VERSION ""

NS_ :

BS_:

BU_: PFAF_HS LVMPC_HS DCDC_HS AMP_HS VICM2_HS FICM_HS ARS_HS MCP_B_HS MCP_A_HS ICCM_OBD_HS SAS_HS ACCM_HS VLBS_HS EBCM_OBD_HS EDI_HS HPCC_HS VITM_OBD_HS PTAM_HS OBCM_HS VICM_HS HCP_HS FDCM_HS APPS_HS ICCM_HS EOCM_F_HS GPCM_HS FSCM_ITBC_HS SCM_HS ITBC_HS VCM_HS HMIM_HS FCP_HS VES_HS Dummy_HS MCP_C_HS RWS_HS ONSTAR_HS EPS_HS TestTool_HS MCP_HS BCP_HS ALC_HS AHL_AFL_HS SADS_HS EPB_HS FSCM_HS AFS_HS FCM_HS TCCM_HS RDCM_HS PTO_HS PCM_HS EBCM_HS ACC_HS BCM_HS TCM_HS ECM_HS

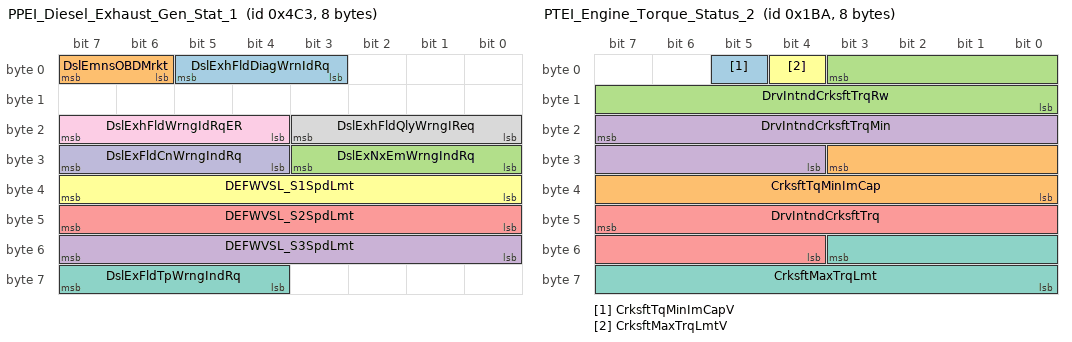
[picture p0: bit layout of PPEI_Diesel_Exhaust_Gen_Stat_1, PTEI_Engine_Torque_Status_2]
BO_ 1219 PPEI_Diesel_Exhaust_Gen_Stat_1: 8 ECM_HS
  SG_ DslExhFldDiagWrnIdRq: 5|3@0+ (1,0) [0|7] "" BCM_HS
  SG_ DslEmnsOBDMrkt: 7|2@0+ (1,0) [0|3] "" BCM_HS
  SG_ DslExNxEmWrngIndRq: 27|4@0+ (1,0) [0|15] "" BCM_HS
  SG_ DEFWVSL_S3SpdLmt: 55|8@0+ (1,0) [0|255] "km / h" BCM_HS
  SG_ DEFWVSL_S2SpdLmt: 47|8@0+ (1,0) [0|255] "km / h" BCM_HS
  SG_ DEFWVSL_S1SpdLmt: 39|8@0+ (1,0) [0|255] "km / h" BCM_HS
  SG_ DslExFldTpWrngIndRq: 63|4@0+ (1,0) [0|15] "" BCM_HS
  SG_ DslExhFldQlyWrngIReq: 19|4@0+ (1,0) [0|15] "" BCM_HS
  SG_ DslExhFldWrngIdRqER: 23|4@0+ (1,0) [0|15] "" BCM_HS FCP_HS ONSTAR_HS
  SG_ DslExFldCnWrngIndRq: 31|4@0+ (1,0) [0|15] "" BCM_HS

BO_ 372 Active_Rear_Steer_Fail_Indctn_HS: 1 ARS_HS
  SG_ ARSFlrIO: 0|1@0+ (1,0) [0|1] "" BCM_HS

BO_ 528 Brake_System_Autonomous_Info_HS: 4 EBCM_HS
  SG_ BrkSysAutBrkReqRC: 2|2@0+ (1,0) [0|3] "" FSCM_ITBC_HS
  SG_ BrkSysAutBrkReqPVal: 16|9@0+ (1,0) [0|511] "" FSCM_ITBC_HS
  SG_ BSABR_TrlBrkRq: 0|8@0+ (0.39215702,0) [0|100.00004] "%" FSCM_ITBC_HS
  SG_ BSABR_TrlBrkCntlIntRq: 8|1@0+ (1,0) [0|1] "" FSCM_ITBC_HS

BO_ 552 Thrml_Ref_Compressor_Status_1_HS: 4 ACCM_HS
  SG_ ThrmlRefCmpIGBTTmpV: 2|1@0+ (1,0) [0|1] "" VICM_HS
  SG_ ThrmlRefCmpIGBTTmp: 31|8@0+ (1,-40) [-40|215] "deg C" VICM_HS
  SG_ ThrmlRefCmpHiVltgInptV: 1|1@0+ (1,0) [0|1] "" VICM_HS
  SG_ ThrmlRefCmpHiVltgInpt: 23|8@0+ (4,0) [0|1020] "V" VICM_HS
  SG_ ThrmlRefCmpCPUHtSkTmpV: 0|1@0+ (1,0) [0|1] "" VICM_HS
  SG_ ThrmlRefCmpCPUHtSkTmp: 15|8@0+ (1,-40) [-40|215] "deg C" VICM_HS

BO_ 442 PTEI_Engine_Torque_Status_2: 8 ECM_HS
  SG_ CrksftTqMinImCapV: 5|1@0+ (1,0) [0|1] "" TCM_HS
  SG_ CrksftTqMinImCap: 27|12@0+ (0.5,-848) [-848|1199.5] "Nm" TCM_HS
  SG_ DrvIntndCrksftTrqRw: 3|12@0+ (0.5,-848) [-848|1199.5] "Nm" TCM_HS
  SG_ DrvIntndCrksftTrqMin: 23|12@0+ (0.5,-848) [-848|1199.5] "Nm" TCM_HS
  SG_ DrvIntndCrksftTrq: 47|12@0+ (0.5,-848) [-848|1199.5] "Nm" TCM_HS
  SG_ CrksftMaxTrqLmtV: 4|1@0+ (1,0) [0|1] "" TCM_HS
  SG_ CrksftMaxTrqLmt: 51|12@0+ (0.5,-848) [-848|1199.5] "Nm" TCM_HS

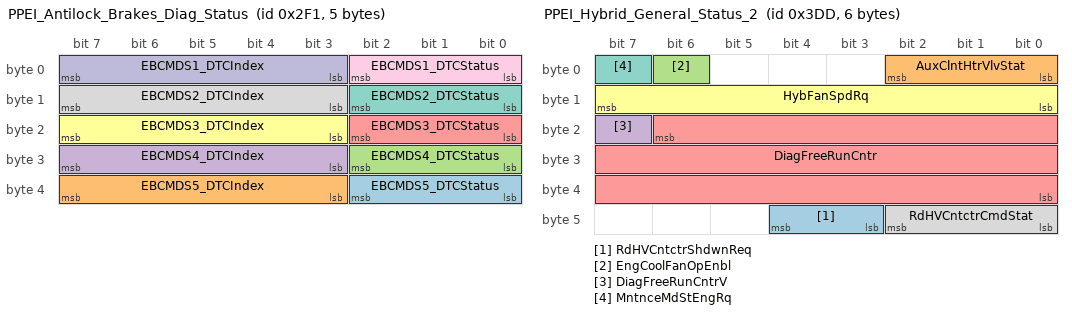
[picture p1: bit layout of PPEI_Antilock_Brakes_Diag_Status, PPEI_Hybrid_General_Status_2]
BO_ 753 PPEI_Antilock_Brakes_Diag_Status: 5 EBCM_HS
  SG_ EBCMDS5_DTCStatus: 34|3@0+ (1,0) [0|7] "" ECM_HS
  SG_ EBCMDS5_DTCIndex: 39|5@0+ (1,0) [0|31] "" ECM_HS
  SG_ EBCMDS4_DTCStatus: 26|3@0+ (1,0) [0|7] "" ECM_HS
  SG_ EBCMDS4_DTCIndex: 31|5@0+ (1,0) [0|31] "" ECM_HS
  SG_ EBCMDS3_DTCStatus: 18|3@0+ (1,0) [0|7] "" ECM_HS
  SG_ EBCMDS3_DTCIndex: 23|5@0+ (1,0) [0|31] "" ECM_HS
  SG_ EBCMDS2_DTCStatus: 10|3@0+ (1,0) [0|7] "" ECM_HS
  SG_ EBCMDS2_DTCIndex: 15|5@0+ (1,0) [0|31] "" ECM_HS
  SG_ EBCMDS1_DTCStatus: 2|3@0+ (1,0) [0|7] "" ECM_HS
  SG_ EBCMDS1_DTCIndex: 7|5@0+ (1,0) [0|31] "" ECM_HS

BO_ 989 PPEI_Hybrid_General_Status_2: 6 VICM_HS
  SG_ RdHVCntctrShdwnReq: 44|2@0+ (1,0) [0|3] "" HCP_HS
  SG_ AuxClntHtrVlvStat: 2|3@0+ (1,0) [0|7] "" PCM_HS ECM_HS
  SG_ EngCoolFanOpEnbl: 6|1@0+ (1,0) [0|1] "" PCM_HS ECM_HS
  SG_ DiagFreeRunCntrV: 23|1@0+ (1,0) [0|1] "" ECM_HS
  SG_ DiagFreeRunCntr: 22|23@0+ (1,0) [0|8388607] "min" ECM_HS
  SG_ HybFanSpdRq: 15|8@0+ (0.39215702,0) [0|100.00004] "%" PCM_HS ECM_HS
  SG_ MntnceMdStEngRq: 7|1@0+ (1,0) [0|1] "" ECM_HS
  SG_ RdHVCntctrCmdStat: 42|3@0+ (1,0) [0|7] "" HCP_HS

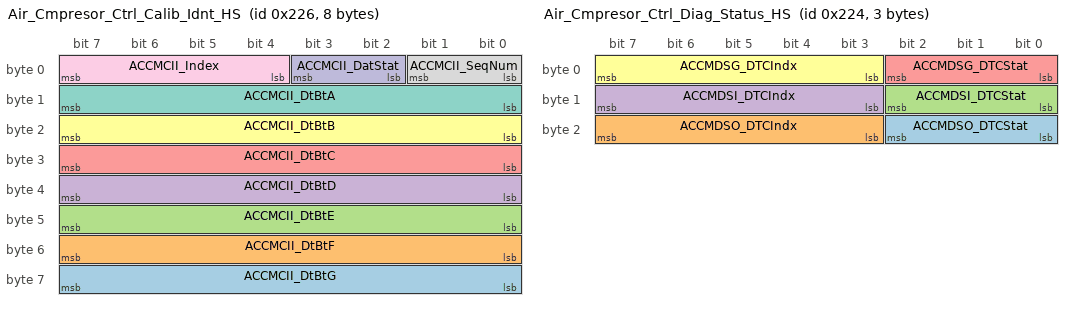
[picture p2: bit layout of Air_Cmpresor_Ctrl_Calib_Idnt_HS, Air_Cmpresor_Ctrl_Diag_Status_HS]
BO_ 550 Air_Cmpresor_Ctrl_Calib_Idnt_HS: 8 ACCM_HS
  SG_ ACCMCII_DtBtG: 63|8@0+ (1,0) [0|0] "" VICM_HS
  SG_ ACCMCII_DtBtF: 55|8@0+ (1,0) [0|0] "" VICM_HS
  SG_ ACCMCII_DtBtE: 47|8@0+ (1,0) [0|0] "" VICM_HS
  SG_ ACCMCII_DtBtD: 39|8@0+ (1,0) [0|0] "" VICM_HS
  SG_ ACCMCII_DtBtC: 31|8@0+ (1,0) [0|0] "" VICM_HS
  SG_ ACCMCII_DtBtB: 23|8@0+ (1,0) [0|0] "" VICM_HS
  SG_ ACCMCII_DtBtA: 15|8@0+ (1,0) [0|0] "" VICM_HS
  SG_ ACCMCII_SeqNum: 1|2@0+ (1,0) [0|3] "" VICM_HS
  SG_ ACCMCII_Index: 7|4@0+ (1,0) [0|15] "" VICM_HS
  SG_ ACCMCII_DatStat: 3|2@0+ (1,0) [0|3] "" VICM_HS

BO_ 548 Air_Cmpresor_Ctrl_Diag_Status_HS: 3 ACCM_HS
  SG_ ACCMDSO_DTCStat: 18|3@0+ (1,0) [0|7] "" VICM_HS
  SG_ ACCMDSO_DTCIndx: 23|5@0+ (1,0) [0|31] "" VICM_HS
  SG_ ACCMDSI_DTCStat: 10|3@0+ (1,0) [0|7] "" VICM_HS
  SG_ ACCMDSI_DTCIndx: 15|5@0+ (1,0) [0|31] "" VICM_HS
  SG_ ACCMDSG_DTCStat: 2|3@0+ (1,0) [0|7] "" VICM_HS
  SG_ ACCMDSG_DTCIndx: 7|5@0+ (1,0) [0|31] "" VICM_HS

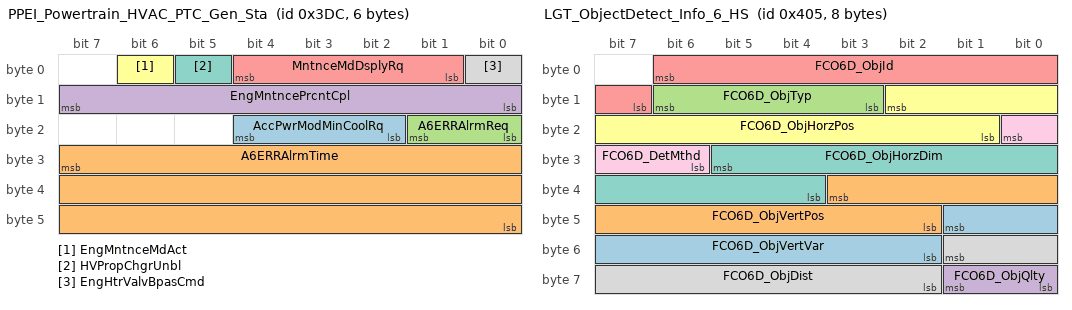
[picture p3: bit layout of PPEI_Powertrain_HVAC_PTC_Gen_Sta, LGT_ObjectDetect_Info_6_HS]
BO_ 988 PPEI_Powertrain_HVAC_PTC_Gen_Sta: 6 ECM_HS
  SG_ AccPwrModMinCoolRq: 20|3@0+ (1,0) [0|7] "" VICM_HS
  SG_ A6ERRAlrmTime: 31|24@0+ (1,0) [0|16777215] "min" VICM_HS
  SG_ A6ERRAlrmReq: 17|2@0+ (1,0) [0|3] "" VICM_HS
  SG_ EngMntncePrcntCpl: 15|8@0+ (0.39215702,0) [0|100.00004] "%" VICM_HS
  SG_ MntnceMdDsplyRq: 4|4@0+ (1,0) [0|15] "" VICM_HS
  SG_ EngMntnceMdAct: 6|1@0+ (1,0) [0|1] "" VICM_HS
  SG_ HVPropChgrUnbl: 5|1@0+ (1,0) [0|1] "" HCP_HS VICM_HS
  SG_ EngHtrValvBpasCmd: 0|1@0+ (1,0) [0|1] "" VICM_HS

BO_ 1029 LGT_ObjectDetect_Info_6_HS: 8 FCM_HS
  SG_ FCO6D_ObjVertVar: 41|8@0- (0.050000004,0) [-6.4000001|6.3500004] "deg" AHL_AFL_HS
  SG_ FCO6D_ObjVertPos: 35|10@0- (0.050000004,0) [-25.6|25.549999] "deg" AHL_AFL_HS
  SG_ FCO6D_ObjTyp: 14|4@0+ (1,0) [0|15] "" AHL_AFL_HS
  SG_ FCO6D_ObjQlty: 57|2@0+ (1,0) [0|3] "" AHL_AFL_HS
  SG_ FCO6D_ObjId: 6|8@0+ (1,0) [0|255] "" AHL_AFL_HS
  SG_ FCO6D_ObjHorzPos: 10|10@0- (0.050000004,0) [-25.6|25.549999] "deg" AHL_AFL_HS
  SG_ FCO6D_ObjHorzDim: 29|10@0+ (0.010000001,0) [0|10.23] "deg" AHL_AFL_HS
  SG_ FCO6D_ObjDist: 49|8@0+ (2,0) [0|510] "m" AHL_AFL_HS
  SG_ FCO6D_DetMthd: 16|3@0+ (1,0) [0|7] "" AHL_AFL_HS

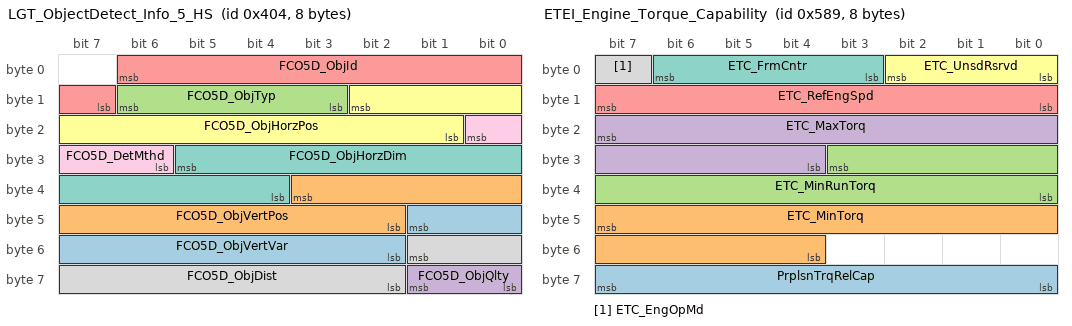
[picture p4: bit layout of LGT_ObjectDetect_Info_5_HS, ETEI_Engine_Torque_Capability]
BO_ 1028 LGT_ObjectDetect_Info_5_HS: 8 FCM_HS
  SG_ FCO5D_ObjVertVar: 41|8@0- (0.050000004,0) [-6.4000001|6.3500004] "deg" AHL_AFL_HS
  SG_ FCO5D_ObjVertPos: 35|10@0- (0.050000004,0) [-25.6|25.549999] "deg" AHL_AFL_HS
  SG_ FCO5D_ObjTyp: 14|4@0+ (1,0) [0|15] "" AHL_AFL_HS
  SG_ FCO5D_ObjQlty: 57|2@0+ (1,0) [0|3] "" AHL_AFL_HS
  SG_ FCO5D_ObjId: 6|8@0+ (1,0) [0|255] "" AHL_AFL_HS
  SG_ FCO5D_ObjHorzPos: 10|10@0- (0.050000004,0) [-25.6|25.549999] "deg" AHL_AFL_HS
  SG_ FCO5D_ObjHorzDim: 29|10@0+ (0.010000001,0) [0|10.23] "" AHL_AFL_HS
  SG_ FCO5D_ObjDist: 49|8@0+ (2,0) [0|510] "m" AHL_AFL_HS
  SG_ FCO5D_DetMthd: 16|3@0+ (1,0) [0|7] "" AHL_AFL_HS

BO_ 500 PPEI_Drv_Pref_Mode_Switch_Status: 6 ECM_HS
  SG_ EnhDrvMdSwChUseAct: 40|1@0+ (1,0) [0|1] "" EBCM_OBD_HS EBCM_HS
  SG_ EnhDrvSelMdSwStat: 42|2@0+ (1,0) [0|3] "" EBCM_OBD_HS EBCM_HS
  SG_ DrvSelMd8Stat: 17|1@0+ (1,0) [0|1] "" EBCM_OBD_HS EBCM_HS BCM_HS
  SG_ DrvSelMd8ReqDnd: 16|1@0+ (1,0) [0|1] "" BCM_HS
  SG_ DrvSelMd7Stat: 19|1@0+ (1,0) [0|1] "" EBCM_OBD_HS EBCM_HS BCM_HS
  SG_ DrvSelMd7ReqDnd: 18|1@0+ (1,0) [0|1] "" BCM_HS
  SG_ DrvSelMd6Stat: 21|1@0+ (1,0) [0|1] "" EBCM_OBD_HS EBCM_HS BCM_HS
  SG_ DrvSelMd6ReqDnd: 20|1@0+ (1,0) [0|1] "" BCM_HS
  SG_ DrvSelMd5Stat: 23|1@0+ (1,0) [0|1] "" EBCM_OBD_HS EBCM_HS BCM_HS
  SG_ DrvSelMd5ReqDnd: 22|1@0+ (1,0) [0|1] "" BCM_HS
  SG_ DrvSelMd4Stat: 9|1@0+ (1,0) [0|1] "" EBCM_OBD_HS EBCM_HS BCM_HS
  SG_ DrvSelMd4ReqDnd: 8|1@0+ (1,0) [0|1] "" BCM_HS
  SG_ DrvSelMd3Stat: 11|1@0+ (1,0) [0|1] "" EBCM_OBD_HS EBCM_HS BCM_HS
  SG_ DrvSelMd3ReqDnd: 10|1@0+ (1,0) [0|1] "" BCM_HS
  SG_ DrvSelMd2Stat: 13|1@0+ (1,0) [0|1] "" EBCM_OBD_HS EBCM_HS BCM_HS
  SG_ DrvSelMd2ReqDnd: 12|1@0+ (1,0) [0|1] "" BCM_HS
  SG_ DSMSS_DrvSelMd0Pn: 47|1@0+ (1,0) [0|1] "" EBCM_OBD_HS EBCM_HS BCM_HS
  SG_ DSMSS_DrvSelMd8Pn: 32|1@0+ (1,0) [0|1] "" EBCM_OBD_HS EBCM_HS BCM_HS
  SG_ DSMSS_DrvSelMd7Pn: 33|1@0+ (1,0) [0|1] "" EBCM_OBD_HS EBCM_HS BCM_HS
  SG_ DSMSS_DrvSelMd6Pn: 34|1@0+ (1,0) [0|1] "" EBCM_OBD_HS EBCM_HS BCM_HS
  SG_ DSMSS_DrvSelMd5Pn: 35|1@0+ (1,0) [0|1] "" EBCM_OBD_HS EBCM_HS BCM_HS
  SG_ DSMSS_DrvSelMd4Pn: 36|1@0+ (1,0) [0|1] "" EBCM_OBD_HS EBCM_HS BCM_HS
  SG_ DSMSS_DrvSelMd3Pn: 37|1@0+ (1,0) [0|1] "" EBCM_OBD_HS EBCM_HS BCM_HS
  SG_ DSMSS_DrvSelMd2Pn: 38|1@0+ (1,0) [0|1] "" EBCM_OBD_HS EBCM_HS BCM_HS
  SG_ DSMSS_DrvSelMd1Pn: 39|1@0+ (1,0) [0|1] "" EBCM_OBD_HS EBCM_HS BCM_HS
  SG_ DSMSS_DrvSelMd8Un: 24|1@0+ (1,0) [0|1] "" EBCM_OBD_HS EBCM_HS BCM_HS
  SG_ DSMSS_DrvSelMd7Un: 25|1@0+ (1,0) [0|1] "" EBCM_OBD_HS EBCM_HS BCM_HS
  SG_ DSMSS_DrvSelMd6Un: 26|1@0+ (1,0) [0|1] "" EBCM_OBD_HS EBCM_HS BCM_HS
  SG_ DSMSS_DrvSelMd5Un: 27|1@0+ (1,0) [0|1] "" EBCM_OBD_HS EBCM_HS BCM_HS
  SG_ DSMSS_DrvSelMd4Un: 28|1@0+ (1,0) [0|1] "" EBCM_OBD_HS EBCM_HS BCM_HS
  SG_ DSMSS_DrvSelMd3Un: 29|1@0+ (1,0) [0|1] "" EBCM_OBD_HS EBCM_HS BCM_HS
  SG_ DSMSS_DrvSelMd2Un: 30|1@0+ (1,0) [0|1] "" EBCM_OBD_HS EBCM_HS BCM_HS
  SG_ DSMSS_DrvSelMd1Un: 31|1@0+ (1,0) [0|1] "" EBCM_OBD_HS EBCM_HS BCM_HS
  SG_ DrvSelMd1ReqDnd: 14|1@0+ (1,0) [0|1] "" VICM_HS BCM_HS
  SG_ DrvSelMd1Stat: 15|1@0+ (1,0) [0|1] "" EBCM_OBD_HS EBCM_HS BCM_HS

BO_ 1417 ETEI_Engine_Torque_Capability: 8 ECM_HS
  SG_ PrplsnTrqRelCap: 63|8@0+ (0.5,0) [0|127.5] "%" TCM_HS
  SG_ ETC_MinTorq: 47|12@0+ (0.5,-848) [-848|1199.5] "Nm" TCM_HS HCP_HS BCP_HS
  SG_ ETC_MinRunTorq: 27|12@0+ (0.5,-848) [-848|1199.5] "Nm" TCM_HS HCP_HS BCP_HS
  SG_ ETC_MaxTorq: 23|12@0+ (0.5,-848) [-848|1199.5] "Nm" TCM_HS HCP_HS BCP_HS
  SG_ ETC_RefEngSpd: 15|8@0+ (32,0) [0|8160] "rpm" TCM_HS HCP_HS BCP_HS
  SG_ ETC_UnsdRsrvd: 2|3@0+ (1,0) [0|7] "" TCM_HS HCP_HS BCP_HS
  SG_ ETC_FrmCntr: 6|4@0+ (1,0) [0|15] "" TCM_HS HCP_HS BCP_HS
  SG_ ETC_EngOpMd: 7|1@0+ (1,0) [0|1] "" TCM_HS HCP_HS BCP_HS

BO_ 407 PTEI_Trans_Ratio_Status: 2 TCM_HS
  SG_ TrnsOvrallActTorqRatioV: 7|1@0+ (1,0) [0|1] "" PCM_HS ECM_HS
  SG_ TrnsOvrallActTorqRatio: 6|15@0- (0.00390625,0) [-64|63.996098] "" PCM_HS ECM_HS

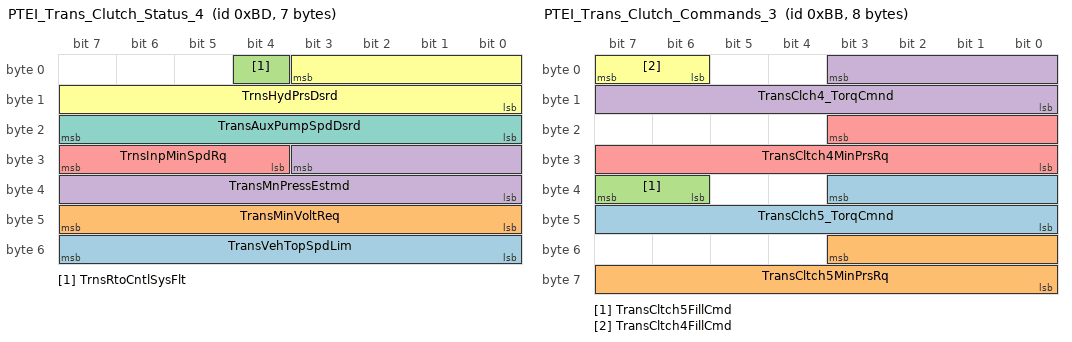
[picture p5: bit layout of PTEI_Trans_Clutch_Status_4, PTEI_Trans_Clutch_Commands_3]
BO_ 189 PTEI_Trans_Clutch_Status_4: 7 TCM_HS
  SG_ TransVehTopSpdLim: 55|8@0+ (2,0) [0|510] "km / h" PCM_HS ECM_HS
  SG_ TransMinVoltReq: 47|8@0+ (0.078430012,0) [0|19.999651] "volts" PCM_HS ECM_HS
  SG_ TrnsRtoCntlSysFlt: 4|1@0+ (1,0) [0|1] "" Vector__XXX
  SG_ TransMnPressEstmd: 27|12@0+ (0.5,0) [0|2047.5] "kPa" HCP_HS
  SG_ TrnsInpMinSpdRq: 31|4@0+ (1,0) [0|15] "" HCP_HS
  SG_ TrnsHydPrsDsrd: 3|12@0+ (0.5,0) [0|2047.5] "kPa" HCP_HS
  SG_ TransAuxPumpSpdDsrd: 23|8@0+ (0.39215702,0) [0|100.00004] "%" HCP_HS

BO_ 187 PTEI_Trans_Clutch_Commands_3: 8 HCP_HS
  SG_ TransClch5_TorqCmnd: 35|12@0+ (0.5,-5) [-5|2042.5] "Nm" TCM_HS
  SG_ TransCltch5MinPrsRq: 51|12@0+ (0.5,0) [0|2047.5] "kPa" TCM_HS
  SG_ TransCltch5FillCmd: 39|2@0+ (1,0) [0|3] "" TCM_HS
  SG_ TransClch4_TorqCmnd: 3|12@0+ (0.5,-5) [-5|2042.5] "Nm" TCM_HS
  SG_ TransCltch4MinPrsRq: 19|12@0+ (0.5,0) [0|2047.5] "kPa" TCM_HS
  SG_ TransCltch4FillCmd: 7|2@0+ (1,0) [0|3] "" TCM_HS

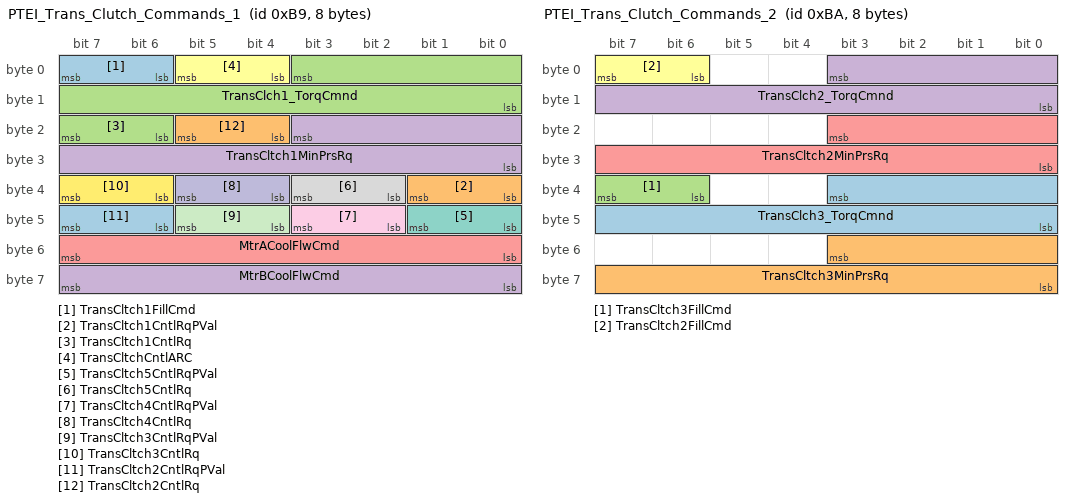
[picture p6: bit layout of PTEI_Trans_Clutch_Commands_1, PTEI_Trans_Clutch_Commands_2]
BO_ 185 PTEI_Trans_Clutch_Commands_1: 8 HCP_HS
  SG_ TransCltch1FillCmd: 7|2@0+ (1,0) [0|3] "" TCM_HS
  SG_ TransCltch1CntlRqPVal: 33|2@0+ (1,0) [0|3] "" TCM_HS
  SG_ TransCltch1CntlRq: 23|2@0+ (1,0) [0|3] "" TCM_HS
  SG_ MtrBCoolFlwCmd: 63|8@0+ (0.050000004,0) [0|12.75] "l/min" TCM_HS
  SG_ MtrACoolFlwCmd: 55|8@0+ (0.050000004,0) [0|12.75] "l/min" TCM_HS
  SG_ TransCltchCntlARC: 5|2@0+ (1,0) [0|3] "" TCM_HS
  SG_ TransCltch5CntlRqPVal: 41|2@0+ (1,0) [0|3] "" TCM_HS
  SG_ TransCltch5CntlRq: 35|2@0+ (1,0) [0|3] "" TCM_HS
  SG_ TransCltch4CntlRqPVal: 43|2@0+ (1,0) [0|3] "" TCM_HS
  SG_ TransCltch4CntlRq: 37|2@0+ (1,0) [0|3] "" TCM_HS
  SG_ TransCltch3CntlRqPVal: 45|2@0+ (1,0) [0|3] "" TCM_HS
  SG_ TransCltch3CntlRq: 39|2@0+ (1,0) [0|3] "" TCM_HS
  SG_ TransCltch2CntlRqPVal: 47|2@0+ (1,0) [0|3] "" TCM_HS
  SG_ TransCltch2CntlRq: 21|2@0+ (1,0) [0|3] "" TCM_HS
  SG_ TransClch1_TorqCmnd: 3|12@0+ (0.5,-5) [-5|2042.5] "Nm" TCM_HS
  SG_ TransCltch1MinPrsRq: 19|12@0+ (0.5,0) [0|2047.5] "kPa" TCM_HS

BO_ 186 PTEI_Trans_Clutch_Commands_2: 8 HCP_HS
  SG_ TransClch3_TorqCmnd: 35|12@0+ (0.5,-5) [-5|2042.5] "Nm" TCM_HS
  SG_ TransCltch3MinPrsRq: 51|12@0+ (0.5,0) [0|2047.5] "kPa" TCM_HS
  SG_ TransCltch3FillCmd: 39|2@0+ (1,0) [0|3] "" TCM_HS
  SG_ TransClch2_TorqCmnd: 3|12@0+ (0.5,-5) [-5|2042.5] "Nm" TCM_HS
  SG_ TransCltch2MinPrsRq: 19|12@0+ (0.5,0) [0|2047.5] "kPa" TCM_HS
  SG_ TransCltch2FillCmd: 7|2@0+ (1,0) [0|3] "" TCM_HS

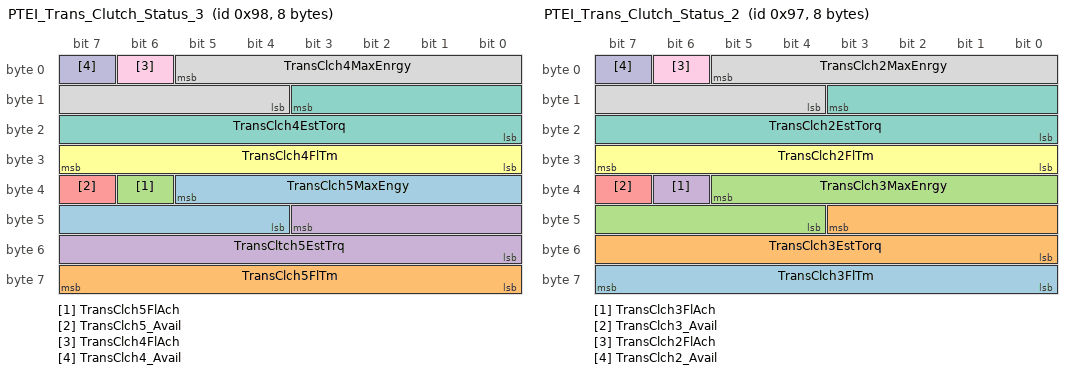
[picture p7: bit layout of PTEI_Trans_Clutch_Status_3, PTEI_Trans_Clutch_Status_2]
BO_ 152 PTEI_Trans_Clutch_Status_3: 8 TCM_HS
  SG_ TransClch5MaxEngy: 37|10@0+ (50,0) [0|51150] "J" HCP_HS
  SG_ TransClch5FlTm: 63|8@0+ (0.012500001,0) [0|3.1874998] "s" HCP_HS
  SG_ TransClch5FlAch: 38|1@0+ (1,0) [0|1] "" HCP_HS
  SG_ TransCltch5EstTrq: 43|12@0+ (0.5,-5) [-5|2042.5] "Nm" HCP_HS
  SG_ TransClch5_Avail: 39|1@0+ (1,0) [0|1] "" HCP_HS
  SG_ TransClch4FlTm: 31|8@0+ (0.012500001,0) [0|3.1874998] "s" HCP_HS
  SG_ TransClch4EstTorq: 11|12@0+ (0.5,-5) [-5|2042.5] "Nm" HCP_HS
  SG_ TransClch4MaxEnrgy: 5|10@0+ (50,0) [0|51150] "J" HCP_HS
  SG_ TransClch4FlAch: 6|1@0+ (1,0) [0|1] "" HCP_HS
  SG_ TransClch4_Avail: 7|1@0+ (1,0) [0|1] "" HCP_HS

BO_ 151 PTEI_Trans_Clutch_Status_2: 8 TCM_HS
  SG_ TransClch3FlTm: 63|8@0+ (0.012500001,0) [0|3.1874998] "s" HCP_HS
  SG_ TransClch3EstTorq: 43|12@0+ (0.5,-5) [-5|2042.5] "Nm" HCP_HS
  SG_ TransClch3MaxEnrgy: 37|10@0+ (50,0) [0|51150] "J" HCP_HS
  SG_ TransClch3FlAch: 38|1@0+ (1,0) [0|1] "" HCP_HS
  SG_ TransClch3_Avail: 39|1@0+ (1,0) [0|1] "" HCP_HS
  SG_ TransClch2FlTm: 31|8@0+ (0.012500001,0) [0|3.1874998] "s" HCP_HS
  SG_ TransClch2EstTorq: 11|12@0+ (0.5,-5) [-5|2042.5] "Nm" HCP_HS
  SG_ TransClch2MaxEnrgy: 5|10@0+ (50,0) [0|51150] "J" HCP_HS
  SG_ TransClch2FlAch: 6|1@0+ (1,0) [0|1] "" HCP_HS
  SG_ TransClch2_Avail: 7|1@0+ (1,0) [0|1] "" HCP_HS

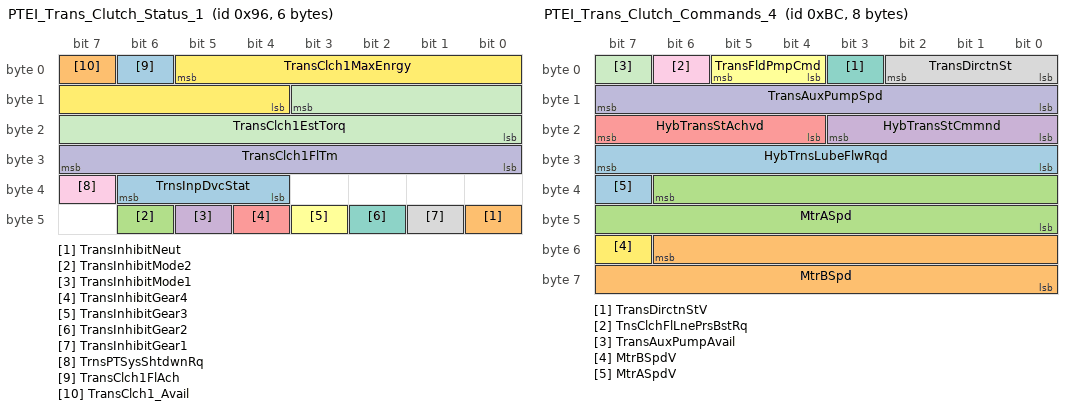
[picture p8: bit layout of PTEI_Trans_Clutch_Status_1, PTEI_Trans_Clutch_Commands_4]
BO_ 150 PTEI_Trans_Clutch_Status_1: 6 TCM_HS
  SG_ TrnsInpDvcStat: 38|3@0+ (1,0) [0|7] "" HCP_HS
  SG_ TransInhibitNeut: 40|1@0+ (1,0) [0|1] "" HCP_HS
  SG_ TransInhibitMode2: 46|1@0+ (1,0) [0|1] "" HCP_HS
  SG_ TransInhibitMode1: 45|1@0+ (1,0) [0|1] "" HCP_HS
  SG_ TransInhibitGear4: 44|1@0+ (1,0) [0|1] "" HCP_HS
  SG_ TransInhibitGear3: 43|1@0+ (1,0) [0|1] "" HCP_HS
  SG_ TransInhibitGear2: 42|1@0+ (1,0) [0|1] "" HCP_HS
  SG_ TransInhibitGear1: 41|1@0+ (1,0) [0|1] "" HCP_HS
  SG_ TrnsPTSysShtdwnRq: 39|1@0+ (1,0) [0|1] "" HCP_HS
  SG_ TransClch1FlTm: 31|8@0+ (0.012500001,0) [0|3.1874998] "s" HCP_HS
  SG_ TransClch1EstTorq: 11|12@0+ (0.5,-5) [-5|2042.5] "Nm" HCP_HS
  SG_ TransClch1MaxEnrgy: 5|10@0+ (50,0) [0|51150] "J" HCP_HS
  SG_ TransClch1FlAch: 6|1@0+ (1,0) [0|1] "" HCP_HS
  SG_ TransClch1_Avail: 7|1@0+ (1,0) [0|1] "" HCP_HS

BO_ 188 PTEI_Trans_Clutch_Commands_4: 8 HCP_HS
  SG_ HybTrnsLubeFlwRqd: 31|8@0+ (0.0625,0) [0|15.937499] "l/min" TCM_HS
  SG_ MtrBSpd: 54|15@0- (1,0) [-16384|16383] "rpm" PFAF_HS TCM_HS
  SG_ MtrASpd: 38|15@0- (1,0) [-16384|16383] "rpm" TCM_HS
  SG_ HybTransStCmmnd: 19|4@0+ (1,0) [0|15] "" TCM_HS
  SG_ HybTransStAchvd: 23|4@0+ (1,0) [0|15] "" TCM_HS
  SG_ TransFldPmpCmd: 5|2@0+ (1,0) [0|3] "" TCM_HS
  SG_ TransDirctnStV: 3|1@0+ (1,0) [0|1] "" TCM_HS
  SG_ TransDirctnSt: 2|3@0+ (1,0) [0|7] "" TCM_HS
  SG_ TnsClchFlLnePrsBstRq: 6|1@0+ (1,0) [0|1] "" TCM_HS
  SG_ TransAuxPumpSpd: 15|8@0+ (0.39215702,0) [0|100.00004] "%" TCM_HS
  SG_ TransAuxPumpAvail: 7|1@0+ (1,0) [0|1] "" TCM_HS
  SG_ MtrBSpdV: 55|1@0+ (1,0) [0|1] "" PFAF_HS TCM_HS
  SG_ MtrASpdV: 39|1@0+ (1,0) [0|1] "" TCM_HS

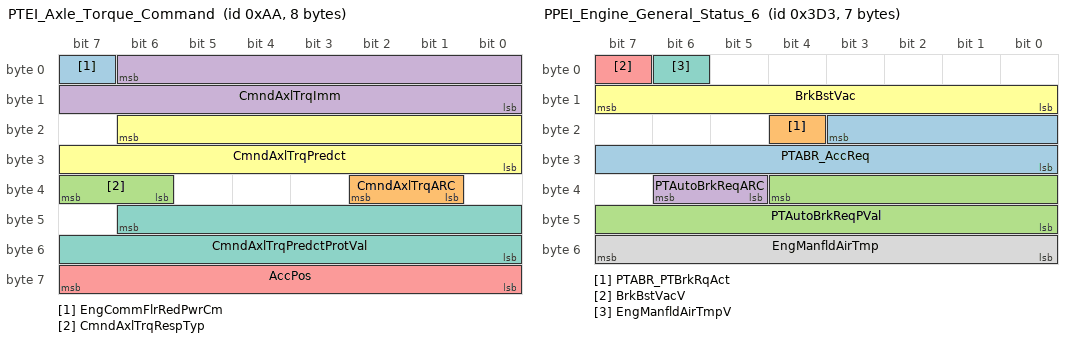
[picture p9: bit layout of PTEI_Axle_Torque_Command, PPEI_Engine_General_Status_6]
BO_ 170 PTEI_Axle_Torque_Command: 8 ECM_HS
  SG_ EngCommFlrRedPwrCm: 7|1@0+ (1,0) [0|1] "" HCP_HS
  SG_ CmndAxlTrqARC: 34|2@0+ (1,0) [0|3] "" HCP_HS EBCM_OBD_HS EBCM_HS
  SG_ CmndAxlTrqRespTyp: 39|2@0+ (1,0) [0|3] "" HCP_HS
  SG_ CmndAxlTrqImm: 6|15@0+ (2,-22534) [-22534|43000] "Nm" HCP_HS
  SG_ AccPos: 63|8@0+ (0.39215702,0) [0|100.00004] "%" HCP_HS TCM_HS
  SG_ CmndAxlTrqPredct: 22|15@0+ (2,-22534) [-22534|43000] "Nm" EBCM_OBD_HS EBCM_HS HCP_HS
  SG_ CmndAxlTrqPredctProtVal: 46|15@0+ (1,0) [0|32767] "" EBCM_OBD_HS EBCM_HS HCP_HS

BO_ 1221 PPEI_Platform_Eng_Cntrl_Req_2: 5 BCM_HS
  SG_ SpdLmtVsnFsdSpdUnt: 39|1@0+ (1,0) [0|1] "" ECM_HS
  SG_ SpdLmtVnFsSpdNwDet: 37|1@0+ (1,0) [0|1] "" ECM_HS
  SG_ SpdLmtVsnFsdSpdM: 38|1@0+ (1,0) [0|1] "" ECM_HS
  SG_ SpdLmtVsnFsdSpd: 31|8@0+ (1,0) [0|255] "" ECM_HS
  SG_ CCClntCrcFlwRtReq: 23|8@0+ (0.39215702,0) [0|100.00004] "%" VICM2_HS PCM_HS ECM_HS
  SG_ PFFanSpdPrcntRq: 15|8@0+ (0.39215702,0) [0|100.00004] "%" PCM_HS ECM_HS

BO_ 1243 PPEI_Chassis_Sys_General_Status: 3 FSCM_HS
  SG_ CSERDTC_CdNum: 11|12@0+ (1,0) [0|4095] "" ECM_HS
  SG_ CSERDTC_SysDes: 15|4@0+ (1,0) [0|15] "" ECM_HS
  SG_ ChsSysEmmRelMalfAct: 7|1@0+ (1,0) [0|1] "" ECM_HS

BO_ 979 PPEI_Engine_General_Status_6: 7 ECM_HS
  SG_ PTABR_AccReq: 19|12@0- (0.010000001,0) [-20.48|20.469999] "m/s^2" TCM_HS EBCM_OBD_HS EBCM_HS
  SG_ PTABR_PTBrkRqAct: 20|1@0+ (1,0) [0|1] "" TCM_HS EBCM_OBD_HS EBCM_HS
  SG_ PTAutoBrkReqPVal: 36|13@0+ (1,0) [0|8191] "" EBCM_OBD_HS EBCM_HS
  SG_ PTAutoBrkReqARC: 38|2@0+ (1,0) [0|3] "" EBCM_OBD_HS EBCM_HS
  SG_ BrkBstVacV: 7|1@0+ (1,0) [0|1] "" EBCM_OBD_HS EBCM_HS
  SG_ BrkBstVac: 15|8@0+ (0.5,0) [0|127.5] "kPa" EBCM_OBD_HS EBCM_HS
  SG_ EngManfldAirTmpV: 6|1@0+ (1,0) [0|1] "" BCM_HS
  SG_ EngManfldAirTmp: 55|8@0+ (1,-40) [-40|215] "deg C" BCM_HS

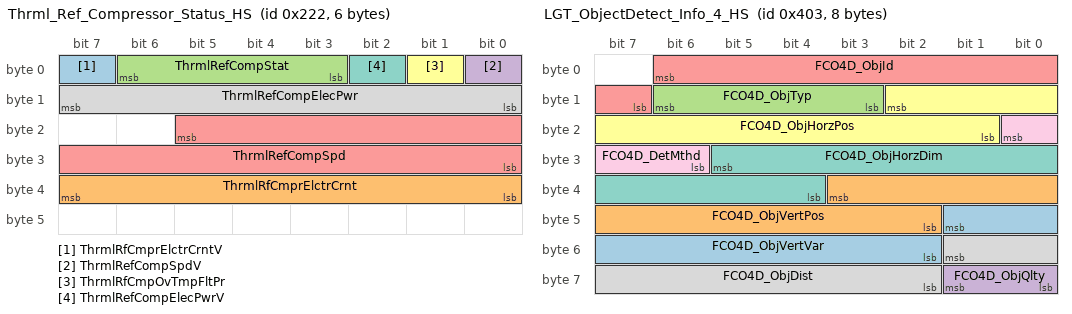
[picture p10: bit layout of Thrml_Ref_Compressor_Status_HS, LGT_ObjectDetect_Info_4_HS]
BO_ 546 Thrml_Ref_Compressor_Status_HS: 6 ACCM_HS
  SG_ ThrmlRfCmprElctrCrntV: 7|1@0+ (1,0) [0|1] "" VICM_HS
  SG_ ThrmlRfCmprElctrCrnt: 39|8@0+ (0.2,0) [0|51] "A" VICM_HS
  SG_ ThrmlRefCompStat: 6|4@0+ (1,0) [0|15] "" VICM_HS
  SG_ ThrmlRefCompSpdV: 0|1@0+ (1,0) [0|1] "" ECM_HS VICM_HS
  SG_ ThrmlRefCompSpd: 21|14@0+ (1,0) [0|16383] "rpm" ECM_HS VICM_HS
  SG_ ThrmlRfCmpOvTmpFltPr: 1|1@0+ (1,0) [0|1] "" VICM_HS
  SG_ ThrmlRefCompElecPwrV: 2|1@0+ (1,0) [0|1] "" VICM_HS
  SG_ ThrmlRefCompElecPwr: 15|8@0+ (0.040000003,0) [0|10.2] "kW" VICM_HS

BO_ 530 Veh_Theft_Notify_Reset_Req_HS: 1 VLBS_HS
  SG_ RstVTDTmprDtctd: 0|1@0+ (1,0) [0|1] "" BCM_HS
  SG_ RstIllDrIdDevDtctd: 1|1@0+ (1,0) [0|1] "" BCM_HS
  SG_ RstDrIdDevLrnd: 2|1@0+ (1,0) [0|1] "" BCM_HS

BO_ 1239 PPEI_IBS_Battery_Status_2: 5 BCM_HS
  SG_ IntlgntBattSnsBattSOC: 39|8@0+ (0.39215702,0) [0|100.00004] "%" ECM_HS
  SG_ BattTemp: 15|8@0+ (1,-40) [-40|215] "deg C" ECM_HS
  SG_ BatSOH: 31|8@0+ (0.39215702,0) [0|100.00004] "%" ECM_HS
  SG_ BatSOFVolt: 23|8@0+ (0.050000004,0) [0|12.75] "volts" ECM_HS
  SG_ BattSOXStat: 0|1@0+ (1,0) [0|1] "" ECM_HS
  SG_ BattTempV: 1|1@0+ (1,0) [0|1] "" ECM_HS

BO_ 1610 USDT_Resp_From_SAS_HS: 8 SAS_HS
  SG_ DgnInf: 7|64@0+ (1,0) [0|1.8446742e+19] "" FCP_HS ONSTAR_HS TestTool_HS

BO_ 1027 LGT_ObjectDetect_Info_4_HS: 8 FCM_HS
  SG_ FCO4D_ObjVertVar: 41|8@0- (0.050000004,0) [-6.4000001|6.3500004] "deg" AHL_AFL_HS
  SG_ FCO4D_ObjVertPos: 35|10@0- (0.050000004,0) [-25.6|25.549999] "" AHL_AFL_HS
  SG_ FCO4D_ObjTyp: 14|4@0+ (1,0) [0|15] "" AHL_AFL_HS
  SG_ FCO4D_ObjQlty: 57|2@0+ (1,0) [0|3] "" AHL_AFL_HS
  SG_ FCO4D_ObjId: 6|8@0+ (1,0) [0|255] "" AHL_AFL_HS
  SG_ FCO4D_ObjHorzPos: 10|10@0- (0.050000004,0) [-25.6|25.549999] "" AHL_AFL_HS
  SG_ FCO4D_ObjHorzDim: 29|10@0+ (0.010000001,0) [0|10.23] "deg" AHL_AFL_HS
  SG_ FCO4D_ObjDist: 49|8@0+ (2,0) [0|510] "m" AHL_AFL_HS
  SG_ FCO4D_DetMthd: 16|3@0+ (1,0) [0|7] "" AHL_AFL_HS

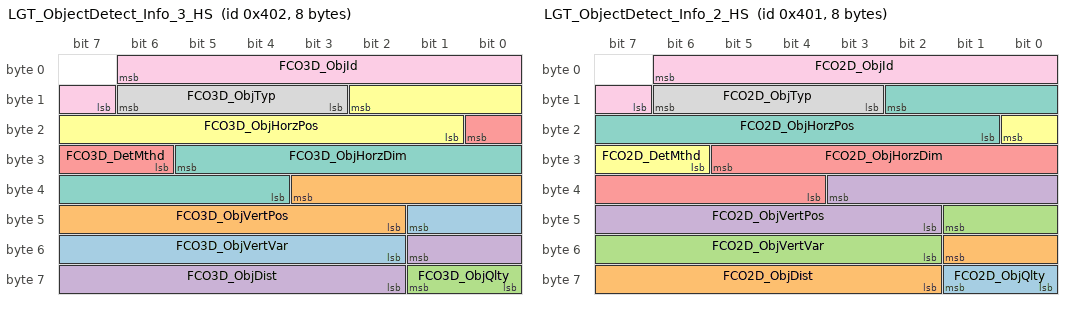
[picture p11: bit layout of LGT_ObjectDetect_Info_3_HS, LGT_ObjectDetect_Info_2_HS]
BO_ 1026 LGT_ObjectDetect_Info_3_HS: 8 FCM_HS
  SG_ FCO3D_ObjVertVar: 41|8@0- (0.050000004,0) [-6.4000001|6.3500004] "deg" AHL_AFL_HS
  SG_ FCO3D_ObjVertPos: 35|10@0- (0.050000004,0) [-25.6|25.549999] "deg" AHL_AFL_HS
  SG_ FCO3D_ObjQlty: 57|2@0+ (1,0) [0|3] "" AHL_AFL_HS
  SG_ FCO3D_ObjDist: 49|8@0+ (2,0) [0|510] "m" AHL_AFL_HS
  SG_ FCO3D_DetMthd: 16|3@0+ (1,0) [0|7] "" AHL_AFL_HS
  SG_ FCO3D_ObjHorzPos: 10|10@0- (0.050000004,0) [-25.6|25.549999] "deg" AHL_AFL_HS
  SG_ FCO3D_ObjHorzDim: 29|10@0+ (0.010000001,0) [0|10.23] "deg" AHL_AFL_HS
  SG_ FCO3D_ObjTyp: 14|4@0+ (1,0) [0|15] "" AHL_AFL_HS
  SG_ FCO3D_ObjId: 6|8@0+ (1,0) [0|255] "" AHL_AFL_HS

BO_ 1025 LGT_ObjectDetect_Info_2_HS: 8 FCM_HS
  SG_ FCO2D_ObjQlty: 57|2@0+ (1,0) [0|3] "" AHL_AFL_HS
  SG_ FCO2D_ObjDist: 49|8@0+ (2,0) [0|510] "m" AHL_AFL_HS
  SG_ FCO2D_ObjVertVar: 41|8@0- (0.050000004,0) [-6.4000001|6.3500004] "deg" AHL_AFL_HS
  SG_ FCO2D_ObjVertPos: 35|10@0- (0.050000004,0) [-25.6|25.549999] "deg" AHL_AFL_HS
  SG_ FCO2D_ObjHorzDim: 29|10@0+ (0.010000001,0) [0|10.23] "deg" AHL_AFL_HS
  SG_ FCO2D_DetMthd: 16|3@0+ (1,0) [0|7] "" AHL_AFL_HS
  SG_ FCO2D_ObjHorzPos: 10|10@0- (0.050000004,0) [-25.6|25.549999] "deg" AHL_AFL_HS
  SG_ FCO2D_ObjTyp: 14|4@0+ (1,0) [0|15] "" AHL_AFL_HS
  SG_ FCO2D_ObjId: 6|8@0+ (1,0) [0|255] "" AHL_AFL_HS

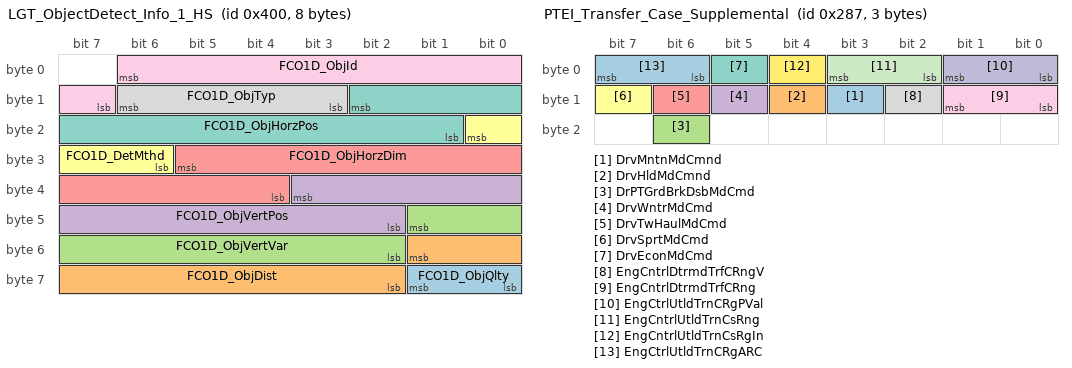
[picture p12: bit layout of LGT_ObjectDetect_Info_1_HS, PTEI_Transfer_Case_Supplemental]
BO_ 1024 LGT_ObjectDetect_Info_1_HS: 8 FCM_HS
  SG_ FCO1D_ObjQlty: 57|2@0+ (1,0) [0|3] "" AHL_AFL_HS
  SG_ FCO1D_ObjDist: 49|8@0+ (2,0) [0|510] "m" AHL_AFL_HS
  SG_ FCO1D_ObjVertVar: 41|8@0- (0.050000004,0) [-6.4000001|6.3500004] "deg" AHL_AFL_HS
  SG_ FCO1D_ObjVertPos: 35|10@0- (0.050000004,0) [-25.6|25.549999] "deg" AHL_AFL_HS
  SG_ FCO1D_ObjHorzDim: 29|10@0+ (0.010000001,0) [0|10.23] "deg" AHL_AFL_HS
  SG_ FCO1D_DetMthd: 16|3@0+ (1,0) [0|7] "" AHL_AFL_HS
  SG_ FCO1D_ObjHorzPos: 10|10@0- (0.050000004,0) [-25.6|25.549999] "deg" AHL_AFL_HS
  SG_ FCO1D_ObjTyp: 14|4@0+ (1,0) [0|15] "" AHL_AFL_HS
  SG_ FCO1D_ObjId: 6|8@0+ (1,0) [0|255] "" AHL_AFL_HS

BO_ 508 PPEI_Long_Lat_Sensor_Data_HS: 8 EBCM_HS
  SG_ LonLatAccSnsChk: 50|11@0+ (1,0) [0|2047] "" ICCM_OBD_HS ICCM_HS TCM_HS
  SG_ LonLatAccSnsValARC: 55|2@0+ (1,0) [0|3] "" ICCM_OBD_HS ICCM_HS TCM_HS
  SG_ LatAccSnsVal: 23|16@0- (0.00012207001,0) [-3.99999|3.9998677] "g's" ICCM_OBD_HS ICCM_HS TCM_HS
  SG_ LonAccSnsVal: 7|16@0- (0.00012207001,0) [-3.99999|3.9998677] "g's" ICCM_OBD_HS ICCM_HS TCM_HS
  SG_ CSTBATS_TrqVl: 37|14@0+ (2,0) [0|32766] "Nm" ICCM_OBD_HS ICCM_HS TCM_HS
  SG_ CSTBATS_TrqVlV: 38|1@0+ (1,0) [0|1] "" ICCM_OBD_HS ICCM_HS TCM_HS

BO_ 422 PTEI_Hybrid_Trans_Status_2: 1 TCM_HS
  SG_ TrStPTGrdBrkDsMdOvr: 5|2@0+ (1,0) [0|3] "" PCM_HS ECM_HS
  SG_ TrnsHybEngSrtStpOvrd: 7|2@0+ (1,0) [0|3] "" BCP_HS

BO_ 647 PTEI_Transfer_Case_Supplemental: 3 ECM_HS
  SG_ DrvMntnMdCmnd: 11|1@0+ (1,0) [0|1] "" HCP_HS
  SG_ DrvHldMdCmnd: 12|1@0+ (1,0) [0|1] "" HCP_HS
  SG_ DrPTGrdBrkDsbMdCmd: 22|1@0+ (1,0) [0|1] "" TCM_HS
  SG_ DrvWntrMdCmd: 13|1@0+ (1,0) [0|1] "" TCM_HS
  SG_ DrvTwHaulMdCmd: 14|1@0+ (1,0) [0|1] "" TCM_HS
  SG_ DrvSprtMdCmd: 15|1@0+ (1,0) [0|1] "" TCM_HS HCP_HS
  SG_ DrvEconMdCmd: 5|1@0+ (1,0) [0|1] "" TCM_HS
  SG_ EngCntrlDtrmdTrfCRngV: 10|1@0+ (1,0) [0|1] "" ICCM_OBD_HS ICCM_HS TCM_HS
  SG_ EngCntrlDtrmdTrfCRng: 9|2@0+ (1,0) [0|3] "" ICCM_OBD_HS ICCM_HS TCM_HS
  SG_ EngCtrlUtldTrnCRgPVal: 1|2@0+ (1,0) [0|3] "" EBCM_OBD_HS EBCM_HS HCP_HS
  SG_ EngCntrlUtldTrnCsRng: 3|2@0+ (1,0) [0|3] "" EBCM_OBD_HS EBCM_HS BCP_HS HCP_HS
  SG_ EngCntrlUtldTrnCsRgIn: 4|1@0+ (1,0) [0|1] "" EBCM_OBD_HS EBCM_HS HCP_HS
  SG_ EngCtrlUtldTrnCRgARC: 7|2@0+ (1,0) [0|3] "" EBCM_OBD_HS EBCM_HS HCP_HS

BO_ 368 Environment_Id_Resp_5_HS: 3 ONSTAR_HS
  SG_ EnvIdRspSt5: 17|2@0+ (1,0) [0|3] "" BCM_HS
  SG_ EnvIdRsp5: 7|16@0+ (1,0) [0|65535] "" BCM_HS

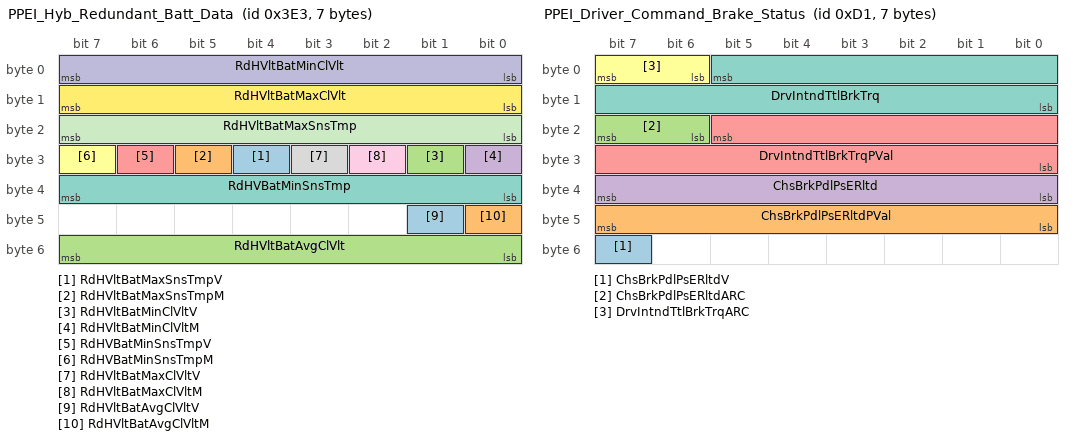
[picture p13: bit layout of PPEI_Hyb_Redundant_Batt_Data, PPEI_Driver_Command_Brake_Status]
BO_ 995 PPEI_Hyb_Redundant_Batt_Data: 7 VITM_OBD_HS
  SG_ RdHVltBatMaxSnsTmpV: 28|1@0+ (1,0) [0|1] "" VICM_HS
  SG_ RdHVltBatMaxSnsTmpM: 29|1@0+ (1,0) [0|1] "" VICM_HS
  SG_ RdHVltBatMinClVltV: 25|1@0+ (1,0) [0|1] "" VICM_HS
  SG_ RdHVltBatMinClVltM: 24|1@0+ (1,0) [0|1] "" VICM_HS
  SG_ RdHVBatMinSnsTmpV: 30|1@0+ (1,0) [0|1] "" VICM_HS
  SG_ RdHVBatMinSnsTmpM: 31|1@0+ (1,0) [0|1] "" VICM_HS
  SG_ RdHVBatMinSnsTmp: 39|8@0+ (0.5,-40) [-40|87.5] "deg C" VICM_HS
  SG_ RdHVltBatMaxClVltV: 27|1@0+ (1,0) [0|1] "" VICM_HS
  SG_ RdHVltBatMaxClVltM: 26|1@0+ (1,0) [0|1] "" VICM_HS
  SG_ RdHVltBatMinClVlt: 7|8@0+ (0.020000001,0) [0|5.0999999] "V" VICM_HS
  SG_ RdHVltBatMaxSnsTmp: 23|8@0+ (0.5,-40) [-40|87.5] "deg C" VICM_HS
  SG_ RdHVltBatMaxClVlt: 15|8@0+ (0.020000001,0) [0|5.0999999] "V" VICM_HS
  SG_ RdHVltBatAvgClVltV: 41|1@0+ (1,0) [0|1] "" VICM_HS
  SG_ RdHVltBatAvgClVltM: 40|1@0+ (1,0) [0|1] "" VICM_HS
  SG_ RdHVltBatAvgClVlt: 55|8@0+ (0.020000001,0) [0|5.0999999] "volts" VICM_HS

BO_ 971 PPEI_IBS_Battery_Status_1: 6 BCM_HS
  SG_ BatVltHiResV: 7|1@0+ (1,0) [0|1] "" ECM_HS
  SG_ BatVltHiRes: 6|15@0+ (0.001,0) [0|32.767002] "volts" ECM_HS
  SG_ BCHR_BattCrntRwVal: 37|14@0+ (0.001,-8.1920004) [-8.1920004|8.1910009] "" ECM_HS
  SG_ BCHR_BattCrntRwVlMu: 39|2@0+ (1,0) [0|3] "" ECM_HS
  SG_ BCHR_BattCrntRwValV: 24|1@0+ (1,0) [0|1] "" ECM_HS

BO_ 209 PPEI_Driver_Command_Brake_Status: 7 EBCM_HS
  SG_ ChsBrkPdlPsERltdV: 55|1@0+ (1,0) [0|1] "" ECM_HS
  SG_ ChsBrkPdlPsERltdPVal: 47|8@0+ (1,0) [0|255] "" ECM_HS
  SG_ ChsBrkPdlPsERltdARC: 23|2@0+ (1,0) [0|3] "" ECM_HS
  SG_ ChsBrkPdlPsERltd: 39|8@0+ (0.39215702,0) [0|100.00004] "%" ECM_HS
  SG_ DrvIntndTtlBrkTrqPVal: 21|14@0+ (1,0) [0|16383] "" ECM_HS
  SG_ DrvIntndTtlBrkTrqARC: 7|2@0+ (1,0) [0|3] "" ECM_HS
  SG_ DrvIntndTtlBrkTrq: 5|14@0+ (2,0) [0|32766] "Nm" ECM_HS HCP_HS VICM_HS

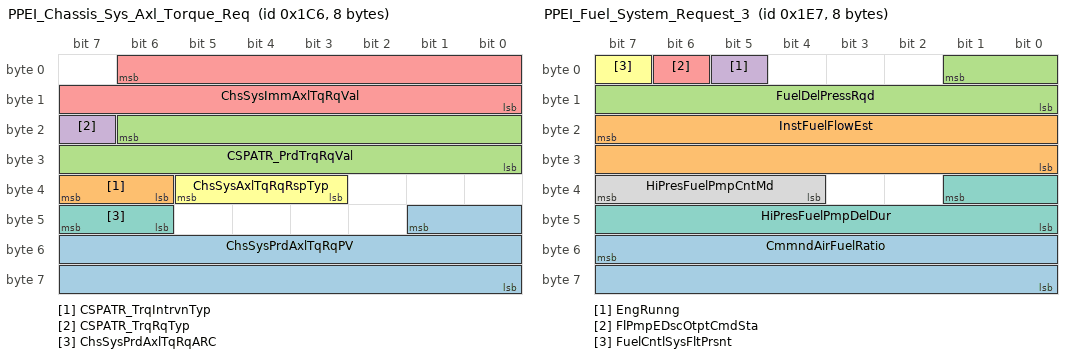
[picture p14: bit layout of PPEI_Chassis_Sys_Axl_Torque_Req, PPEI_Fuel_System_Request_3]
BO_ 454 PPEI_Chassis_Sys_Axl_Torque_Req: 8 EBCM_HS
  SG_ ChsSysPrdAxlTqRqPV: 41|18@0+ (1,0) [0|262143] "" ECM_HS
  SG_ CSPATR_TrqIntrvnTyp: 39|2@0+ (1,0) [0|3] "" ECM_HS
  SG_ CSPATR_PrdTrqRqVal: 22|15@0+ (2,-22534) [-22534|43000] "Nm" ECM_HS
  SG_ CSPATR_TrqRqTyp: 23|1@0+ (1,0) [0|1] "" ECM_HS
  SG_ ChsSysImmAxlTqRqVal: 6|15@0+ (2,-22534) [-22534|43000] "Nm" ECM_HS
  SG_ ChsSysAxlTqRqRspTyp: 37|3@0+ (1,0) [0|7] "" ECM_HS
  SG_ ChsSysPrdAxlTqRqARC: 47|2@0+ (1,0) [0|3] "" ECM_HS

BO_ 554 Electric_Park_Brake_Status_HS: 2 EPB_HS
  SG_ ElecPrkBrkApplStatPV: 13|2@0+ (1,0) [0|3] "" VICM_HS EBCM_OBD_HS EBCM_HS
  SG_ ElecPrkBrkAvailStatPV: 2|3@0+ (1,0) [0|7] "" VICM_HS EBCM_OBD_HS EBCM_HS
  SG_ ElecPrkBrkAvailStat: 5|3@0+ (1,0) [0|7] "" VICM_HS EBCM_OBD_HS EBCM_HS
  SG_ ElecPrkBrkStatRC: 7|2@0+ (1,0) [0|3] "" VICM_HS EBCM_OBD_HS EBCM_HS
  SG_ ElecPrkBrkApplStat: 15|2@0+ (1,0) [0|3] "" VICM_HS EBCM_OBD_HS EBCM_HS

BO_ 487 PPEI_Fuel_System_Request_3: 8 ECM_HS
  SG_ CmmndAirFuelRatio: 55|16@0+ (0.00048828102,0) [0|31.999496] "" ICCM_OBD_HS ICCM_HS FSCM_ITBC_HS FSCM_HS
  SG_ InstFuelFlowEst: 23|16@0+ (0.00097656203,0) [0|63.998993] "grams/s" ICCM_OBD_HS ICCM_HS FSCM_ITBC_HS FSCM_HS
  SG_ FuelDelPressRqd: 1|10@0+ (1,0) [0|1023] "kPa" ICCM_OBD_HS ICCM_HS FSCM_ITBC_HS FSCM_HS
  SG_ EngRunng: 5|1@0+ (1,0) [0|1] "" ICCM_OBD_HS ICCM_HS FSCM_ITBC_HS FSCM_HS
  SG_ FlPmpEDscOtptCmdSta: 6|1@0+ (1,0) [0|1] "" ICCM_OBD_HS ICCM_HS FSCM_ITBC_HS FSCM_HS
  SG_ FuelCntlSysFltPrsnt: 7|1@0+ (1,0) [0|1] "" ICCM_OBD_HS ICCM_HS FSCM_ITBC_HS FSCM_HS
  SG_ HiPresFuelPmpDelDur: 33|10@0+ (1,0) [0|1023] "deg" ICCM_OBD_HS ICCM_HS FSCM_ITBC_HS FSCM_HS
  SG_ HiPresFuelPmpCntMd: 39|4@0+ (1,0) [0|15] "" ICCM_OBD_HS ICCM_HS FSCM_ITBC_HS FSCM_HS

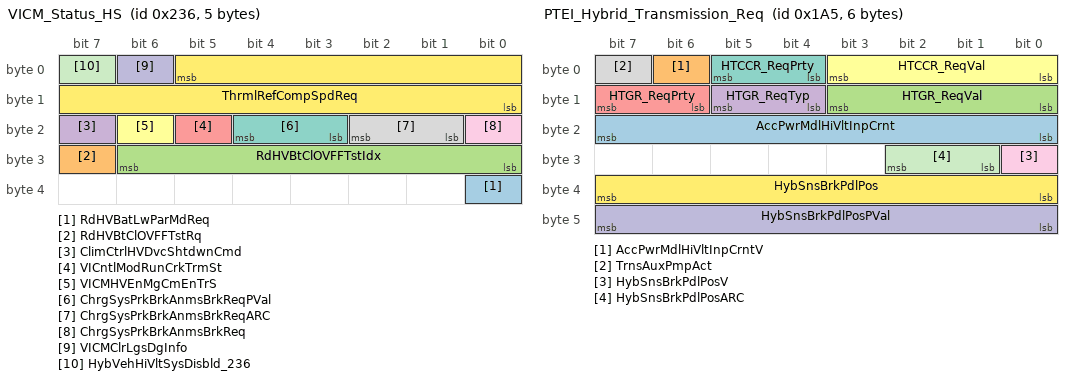
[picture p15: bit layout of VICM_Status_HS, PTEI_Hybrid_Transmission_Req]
BO_ 566 VICM_Status_HS: 5 VICM_HS
  SG_ RdHVBatLwParMdReq: 32|1@0+ (1,0) [0|1] "" VITM_OBD_HS
  SG_ RdHVBtClOVFFTstRq: 31|1@0+ (1,0) [0|1] "" VITM_OBD_HS
  SG_ RdHVBtClOVFFTstIdx: 30|7@0+ (1,0) [0|127] "" VITM_OBD_HS
  SG_ ClimCtrlHVDvcShtdwnCmd: 23|1@0+ (1,0) [0|1] "" ACCM_HS
  SG_ VICntlModRunCrkTrmSt: 21|1@0+ (1,0) [0|1] "" ACCM_HS
  SG_ VICMHVEnMgCmEnTrS: 22|1@0+ (1,0) [0|1] "" VICM2_HS VITM_OBD_HS OBCM_HS
  SG_ ChrgSysPrkBrkAnmsBrkReqPVal: 20|2@0+ (1,0) [0|3] "" EPB_HS
  SG_ ChrgSysPrkBrkAnmsBrkReqARC: 18|2@0+ (1,0) [0|3] "" EPB_HS
  SG_ ChrgSysPrkBrkAnmsBrkReq: 16|1@0+ (1,0) [0|1] "" EPB_HS
  SG_ VICMClrLgsDgInfo: 6|1@0+ (1,0) [0|1] "" ACCM_HS
  SG_ HybVehHiVltSysDisbld_236: 7|1@0+ (1,0) [0|1] "" FCP_HS ONSTAR_HS
  SG_ ThrmlRefCompSpdReq: 5|14@0+ (1,0) [0|16383] "rpm" ACCM_HS

BO_ 421 PTEI_Hybrid_Transmission_Req: 6 BCP_HS
  SG_ AccPwrMdlHiVltInpCrnt: 23|8@0+ (0.125,-5) [-5|26.874998] "A" MCP_HS
  SG_ AccPwrMdlHiVltInpCrntV: 6|1@0+ (1,0) [0|1] "" MCP_HS
  SG_ HTGR_ReqVal: 11|4@0+ (1,0) [0|15] "" TCM_HS
  SG_ HTGR_ReqTyp: 13|2@0+ (1,0) [0|3] "" TCM_HS
  SG_ HTGR_ReqPrty: 15|2@0+ (1,0) [0|3] "" TCM_HS
  SG_ HTCCR_ReqVal: 3|4@0+ (1,0) [0|15] "" TCM_HS
  SG_ HTCCR_ReqPrty: 5|2@0+ (1,0) [0|3] "" TCM_HS
  SG_ TrnsAuxPmpAct: 7|1@0+ (1,0) [0|1] "" TCM_HS
  SG_ HybSnsBrkPdlPosV: 24|1@0+ (1,0) [0|1] "" TCM_HS PCM_HS ECM_HS
  SG_ HybSnsBrkPdlPosPVal: 47|8@0+ (1,0) [0|255] "" TCM_HS PCM_HS ECM_HS
  SG_ HybSnsBrkPdlPosARC: 26|2@0+ (1,0) [0|3] "" TCM_HS PCM_HS ECM_HS
  SG_ HybSnsBrkPdlPos: 39|8@0+ (0.39215702,0) [0|100.00004] "%" TCM_HS PCM_HS ECM_HS

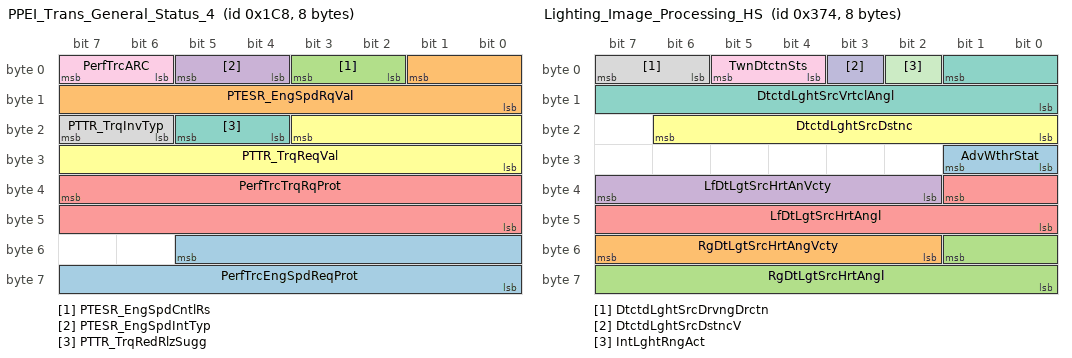
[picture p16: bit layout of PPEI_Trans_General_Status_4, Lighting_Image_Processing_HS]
BO_ 456 PPEI_Trans_General_Status_4: 8 PTAM_HS
  SG_ PerfTrcEngSpdReqProt: 53|14@0+ (1,0) [0|16383] "" PCM_HS ECM_HS
  SG_ PTESR_EngSpdRqVal: 1|10@0+ (8,0) [0|8184] "rpm" LVMPC_HS PCM_HS ECM_HS
  SG_ PTESR_EngSpdCntlRs: 3|2@0+ (1,0) [0|3] "" LVMPC_HS PCM_HS ECM_HS
  SG_ PTESR_EngSpdIntTyp: 5|2@0+ (1,0) [0|3] "" LVMPC_HS PCM_HS ECM_HS
  SG_ PerfTrcTrqRqProt: 39|16@0+ (1,0) [0|65535] "" PCM_HS ECM_HS
  SG_ PTTR_TrqReqVal: 19|12@0+ (0.5,-848) [-848|1199.5] "Nm" ICCM_OBD_HS ICCM_HS PCM_HS ECM_HS
  SG_ PTTR_TrqRedRlzSugg: 21|2@0+ (1,0) [0|3] "" ICCM_OBD_HS ICCM_HS PCM_HS ECM_HS
  SG_ PTTR_TrqInvTyp: 23|2@0+ (1,0) [0|3] "" ICCM_OBD_HS ICCM_HS PCM_HS ECM_HS
  SG_ PerfTrcARC: 7|2@0+ (1,0) [0|3] "" PCM_HS ECM_HS

BO_ 884 Lighting_Image_Processing_HS: 8 FCM_HS
  SG_ AdvWthrStat: 25|2@0+ (1,0) [0|3] "" EDI_HS AHL_AFL_HS
  SG_ RgDtLgtSrcHrtAngVcty: 55|6@0- (1,0) [-32|31] "deg/sec" AHL_AFL_HS
  SG_ RgDtLgtSrcHrtAngl: 49|10@0- (0.040000003,0) [-20.48|20.440001] "deg" AHL_AFL_HS
  SG_ LfDtLgtSrcHrtAnVcty: 39|6@0- (1,0) [-32|31] "deg/sec" AHL_AFL_HS
  SG_ LfDtLgtSrcHrtAngl: 33|10@0- (0.040000003,0) [-20.48|20.440001] "deg" AHL_AFL_HS
  SG_ DtctdLghtSrcDstnc: 22|7@0+ (10,0) [0|1270] "m" AHL_AFL_HS
  SG_ DtctdLghtSrcVrtclAngl: 1|10@0- (0.040000003,0) [-20.48|20.440001] "deg" AHL_AFL_HS
  SG_ DtctdLghtSrcDrvngDrctn: 7|2@0+ (1,0) [0|3] "" AHL_AFL_HS
  SG_ TwnDtctnSts: 5|2@0+ (1,0) [0|3] "" AHL_AFL_HS
  SG_ DtctdLghtSrcDstncV: 3|1@0+ (1,0) [0|1] "" AHL_AFL_HS
  SG_ IntLghtRngAct: 2|1@0+ (1,0) [0|1] "" AHL_AFL_HS

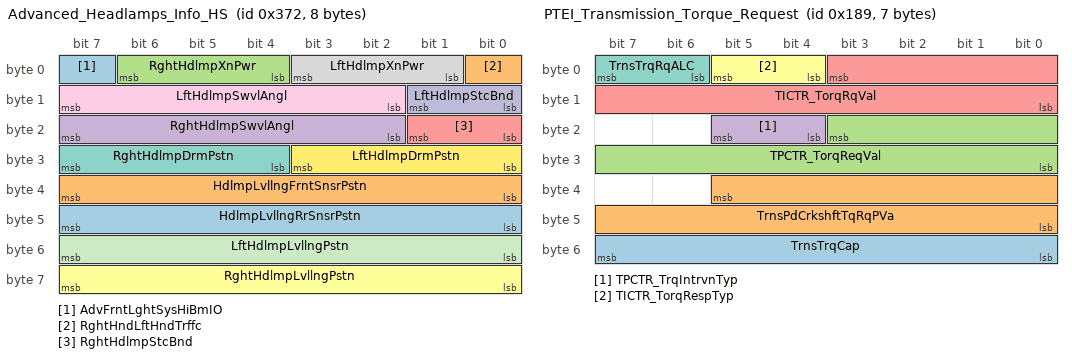
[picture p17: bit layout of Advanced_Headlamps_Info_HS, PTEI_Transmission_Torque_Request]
BO_ 882 Advanced_Headlamps_Info_HS: 8 AHL_AFL_HS
  SG_ AdvFrntLghtSysHiBmIO: 7|1@0+ (1,0) [0|1] "" BCM_HS FCM_HS
  SG_ RghtHndLftHndTrffc: 0|1@0+ (1,0) [0|1] "" FCM_HS
  SG_ RghtHdlmpXnPwr: 6|3@0+ (1,32) [32|39] "Watt" FCM_HS
  SG_ RghtHdlmpSwvlAngl: 23|6@0- (0.5,0) [-16|15.5] "deg" FCM_HS
  SG_ RghtHdlmpStcBnd: 17|2@0+ (25,25) [25|100] "%" FCM_HS
  SG_ RghtHdlmpLvllngPstn: 63|8@0- (0.050000004,0) [-6.4000001|6.3500004] "%" FCM_HS
  SG_ RghtHdlmpDrmPstn: 31|4@0+ (1,1) [1|16] "" FCM_HS
  SG_ LftHdlmpXnPwr: 3|3@0+ (1,32) [32|39] "Watt" FCM_HS
  SG_ LftHdlmpSwvlAngl: 15|6@0- (0.5,0) [-16|15.5] "deg" FCM_HS
  SG_ LftHdlmpStcBnd: 9|2@0+ (25,25) [25|100] "%" FCM_HS
  SG_ LftHdlmpLvllngPstn: 55|8@0- (0.050000004,0) [-6.4000001|6.3500004] "%" FCM_HS
  SG_ LftHdlmpDrmPstn: 27|4@0+ (1,1) [1|16] "" FCM_HS
  SG_ HdlmpLvllngRrSnsrPstn: 47|8@0- (1,0) [-128|127] "mm" FCM_HS
  SG_ HdlmpLvllngFrntSnsrPstn: 39|8@0- (1,0) [-128|127] "mm" FCM_HS

BO_ 393 PTEI_Transmission_Torque_Request: 7 ECM_HS
  SG_ TrnsTrqCap: 55|8@0+ (4,0) [0|1020] "Nm" PCM_HS ECM_HS
  SG_ TrnsPdCrkshftTqRqPVa: 37|14@0+ (1,0) [0|16383] "" PCM_HS ECM_HS
  SG_ TPCTR_TorqReqVal: 19|12@0+ (0.5,-848) [-848|1199.5] "Nm" PCM_HS ECM_HS
  SG_ TPCTR_TrqIntrvnTyp: 21|2@0+ (1,0) [0|3] "" PCM_HS ECM_HS
  SG_ TICTR_TorqRqVal: 3|12@0+ (0.5,-848) [-848|1199.5] "Nm" PCM_HS ECM_HS
  SG_ TICTR_TorqRespTyp: 5|2@0+ (1,0) [0|3] "" PCM_HS ECM_HS
  SG_ TrnsTrqRqALC: 7|2@0+ (1,0) [0|3] "" PCM_HS ECM_HS

BO_ 199 PPEI_Transmission_Otpt_Rot_Stat: 4 TCM_HS
  SG_ TORSTimestamp: 23|16@0+ (1,0) [0|65535] "counts" ICCM_OBD_HS ICCM_HS TCCM_HS BCP_HS
  SG_ TORSPulsCntr: 1|10@0+ (1,0) [0|1023] "counts" ICCM_OBD_HS ICCM_HS TCCM_HS BCP_HS
  SG_ TORSValidity: 2|1@0+ (1,0) [0|1] "" ICCM_OBD_HS ICCM_HS TCCM_HS BCP_HS
  SG_ TORSRstOcrd: 3|1@0+ (1,0) [0|1] "" ICCM_OBD_HS ICCM_HS TCCM_HS BCP_HS
  SG_ TORSLstTransType: 5|2@0+ (1,0) [0|3] "" ICCM_OBD_HS ICCM_HS TCCM_HS BCP_HS
  SG_ TORSRotDir: 7|2@0+ (1,0) [0|3] "" ICCM_OBD_HS ICCM_HS TCCM_HS BCP_HS

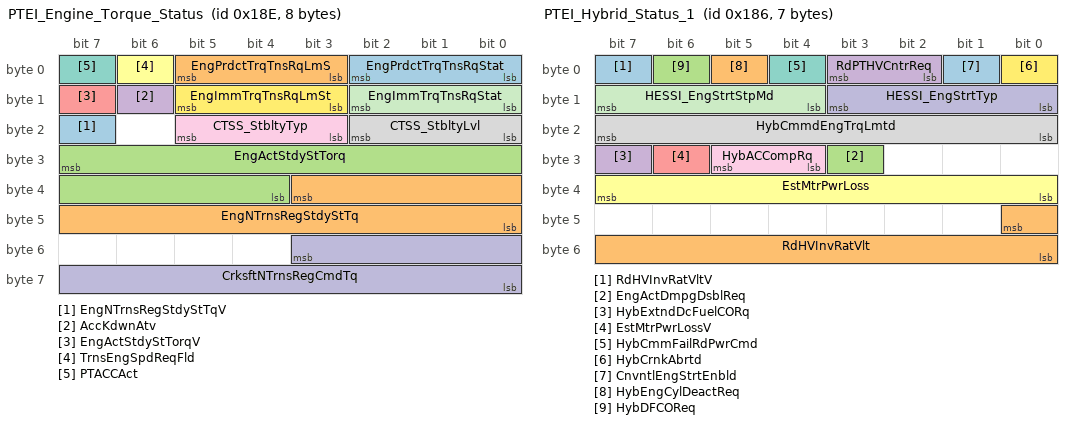
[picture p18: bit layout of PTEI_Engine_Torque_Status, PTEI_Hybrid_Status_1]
BO_ 398 PTEI_Engine_Torque_Status: 8 ECM_HS
  SG_ EngNTrnsRegStdyStTqV: 23|1@0+ (1,0) [0|1] "" TCM_HS
  SG_ EngNTrnsRegStdyStTq: 35|12@0+ (0.5,-848) [-848|1199.5] "Nm" TCM_HS
  SG_ EngActStdyStTorq: 31|12@0+ (0.5,-848) [-848|1199.5] "Nm" TCCM_HS TCM_HS
  SG_ AccKdwnAtv: 14|1@0+ (1,0) [0|1] "" TCM_HS TCCM_HS
  SG_ EngActStdyStTorqV: 15|1@0+ (1,0) [0|1] "" TCM_HS TCCM_HS
  SG_ TrnsEngSpdReqFld: 6|1@0+ (1,0) [0|1] "" TCM_HS TCCM_HS
  SG_ PTACCAct: 7|1@0+ (1,0) [0|1] "" TCM_HS
  SG_ CTSS_StbltyLvl: 18|3@0+ (1,0) [0|7] "" TCM_HS
  SG_ CTSS_StbltyTyp: 21|3@0+ (1,0) [0|7] "" TCM_HS
  SG_ CrksftNTrnsRegCmdTq: 51|12@0+ (0.5,-848) [-848|1199.5] "Nm" TCM_HS
  SG_ EngImmTrqTnsRqStat: 10|3@0+ (1,0) [0|7] "" TCM_HS
  SG_ EngImmTrqTnsRqLmSt: 13|3@0+ (1,0) [0|7] "" TCM_HS
  SG_ EngPrdctTrqTnsRqStat: 2|3@0+ (1,0) [0|7] "" TCM_HS
  SG_ EngPrdctTrqTnsRqLmS: 5|3@0+ (1,0) [0|7] "" TCM_HS

BO_ 464 PPEI_Front_Axle_Status: 4 TCCM_HS
  SG_ FrtAxlOpeMod: 31|3@0+ (1,0) [0|7] "" EBCM_OBD_HS EBCM_HS

BO_ 390 PTEI_Hybrid_Status_1: 7 HCP_HS
  SG_ RdHVInvRatVltV: 7|1@0+ (1,0) [0|1] "" VICM_HS
  SG_ RdHVInvRatVlt: 40|9@0+ (1,0) [0|511] "volts" VICM_HS
  SG_ EngActDmpgDsblReq: 27|1@0+ (1,0) [0|1] "" PCM_HS ECM_HS
  SG_ HybExtndDcFuelCORq: 31|1@0+ (1,0) [0|1] "" PCM_HS ECM_HS
  SG_ EstMtrPwrLossV: 30|1@0+ (1,0) [0|1] "" TCM_HS
  SG_ EstMtrPwrLoss: 39|8@0+ (0.25,0) [0|63.75] "kW" TCM_HS
  SG_ HybCmmFailRdPwrCmd: 4|1@0+ (1,0) [0|1] "" PCM_HS ECM_HS
  SG_ HybCmmdEngTrqLmtd: 23|8@0+ (0.75,-90) [-90|101.25] "Nm" PCM_HS ECM_HS
  SG_ HybACCompRq: 29|2@0+ (1,0) [0|3] "" PCM_HS ECM_HS
  SG_ HESSI_EngStrtTyp: 11|4@0+ (1,0) [0|15] "" VICM2_HS VICM_HS PCM_HS ECM_HS
  SG_ HESSI_EngStrtStpMd: 15|4@0+ (1,0) [0|15] "" VICM2_HS VICM_HS PCM_HS ECM_HS
  SG_ HybCrnkAbrtd: 0|1@0+ (1,0) [0|1] "" PCM_HS ECM_HS
  SG_ CnvntlEngStrtEnbld: 1|1@0+ (1,0) [0|1] "" PCM_HS ECM_HS
  SG_ HybEngCylDeactReq: 5|1@0+ (1,0) [0|1] "" PCM_HS ECM_HS
  SG_ HybDFCOReq: 6|1@0+ (1,0) [0|1] "" PCM_HS ECM_HS
  SG_ RdPTHVCntrReq: 3|2@0+ (1,0) [0|3] "" VICM_HS

BO_ 817 Rear_Axle_General_Information_HS: 2 RDCM_HS
  SG_ RrDrvlnSysVehTpSpdLmVal: 15|8@0+ (2,0) [0|510] "km/h" BCM_HS
  SG_ RrAxlTmpInhIO: 1|1@0+ (1,0) [0|1] "" BCM_HS
  SG_ RrAxlMalfIO: 0|1@0+ (1,0) [0|1] "" BCM_HS EBCM_OBD_HS EBCM_HS

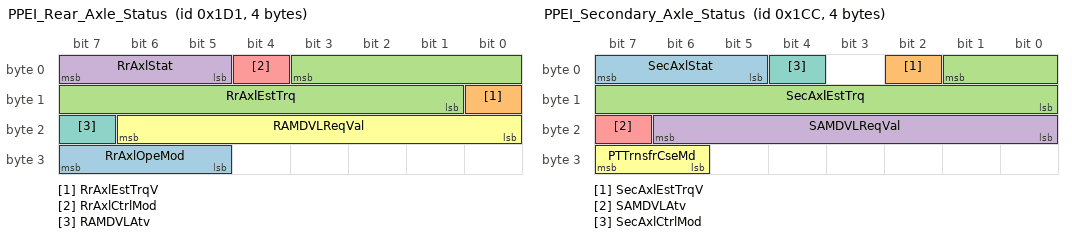
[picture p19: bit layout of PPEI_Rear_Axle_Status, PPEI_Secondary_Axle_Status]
BO_ 465 PPEI_Rear_Axle_Status: 4 TCCM_HS
  SG_ RrAxlOpeMod: 31|3@0+ (1,0) [0|3] "" EBCM_OBD_HS EBCM_HS
  SG_ RrAxlEstTrqV: 8|1@0+ (1,0) [0|1] "" EBCM_OBD_HS EBCM_HS
  SG_ RrAxlEstTrq: 3|11@0- (5,0) [-5120|5115] "Nm" EBCM_OBD_HS EBCM_HS
  SG_ RrAxlStat: 7|3@0+ (1,0) [0|3] "" EBCM_OBD_HS EBCM_HS
  SG_ RrAxlCtrlMod: 4|1@0+ (1,0) [0|1] "" EBCM_OBD_HS EBCM_HS
  SG_ RAMDVLReqVal: 22|7@0+ (2,0) [0|254] "rpm" EBCM_OBD_HS EBCM_HS
  SG_ RAMDVLAtv: 23|1@0+ (1,0) [0|1] "" EBCM_OBD_HS EBCM_HS

BO_ 460 PPEI_Secondary_Axle_Status: 4 TCCM_HS
  SG_ SecAxlStat: 7|3@0+ (1,0) [0|3] "" EOCM_F_HS ACC_HS EBCM_OBD_HS EBCM_HS
  SG_ SecAxlEstTrqV: 2|1@0+ (1,0) [0|1] "" EBCM_OBD_HS EBCM_HS
  SG_ SecAxlEstTrq: 1|10@0+ (10,0) [0|10230] "Nm" EBCM_OBD_HS EBCM_HS
  SG_ SAMDVLReqVal: 22|7@0+ (2,0) [0|254] "" EBCM_OBD_HS EBCM_HS
  SG_ SAMDVLAtv: 23|1@0+ (1,0) [0|1] "" EBCM_OBD_HS EBCM_HS
  SG_ PTTrnsfrCseMd: 31|2@0+ (1,0) [0|3] "" PCM_HS TCM_HS ECM_HS
  SG_ SecAxlCtrlMod: 4|1@0+ (1,0) [0|1] "" EBCM_OBD_HS EBCM_HS

BO_ 462 PPEI_Secondary_Axle_Control: 4 EBCM_HS
  SG_ SecAxlTrqReqProtVal: 18|11@0+ (1,0) [0|2047] "Counts" TCCM_HS
  SG_ SecAxlTrqReqARollCnt: 4|2@0+ (1,0) [0|3] "Counts" TCCM_HS
  SG_ SATRCplReqVal: 1|10@0+ (10,0) [0|10230] "Nm" TCCM_HS
  SG_ SATRCplReqAtv: 2|1@0+ (1,0) [0|1] "" TCCM_HS

BO_ 463 PPEI_Secondary_Axle_General_Info: 3 ECM_HS
  SG_ FourWhlDrvIndReq: 15|3@0+ (1,0) [0|8] "" BCM_HS
  SG_ TrnsfrCsRngShfSpdLmt: 23|8@0+ (1,0) [0|255] "km / h" BCM_HS
  SG_ SecAxlNonEmMalfIO: 7|1@0+ (1,0) [0|1] "" BCM_HS
  SG_ SecAxlOperMod: 3|4@0+ (1,0) [0|3] "" VICM_HS BCM_HS FCP_HS ONSTAR_HS TCM_HS PCM_HS ECM_HS ACC_HS EOCM_F_HS EBCM_OBD_HS EBCM_HS
  SG_ SecAxlTmpInhIO: 6|1@0+ (1,0) [0|1] "" BCM_HS FCP_HS ONSTAR_HS

BO_ 719 PPEI_Rear_Virtual_Bmp_Req_Status: 5 EOCM_F_HS
  SG_ RrVrtlBmpAxlTrqCmdRC: 7|2@0+ (1,0) [0|3] "" PCM_HS ECM_HS
  SG_ RrVrtlBmpAxlTrqCmdProtVal: 31|16@0+ (1,0) [0|65535] "" PCM_HS ECM_HS
  SG_ RVBATC_AxlTrqRqstAct: 15|1@0+ (1,0) [0|1] "" PCM_HS ECM_HS
  SG_ RVBATC_AxlTrqRqst: 14|15@0+ (2,-22534) [-22534|43000] "NM" PCM_HS ECM_HS

BO_TX_BU_ 528:EBCM_OBD_HS,EBCM_HS;
BO_TX_BU_ 442:PCM_HS,ECM_HS;
BO_TX_BU_ 753:EBCM_OBD_HS,EBCM_HS;
BO_TX_BU_ 988:PCM_HS,ECM_HS;
BO_TX_BU_ 500:PCM_HS,ECM_HS;
BO_TX_BU_ 1417:PCM_HS,ECM_HS;
BO_TX_BU_ 170:PCM_HS,ECM_HS;
BO_TX_BU_ 1243:ICCM_OBD_HS,ICCM_HS,FSCM_ITBC_HS,FSCM_HS;
BO_TX_BU_ 508:EBCM_OBD_HS,EBCM_HS;
BO_TX_BU_ 647:PCM_HS,ECM_HS;
BO_TX_BU_ 368:VLBS_HS,ONSTAR_HS;
BO_TX_BU_ 209:EBCM_OBD_HS,EBCM_HS;
BO_TX_BU_ 454:EBCM_OBD_HS,EBCM_HS;
BO_TX_BU_ 456:EBCM_OBD_HS,EBCM_HS,PTAM_HS;
BO_TX_BU_ 393:PCM_HS,TCM_HS,ECM_HS;
BO_TX_BU_ 398:PCM_HS,ECM_HS;
BO_TX_BU_ 390:BCP_HS,HCP_HS;
BO_TX_BU_ 817:ICCM_OBD_HS,ICCM_HS,RDCM_HS;
BO_TX_BU_ 462:EBCM_OBD_HS,EBCM_HS;
BO_TX_BU_ 463:RDCM_HS,TCCM_HS,PCM_HS,ECM_HS;
VAL_ 1219 DslExhFldDiagWrnIdRq 0 "No Indication" 1 "Warning Level 1" 2 "Warning Level 2" 3 "Warning Level 3" 4 "Warning Level 4" 5 "Warning Level 5" 6 "Warning Level 6" 7 "Warning Level 7";
VAL_ 1219 DslEmnsOBDMrkt 0 "USEPA TIER 2 / CALIFORNIA LEV II" 1 "EURO5/6";
VAL_ 1219 DslExNxEmWrngIndRq 0 "No Indication" 1 "Warning Level 1" 2 "Warning Level 2" 3 "Warning Level 3" 4 "Warning Level 4" 5 "Warning Level 5" 6 "Warning Level 6" 7 "Warning Level 7" 8 "Warning Level 8" 9 "Warning Level 9" 10 "Warning Level 10" 11 "Warning Level 11" 12 "Warning Level 12" 13 "Warning Level 13" 14 "Warning Level 14" 15 "Warning Level 15";
VAL_ 1219 DslExFldTpWrngIndRq 0 "No Indication" 1 "Warning Level 1" 2 "Warning Level 2" 3 "Warning Level 3" 4 "Warning Level 4" 5 "Warning Level 5" 6 "Warning Level 6" 7 "Warning Level 7" 8 "Warning Level 8" 9 "Warning Level 9" 10 "Warning Level 10" 11 "Warning Level 11" 12 "Warning Level 12" 13 "Warning Level 13" 14 "Warning Level 14" 15 "Warning Level 15";
VAL_ 1219 DslExhFldQlyWrngIReq 0 "No Indication" 1 "Warning Level 1" 2 "Warning Level 2" 3 "Warning Level 3" 4 "Warning Level 4" 5 "Warning Level 5" 6 "Warning Level 6" 7 "Warning Level 7" 8 "Warning Level 8" 9 "Warning Level 9" 10 "Warning Level 10" 11 "Warning Level 11" 12 "Warning Level 12" 13 "Warning Level 13" 14 "Warning Level 14" 15 "Warning Level 15";
VAL_ 1219 DslExhFldWrngIdRqER 0 "No Indication" 1 "Warning Level 1" 2 "Warning Level 2" 3 "Warning Level 3" 4 "Warning Level 4" 5 "Warning Level 5" 6 "Warning Level 6" 7 "Warning Level 7" 8 "Warning Level 8" 9 "Warning Level 9" 10 "Warning Level 10" 11 "Warning Level 11" 12 "Warning Level 12" 13 "Warning Level 13" 14 "Warning Level 14" 15 "Warning Level 15";
VAL_ 1219 DslExFldCnWrngIndRq 0 "No Indication" 1 "Warning Level 1" 2 "Warning Level 2" 3 "Warning Level 3" 4 "Warning Level 4" 5 "Warning Level 5" 6 "Warning Level 6" 7 "Warning Level 7" 8 "Warning Level 8" 9 "Warning Level 9" 10 "Warning Level 10" 11 "Warning Level 11" 12 "Warning Level 12" 13 "Warning Level 13" 14 "Warning Level 14" 15 "Warning Level 15";
VAL_ 372 ARSFlrIO 0 "false" 1 "true";
VAL_ 528 BSABR_TrlBrkCntlIntRq 0 "false" 1 "true";
VAL_ 552 ThrmlRefCmpIGBTTmpV 0 "Valid" 1 "Invalid";
VAL_ 552 ThrmlRefCmpHiVltgInptV 0 "Valid" 1 "Invalid";
VAL_ 552 ThrmlRefCmpCPUHtSkTmpV 0 "Valid" 1 "Invalid";
VAL_ 442 CrksftTqMinImCapV 0 "Valid" 1 "Invalid";
VAL_ 442 CrksftMaxTrqLmtV 0 "Valid" 1 "Invalid";
VAL_ 753 EBCMDS5_DTCStatus 0 "Not Supported" 1 "Critically Disabled" 2 "No Status to Report" 3 "Diagnostic Passed" 4 "Diagnostic Failed";
VAL_ 753 EBCMDS4_DTCStatus 0 "Not Supported" 1 "Critically Disabled" 2 "No Status to Report" 3 "Diagnostic Passed" 4 "Diagnostic Failed";
VAL_ 753 EBCMDS3_DTCStatus 0 "Not Supported" 1 "Critically Disabled" 2 "No Status to Report" 3 "Diagnostic Passed" 4 "Diagnostic Failed";
VAL_ 753 EBCMDS2_DTCStatus 0 "Not Supported" 1 "Critically Disabled" 2 "No Status to Report" 3 "Diagnostic Passed" 4 "Diagnostic Failed";
VAL_ 753 EBCMDS1_DTCStatus 0 "Not Supported" 1 "Critically Disabled" 2 "No Status to Report" 3 "Diagnostic Passed" 4 "Diagnostic Failed";
VAL_ 989 RdHVCntctrShdwnReq 0 "None" 1 "Emergency Shutdown" 2 "Controlled Shutdown" 3 "Emergency Crash Shutdown";
VAL_ 989 AuxClntHtrVlvStat 0 "Engine Bypass" 1 "Transition" 2 "Engine Link" 3 "Fault Active" 4 "Re-Calibration" 5 "Diagnostic Override" 6 "De-Aeration Routine Active" 7 "Unused and Reserved 2";
VAL_ 989 EngCoolFanOpEnbl 0 "false" 1 "true";
VAL_ 989 DiagFreeRunCntrV 0 "Valid" 1 "Invalid";
VAL_ 989 MntnceMdStEngRq 0 "false" 1 "true";
VAL_ 989 RdHVCntctrCmdStat 0 "Open" 1 "Precharge" 2 "Close";
VAL_ 550 ACCMCII_DatStat 0 "Cal ID Index Not Used" 1 "Cal Verification Number Uncalculated" 2 "Cal Verification Number Calculated";
VAL_ 548 ACCMDSO_DTCStat 0 "Not Supported" 1 "Critically Disabled" 2 "No Status to Report" 3 "Diagnostic Passed" 4 "Diagnostic Failed";
VAL_ 548 ACCMDSI_DTCStat 0 "Not Supported" 1 "Critically Disabled" 2 "No Status to Report" 3 "Diagnostic Passed" 4 "Diagnostic Failed";
VAL_ 548 ACCMDSG_DTCStat 0 "Not Supported" 1 "Critically Disabled" 2 "No Status to Report" 3 "Diagnostic Passed" 4 "Diagnostic Failed";
VAL_ 988 AccPwrModMinCoolRq 0 "None" 1 "Minimum" 2 "Low" 3 "Medium" 4 "High";
VAL_ 988 A6ERRAlrmReq 0 "No Action" 1 "Set Alarm" 2 "Cancel Alarm";
VAL_ 988 MntnceMdDsplyRq 0 "No Request" 1 "EM 5 Day Warning" 2 "EM 4 Day Warning" 3 "EM 3 Day Warning" 4 "EM 2 Day Warning" 5 "EM 1 Day Warning" 6 "Force EM" 7 "Continue EM" 8 "FM 5 Day Warning" 9 "FM 4 Day Warning" 10 "FM 3 Day Warning" 11 "FM 2 Day Warning" 12 "FM 1 Day Warning" 13 "Force FM" 14 "Continue FM" 15 "Unused and Reserved";
VAL_ 988 EngMntnceMdAct 0 "false" 1 "true";
VAL_ 988 HVPropChgrUnbl 0 "false" 1 "true";
VAL_ 988 EngHtrValvBpasCmd 0 "Bypass Commanded" 1 "Normal Operation Allowed";
VAL_ 1029 FCO6D_ObjTyp 0 "No Object" 1 "Headlamp" 2 "Rearlamp" 3 "Pair Headlamps" 4 "Pair Rearlamps";
VAL_ 1029 FCO6D_ObjQlty 0 "Less than 70%" 1 "70-85%" 2 "85-95%" 3 "95-100%";
VAL_ 1029 FCO6D_DetMthd 0 "Measured Object" 1 "Tracked Object" 2 "Initializing" 3 "Unavailable";
VAL_ 1028 FCO5D_ObjTyp 0 "No Object" 1 "Headlamp" 2 "Rearlamp" 3 "Pair Headlamps" 4 "Pair Rearlamps";
VAL_ 1028 FCO5D_ObjQlty 0 "Less than 70%" 1 "70-85%" 2 "85-95%" 3 "95-100%";
VAL_ 1028 FCO5D_DetMthd 0 "Measured Object" 1 "Tracked Object" 2 "Initializing" 3 "Unavailable";
VAL_ 500 EnhDrvMdSwChUseAct 0 "false" 1 "true";
VAL_ 500 EnhDrvSelMdSwStat 0 "No Activation" 1 "Increment" 2 "Decrement" 3 "Faulted";
VAL_ 500 DrvSelMd8Stat 0 "Inactive" 1 "Active";
VAL_ 500 DrvSelMd8ReqDnd 0 "false" 1 "true";
VAL_ 500 DrvSelMd7Stat 0 "Inactive" 1 "Active";
VAL_ 500 DrvSelMd7ReqDnd 0 "false" 1 "true";
VAL_ 500 DrvSelMd6Stat 0 "Inactive" 1 "Active";
VAL_ 500 DrvSelMd6ReqDnd 0 "false" 1 "true";
VAL_ 500 DrvSelMd5Stat 0 "Inactive" 1 "Active";
VAL_ 500 DrvSelMd5ReqDnd 0 "false" 1 "true";
VAL_ 500 DrvSelMd4Stat 0 "Inactive" 1 "Active";
VAL_ 500 DrvSelMd4ReqDnd 0 "false" 1 "true";
VAL_ 500 DrvSelMd3Stat 0 "Inactive" 1 "Active";
VAL_ 500 DrvSelMd3ReqDnd 0 "false" 1 "true";
VAL_ 500 DrvSelMd2Stat 0 "Inactive" 1 "Active";
VAL_ 500 DrvSelMd2ReqDnd 0 "false" 1 "true";
VAL_ 500 DSMSS_DrvSelMd0Pn 0 "false" 1 "true";
VAL_ 500 DSMSS_DrvSelMd8Pn 0 "false" 1 "true";
VAL_ 500 DSMSS_DrvSelMd7Pn 0 "false" 1 "true";
VAL_ 500 DSMSS_DrvSelMd6Pn 0 "false" 1 "true";
VAL_ 500 DSMSS_DrvSelMd5Pn 0 "false" 1 "true";
VAL_ 500 DSMSS_DrvSelMd4Pn 0 "false" 1 "true";
VAL_ 500 DSMSS_DrvSelMd3Pn 0 "false" 1 "true";
VAL_ 500 DSMSS_DrvSelMd2Pn 0 "false" 1 "true";
VAL_ 500 DSMSS_DrvSelMd1Pn 0 "false" 1 "true";
VAL_ 500 DSMSS_DrvSelMd8Un 0 "false" 1 "true";
VAL_ 500 DSMSS_DrvSelMd7Un 0 "false" 1 "true";
VAL_ 500 DSMSS_DrvSelMd6Un 0 "false" 1 "true";
VAL_ 500 DSMSS_DrvSelMd5Un 0 "false" 1 "true";
VAL_ 500 DSMSS_DrvSelMd4Un 0 "false" 1 "true";
VAL_ 500 DSMSS_DrvSelMd3Un 0 "false" 1 "true";
VAL_ 500 DSMSS_DrvSelMd2Un 0 "false" 1 "true";
VAL_ 500 DSMSS_DrvSelMd1Un 0 "false" 1 "true";
VAL_ 500 DrvSelMd1ReqDnd 0 "false" 1 "true";
VAL_ 500 DrvSelMd1Stat 0 "Inactive" 1 "Active";
VAL_ 1417 ETC_EngOpMd 0 "All cylinders" 1 "Half Cylinders";
VAL_ 407 TrnsOvrallActTorqRatioV 0 "Valid" 1 "Invalid";
VAL_ 189 TrnsRtoCntlSysFlt 0 "false" 1 "true";
VAL_ 189 TrnsInpMinSpdRq 0 "Unused and Reserved" 1 "Speed Point 1" 2 "Speed Point 2" 3 "Speed Point 3" 4 "Speed Point 4" 5 "Speed Point 5" 6 "Speed Point 6" 7 "Speed Point 7" 8 "Speed Point 8" 9 "Speed Point 9" 10 "Speed Point 10" 11 "Speed Point 11" 12 "Speed Point 12" 13 "Speed Point 13" 14 "Speed Point 14" 15 "Speed Point 15";
VAL_ 187 TransCltch5FillCmd 0 "Exhaust Clutch" 1 "Fill Clutch" 2 "Lock Clutch" 3 "Prefill Clutch";
VAL_ 187 TransCltch4FillCmd 0 "Exhaust Clutch" 1 "Fill Clutch" 2 "Lock Clutch" 3 "Prefill Clutch";
VAL_ 185 TransCltch1FillCmd 0 "Exhaust Clutch" 1 "Fill Clutch" 2 "Lock Clutch" 3 "Prefill Clutch";
VAL_ 185 TransCltch1CntlRq 0 "No Control" 1 "Active Control" 2 "Passive Control" 3 "Unused and Reserved";
VAL_ 185 TransCltch5CntlRq 0 "No Control" 1 "Active Control" 2 "Passive Control" 3 "Unused and Reserved";
VAL_ 185 TransCltch4CntlRq 0 "No Control" 1 "Active Control" 2 "Passive Control" 3 "Unused and Reserved";
VAL_ 185 TransCltch3CntlRq 0 "No Control" 1 "Active Control" 2 "Passive Control" 3 "Unused and Reserved";
VAL_ 185 TransCltch2CntlRq 0 "No Control" 1 "Active Control" 2 "Passive Control" 3 "Unused and Reserved";
VAL_ 186 TransCltch3FillCmd 0 "Exhaust Clutch" 1 "Fill Clutch" 2 "Lock Clutch" 3 "Prefill Clutch";
VAL_ 186 TransCltch2FillCmd 0 "Exhaust Clutch" 1 "Fill Clutch" 2 "Lock Clutch" 3 "Prefill Clutch";
VAL_ 152 TransClch5FlAch 0 "false" 1 "true";
VAL_ 152 TransClch5_Avail 0 "false" 1 "true";
VAL_ 152 TransClch4FlAch 0 "false" 1 "true";
VAL_ 152 TransClch4_Avail 0 "false" 1 "true";
VAL_ 151 TransClch3FlAch 0 "false" 1 "true";
VAL_ 151 TransClch3_Avail 0 "false" 1 "true";
VAL_ 151 TransClch2FlAch 0 "false" 1 "true";
VAL_ 151 TransClch2_Avail 0 "false" 1 "true";
VAL_ 150 TrnsInpDvcStat 0 "Normal Control" 1 "Temporary Isolation" 2 "Permanent Isolation" 3 "Unused and Reserved 1" 4 "Unused and Reserved 2" 5 "Unused and Reserved 3" 6 "Unused and Reserved 4" 7 "Unused and Reserved 5";
VAL_ 150 TransInhibitNeut 0 "false" 1 "true";
VAL_ 150 TransInhibitMode2 0 "false" 1 "true";
VAL_ 150 TransInhibitMode1 0 "false" 1 "true";
VAL_ 150 TransInhibitGear4 0 "false" 1 "true";
VAL_ 150 TransInhibitGear3 0 "false" 1 "true";
VAL_ 150 TransInhibitGear2 0 "false" 1 "true";
VAL_ 150 TransInhibitGear1 0 "false" 1 "true";
VAL_ 150 TrnsPTSysShtdwnRq 0 "false" 1 "true";
VAL_ 150 TransClch1FlAch 0 "false" 1 "true";
VAL_ 150 TransClch1_Avail 0 "false" 1 "true";
VAL_ 188 HybTransStCmmnd 0 "Neutral" 1 "Mode 1" 2 "Mode 2" 3 "Mode 3" 4 "Mode 4" 5 "Gear 1" 6 "Gear 2" 7 "Gear 3" 8 "Gear 4" 9 "Unused and Reserved 1" 10 "Unused and Reserved 2" 11 "Unused and Reserved 3" 12 "Unused and Reserved 4" 13 "Unused and Reserved 5" 14 "Unused and Reserved 6" 15 "Unused and Reserved 7";
VAL_ 188 HybTransStAchvd 0 "Neutral Stable State" 1 "EVT Mode 1 Stable State" 2 "EVT Mode 2 Stable State" 3 "EVT Mode 3 Stable State" 4 "EVT Mode 4 Stable State" 5 "Gear 1 Stable State" 6 "Gear 2 Stable State" 7 "Gear 3 Stable State" 8 "Gear 4 Stable State" 9 "Unused and Reserved 1" 10 "Unused and Reserved 2" 11 "Unused and Reserved 3" 12 "Unused and Reserved 4" 13 "Unused and Reserved 5" 14 "Unused and Reserved 6" 15 "Unused and Reserved 7";
VAL_ 188 TransFldPmpCmd 0 "Normal" 1 "Prime On" 2 "Off" 3 "On";
VAL_ 188 TransDirctnStV 0 "Valid" 1 "Invalid";
VAL_ 188 TransDirctnSt 0 "Between Positions" 1 "Park" 2 "Reverse" 3 "Neutral" 4 "Drive" 5 "Unknown";
VAL_ 188 TnsClchFlLnePrsBstRq 0 "false" 1 "true";
VAL_ 188 TransAuxPumpAvail 0 "false" 1 "true";
VAL_ 188 MtrBSpdV 0 "Valid" 1 "Invalid";
VAL_ 188 MtrASpdV 0 "Valid" 1 "Invalid";
VAL_ 170 EngCommFlrRedPwrCm 0 "false" 1 "true";
VAL_ 170 CmndAxlTrqRespTyp 0 "Inactive" 1 "Pleasability Limit" 2 "Maximum Range" 3 "Automatic Actuator Selection";
VAL_ 1221 SpdLmtVsnFsdSpdUnt 0 "km/h" 1 "mph";
VAL_ 1221 SpdLmtVnFsSpdNwDet 0 "false" 1 "true";
VAL_ 1221 SpdLmtVsnFsdSpdM 0 "Don't Use Data" 1 "Use Data";
VAL_ 1243 CSERDTC_SysDes 0 "P0-Powertrain Codes SAE Controlled" 1 "P1-Powertrain Codes MFG Controlled" 2 "P2-Powertrain Codes Reserved" 3 "P3-Powertrain Codes Reserved" 4 "C0-Chassis Codes SAE Controlled" 5 "C1-Chassis Codes MFG Controlled" 6 "C2-Chassis Codes Reserved" 7 "C3-Chassis Codes Reserved" 8 "B0-Body Codes SAE Controlled" 9 "B1-Body Codes MFG Controlled" 10 "B2-Body Codes Reserved" 11 "B3-Body Codes Reserved" 12 "U0-Network Codes SAE Controlled" 13 "U1-Network Codes MFG Controlled" 14 "U2- Network Codes Reserved" 15 "U3-Network Codes Reserved";
VAL_ 1243 ChsSysEmmRelMalfAct 0 "false" 1 "true";
VAL_ 979 PTABR_PTBrkRqAct 0 "false" 1 "true";
VAL_ 979 BrkBstVacV 0 "Valid" 1 "Invalid";
VAL_ 979 EngManfldAirTmpV 0 "Valid" 1 "Invalid";
VAL_ 546 ThrmlRfCmprElctrCrntV 0 "Valid" 1 "Invalid";
VAL_ 546 ThrmlRefCompStat 0 "Normal Operation" 1 "Degraded Operation" 2 "Inoperative" 3 "Invalid";
VAL_ 546 ThrmlRefCompSpdV 0 "Valid" 1 "Invalid";
VAL_ 546 ThrmlRfCmpOvTmpFltPr 0 "false" 1 "true";
VAL_ 546 ThrmlRefCompElecPwrV 0 "Valid" 1 "Invalid";
VAL_ 530 RstVTDTmprDtctd 0 "No Action" 1 "Reset";
VAL_ 530 RstIllDrIdDevDtctd 0 "No Action" 1 "Reset";
VAL_ 530 RstDrIdDevLrnd 0 "No Action" 1 "Reset";
VAL_ 1239 BattSOXStat 0 "Don't Use SOC,SOH, & SOF" 1 "Use SOC,SOH, & SOF";
VAL_ 1239 BattTempV 0 "Valid" 1 "Invalid";
VAL_ 1027 FCO4D_ObjTyp 0 "No Object" 1 "Headlamp" 2 "Rearlamp" 3 "Pair Headlamps" 4 "Pair Rearlamps";
VAL_ 1027 FCO4D_ObjQlty 0 "Less than 70%" 1 "70-85%" 2 "85-95%" 3 "95-100%";
VAL_ 1027 FCO4D_DetMthd 0 "Measured Object" 1 "Tracked Object" 2 "Initializing" 3 "Unavailable";
VAL_ 1026 FCO3D_ObjQlty 0 "Less than 70%" 1 "70-85%" 2 "85-95%" 3 "95-100%";
VAL_ 1026 FCO3D_DetMthd 0 "Measured Object" 1 "Tracked Object" 2 "Initializing" 3 "Unavailable";
VAL_ 1026 FCO3D_ObjTyp 0 "No Object" 1 "Headlamp" 2 "Rearlamp" 3 "Pair Headlamps" 4 "Pair Rearlamps";
VAL_ 1025 FCO2D_ObjQlty 0 "Less than 70%" 1 "70-85%" 2 "85-95%" 3 "95-100%";
VAL_ 1025 FCO2D_DetMthd 0 "Measured Object" 1 "Tracked Object" 2 "Initializing" 3 "Unavailable";
VAL_ 1025 FCO2D_ObjTyp 0 "No Object" 1 "Headlamp" 2 "Rearlamp" 3 "Pair Headlamps" 4 "Pair Rearlamps";
VAL_ 1024 FCO1D_ObjQlty 0 "Less than 70%" 1 "70-85%" 2 "85-95%" 3 "95-100%";
VAL_ 1024 FCO1D_DetMthd 0 "Measured Object" 1 "Tracked Object" 2 "Initializing" 3 "Unavailable";
VAL_ 1024 FCO1D_ObjTyp 0 "No Object" 1 "Headlamp" 2 "Rearlamp" 3 "Pair Headlamps" 4 "Pair Rearlamps";
VAL_ 508 CSTBATS_TrqVlV 0 "Valid" 1 "Invalid";
VAL_ 422 TrStPTGrdBrkDsMdOvr 0 "No Override" 1 "To Not Grade Braking Disable" 2 "To Grade Braking Disable" 3 "Unused and Reserved";
VAL_ 422 TrnsHybEngSrtStpOvrd 0 "No Override" 1 "Engine On" 2 "Engine Off";
VAL_ 647 DrvMntnMdCmnd 0 "false" 1 "true";
VAL_ 647 DrvHldMdCmnd 0 "false" 1 "true";
VAL_ 647 DrPTGrdBrkDsbMdCmd 0 "false" 1 "true";
VAL_ 647 DrvWntrMdCmd 0 "false" 1 "true";
VAL_ 647 DrvTwHaulMdCmd 0 "false" 1 "true";
VAL_ 647 DrvSprtMdCmd 0 "false" 1 "true";
VAL_ 647 DrvEconMdCmd 0 "false" 1 "true";
VAL_ 647 EngCntrlDtrmdTrfCRngV 0 "Valid" 1 "Invalid";
VAL_ 647 EngCntrlDtrmdTrfCRng 0 "High" 1 "Low" 2 "Unused and Reserved" 3 "Neutral";
VAL_ 647 EngCntrlUtldTrnCsRng 0 "High" 1 "Low" 2 "Unused and Reserved" 3 "Neutral";
VAL_ 647 EngCntrlUtldTrnCsRgIn 0 "false" 1 "true";
VAL_ 368 EnvIdRspSt5 0 "No info" 1 "Info valid" 2 "Incorrect immo id" 3 "Environment id request";
VAL_ 995 RdHVltBatMaxSnsTmpV 0 "Valid" 1 "Invalid";
VAL_ 995 RdHVltBatMaxSnsTmpM 0 "Don't Use Data" 1 "Use Data";
VAL_ 995 RdHVltBatMinClVltV 0 "Valid" 1 "Invalid";
VAL_ 995 RdHVltBatMinClVltM 0 "Don't Use Data" 1 "Use Data";
VAL_ 995 RdHVBatMinSnsTmpV 0 "Valid" 1 "Invalid";
VAL_ 995 RdHVBatMinSnsTmpM 0 "Don't Use Data" 1 "Use Data";
VAL_ 995 RdHVltBatMaxClVltV 0 "Valid" 1 "Invalid";
VAL_ 995 RdHVltBatMaxClVltM 0 "Don't Use Data" 1 "Use Data";
VAL_ 995 RdHVltBatAvgClVltV 0 "Valid" 1 "Invalid";
VAL_ 995 RdHVltBatAvgClVltM 0 "Don't Use Data" 1 "Use Data";
VAL_ 971 BatVltHiResV 0 "Valid" 1 "Invalid";
VAL_ 971 BCHR_BattCrntRwVlMu 0 "Multiplier Factor 1" 1 "Multiplier Factor 8" 2 "Multiplier Factor 64" 3 "Multiplier Factor 256";
VAL_ 971 BCHR_BattCrntRwValV 0 "Valid" 1 "Invalid";
VAL_ 209 ChsBrkPdlPsERltdV 0 "Valid" 1 "Invalid";
VAL_ 454 CSPATR_TrqIntrvnTyp 0 "No Intervention" 1 "Maximum Limit" 2 "Minimum Limit" 3 "Minimum and Maximum Limit";
VAL_ 454 CSPATR_TrqRqTyp 0 "Absolute Torque Request";
VAL_ 454 ChsSysAxlTqRqRspTyp 0 "Inactive" 1 "Pleasability Limited Request" 2 "Maximum Range Request" 3 "Automatic Actuator Selection" 4 "Braking Torque Request";
VAL_ 554 ElecPrkBrkAvailStat 0 "Unavailable, Not Failed" 1 "Available, Not Failed" 2 "Unavailable, Failed Applied" 3 "Unavailable, Failed Released" 4 "Unavailable, Failed other" 5 "Unused and Reserved 1" 6 "Unused and Reserved 2" 7 "Unused and Reserved 3";
VAL_ 554 ElecPrkBrkApplStat 0 "Unknown" 1 "Park Brake Applied" 2 "Park brake Released" 3 "Park Brake Application in Progress";
VAL_ 487 EngRunng 0 "false" 1 "true";
VAL_ 487 FlPmpEDscOtptCmdSta 0 "Fuel Pump Disabled" 1 "Fuel Pump Enabled";
VAL_ 487 FuelCntlSysFltPrsnt 0 "false" 1 "true";
VAL_ 487 HiPresFuelPmpCntMd 0 "Disable Mode" 1 "DFCO Mode" 2 "Normal Mode" 3 "Start Mode" 4 "Noise Control Disable Mode" 5 "Noise Control Max Mode" 6 "Zero Flow Mode";
VAL_ 566 RdHVBatLwParMdReq 0 "false" 1 "true";
VAL_ 566 RdHVBtClOVFFTstRq 0 "false" 1 "true";
VAL_ 566 ClimCtrlHVDvcShtdwnCmd 0 "false" 1 "true";
VAL_ 566 VICntlModRunCrkTrmSt 0 "Inactive" 1 "Active";
VAL_ 566 VICMHVEnMgCmEnTrS 0 "Inactive" 1 "Active";
VAL_ 566 ChrgSysPrkBrkAnmsBrkReq 0 "false" 1 "true";
VAL_ 566 VICMClrLgsDgInfo 0 "false" 1 "true";
VAL_ 566 HybVehHiVltSysDisbld_236 0 "false" 1 "true";
VAL_ 421 AccPwrMdlHiVltInpCrntV 0 "Valid" 1 "Invalid";
VAL_ 421 HTGR_ReqVal 0 "No Action" 1 "First Gear" 2 "Second Gear" 3 "Third Gear" 4 "Fourth Gear" 5 "Fifth Gear" 6 "Sixth Gear" 7 "Seventh Gear" 8 "Eighth Gear";
VAL_ 421 HTGR_ReqTyp 0 "No Request" 1 "Max Gear Request" 2 "Min Gear Request" 3 "Hold Gear";
VAL_ 421 HTGR_ReqPrty 0 "Desired" 1 "Recommended" 2 "Strongly Recommended" 3 "Mandatory";
VAL_ 421 HTCCR_ReqVal 0 "No Request" 1 "Immediate Off" 2 "Ramp Off A" 3 "Ramp Off B" 4 "Apply";
VAL_ 421 HTCCR_ReqPrty 0 "Desired" 1 "Recommended" 2 "Strongly Recommended" 3 "Mandatory";
VAL_ 421 TrnsAuxPmpAct 0 "false" 1 "true";
VAL_ 421 HybSnsBrkPdlPosV 0 "Valid" 1 "Invalid";
VAL_ 456 PTESR_EngSpdCntlRs 0 "No Suggestion" 1 "Transient Optimized" 2 "Stability Optimized Cond 1" 3 "Stability Optimized Cond 2";
VAL_ 456 PTESR_EngSpdIntTyp 0 "No Intervention" 1 "Engine Speed Max Limit";
VAL_ 456 PTTR_TrqRedRlzSugg 0 "No Suggestion" 1 "Transient Optimized";
VAL_ 456 PTTR_TrqInvTyp 0 "No Intervention" 1 "Maximum Limit";
VAL_ 884 AdvWthrStat 0 "Clear weather" 1 "Fog" 2 "Snow" 3 "Rain";
VAL_ 884 DtctdLghtSrcDrvngDrctn 0 "Unknown" 1 "Incoming Traffic" 2 "Ahead Traffic";
VAL_ 884 TwnDtctnSts 0 "Not Active" 1 "Town Not Detected" 2 "Town Detected" 3 "Undefined";
VAL_ 884 DtctdLghtSrcDstncV 0 "Valid" 1 "Invalid";
VAL_ 884 IntLghtRngAct 0 "false" 1 "true";
VAL_ 882 AdvFrntLghtSysHiBmIO 0 "false" 1 "true";
VAL_ 882 RghtHndLftHndTrffc 0 "Left Hand Traffic" 1 "Right Hand Traffic";
VAL_ 393 TPCTR_TrqIntrvnTyp 0 "No Request" 1 "Maximum Limit" 2 "Minimum Limit" 3 "Unused and Reserved";
VAL_ 393 TICTR_TorqRespTyp 0 "Inactive" 1 "Pleasability Limited" 2 "Maximum Range" 3 "Automatic Actuator Selection";
VAL_ 199 TORSValidity 0 "Valid" 1 "Invalid";
VAL_ 199 TORSRstOcrd 0 "false" 1 "true";
VAL_ 199 TORSLstTransType 0 "Single Edge Sensor" 1 "Rising Transition" 2 "Falling Transition" 3 "Undefined";
VAL_ 199 TORSRotDir 0 "Unknown" 1 "Forward" 2 "Reverse" 3 "Undefined";
VAL_ 398 EngNTrnsRegStdyStTqV 0 "Valid" 1 "Invalid";
VAL_ 398 AccKdwnAtv 0 "false" 1 "true";
VAL_ 398 EngActStdyStTorqV 0 "Valid" 1 "Invalid";
VAL_ 398 TrnsEngSpdReqFld 0 "false" 1 "true";
VAL_ 398 PTACCAct 0 "false" 1 "true";
VAL_ 398 CTSS_StbltyLvl 0 "Level 0" 1 "Level 1" 2 "Level 2" 3 "Level 3" 4 "Level 4" 5 "Level 5" 6 "Level 6" 7 "Level 7";
VAL_ 398 CTSS_StbltyTyp 0 "Normal Stability" 1 "Torque High Pulsation" 2 "Torque Decrease Pending" 3 "Torque Increase Pending" 4 "Unused and Reserved 1" 5 "Unused and Reserved 2" 6 "Unused and Reserved 3" 7 "Unused and Reserved 4";
VAL_ 398 EngImmTrqTnsRqStat 0 "No Request" 1 "Request Honored" 2 "Lost Arbitration" 3 "Serial Data Failure Temporary" 4 "Serial Data Failure Permanent" 5 "Control System Failure Temporary" 6 "Control System Failure Permanent" 7 "Unused and Reserved";
VAL_ 398 EngImmTrqTnsRqLmSt 0 "Not Limited" 1 "Rate Limited" 2 "Value Limited Low" 3 "Value Limited High" 4 "Unused and Reserved 1" 5 "Unused and Reserved 2" 6 "Unused and Reserved 3" 7 "Unused and Reserved 4";
VAL_ 398 EngPrdctTrqTnsRqStat 0 "No Request" 1 "Request Honored" 2 "Lost Arbitration" 3 "Serial Data Failure Temporary" 4 "Serial Data Failure Permanent" 5 "Control System Failure Temporary" 6 "Control System Failure Permanent" 7 "Unused and Reserved";
VAL_ 398 EngPrdctTrqTnsRqLmS 0 "Not Limited" 1 "Rate Limited" 2 "Value Limited Low" 3 "Value Limited High" 4 "Unused and Reserved 1" 5 "Unused and Reserved 2" 6 "Unused and Reserved 3" 7 "Unused and Reserved 4";
VAL_ 464 FrtAxlOpeMod 0 "Open" 1 "Active" 2 "Locked" 3 "Unknown";
VAL_ 390 RdHVInvRatVltV 0 "Valid" 1 "Invalid";
VAL_ 390 EngActDmpgDsblReq 0 "false" 1 "true";
VAL_ 390 HybExtndDcFuelCORq 0 "false" 1 "true";
VAL_ 390 EstMtrPwrLossV 0 "Valid" 1 "Invalid";
VAL_ 390 HybCmmFailRdPwrCmd 0 "false" 1 "true";
VAL_ 390 HybACCompRq 0 "No Action" 1 "Engage" 2 "Disengage" 3 "Reserved";
VAL_ 390 HESSI_EngStrtTyp 0 "No Start" 1 "Key Start Normal" 2 "Key Start Low Power" 3 "Key Start Low Power B" 4 "Key Start Generic" 5 "Auto Start Smooth" 6 "Auto Start Normal" 7 "Auto Start Aggressive" 8 "Auto Start Generic" 9 "Compression Test";
VAL_ 390 HESSI_EngStrtStpMd 0 "Stop" 1 "Immediate Stop" 2 "Start Pending" 3 "Enable Fuel" 4 "Producing Torque" 5 "Disable Fuel" 6 "Stop Pending" 7 "Start Failed";
VAL_ 390 HybCrnkAbrtd 0 "false" 1 "true";
VAL_ 390 CnvntlEngStrtEnbld 0 "false" 1 "true";
VAL_ 390 HybEngCylDeactReq 0 "false" 1 "true";
VAL_ 390 HybDFCOReq 0 "DFCO Not Requested" 1 "DFCO Requested";
VAL_ 390 RdPTHVCntrReq 0 "Undetermined" 1 "Close Allowed" 2 "Request Open";
VAL_ 817 RrAxlTmpInhIO 0 "false" 1 "true";
VAL_ 817 RrAxlMalfIO 0 "false" 1 "true";
VAL_ 465 RrAxlOpeMod 0 "Open" 1 "Active" 2 "Locked" 3 "Unknown";
VAL_ 465 RrAxlEstTrqV 0 "Valid" 1 "Invalid";
VAL_ 465 RrAxlStat 0 "Normal" 1 "Temporary Inhibit" 2 "Temporary Limited" 3 "Permanently Failed";
VAL_ 465 RrAxlCtrlMod 0 "Internal" 1 "External";
VAL_ 465 RAMDVLAtv 0 "false" 1 "true";
VAL_ 460 SecAxlStat 0 "Normal" 1 "Temporary Inhibit" 2 "Temporary Limited" 3 "Permanently Failed";
VAL_ 460 SecAxlEstTrqV 0 "Valid" 1 "Invalid";
VAL_ 460 SAMDVLAtv 0 "false" 1 "true";
VAL_ 460 PTTrnsfrCseMd 0 "2 Wheel Drive High" 1 "4 Wheel Drive High" 2 "4 Wheel Drive Low" 3 "Neutral";
VAL_ 460 SecAxlCtrlMod 0 "Internal" 1 "External";
VAL_ 462 SATRCplReqAtv 0 "false" 1 "true";
VAL_ 463 FourWhlDrvIndReq 0 "No Indication" 1 "Indication 1" 2 "Indication 2" 3 "Indication 3" 4 "Indication 4" 5 "Indication 5" 6 "Indication 6" 7 "Unused and Reserved";
VAL_ 463 SecAxlNonEmMalfIO 0 "false" 1 "true";
VAL_ 463 SecAxlOperMod 0 "2 Wheel Drive High" 1 "4 Wheel Drive High Locked" 2 "4 Wheel Drive Low Locked" 3 "Active All Wheel Drive (High)" 4 "4 Wheel Drive High Open" 5 "4 Wheel Drive Low Open" 6 "Active All Wheel Drive (Low)" 7 "2 Wheel Drive Low" 14 "Unknown" 15 "Neutral";
VAL_ 463 SecAxlTmpInhIO 0 "false" 1 "true";
VAL_ 719 RVBATC_AxlTrqRqstAct 0 "false" 1 "true";
CM_ SG_ 979 BrkBstVac "0 kPA represents the sensor reading atmospheric pressure";
CM_ SG_ 1239 BatSOH "State of Health = the aging state of the Battery";
CM_ SG_ 398 EngNTrnsRegStdyStTqV "ETEI 3.1";
CM_ SG_ 398 EngNTrnsRegStdyStTq "ETEI 3.1";
CM_ SG_ 398 EngActStdyStTorq "ETEI 3.1";
CM_ SG_ 398 EngActStdyStTorqV "ETEI 3.1";
CM_ SG_ 390 HybDFCOReq "DFCO = Deceleration Fuel Cut Off";
CM_ BO_ 719 "Application Is Tx ing this frame at the rate of 40 ms";
BA_DEF_ SG_ "VNSigSLHS_VNReq" ENUM "No","Yes";
BA_DEF_ SG_ "VNSigSLHSSharedDiagnostic" ENUM "No","Yes";
BA_DEF_ SG_ "SignalType" STRING;
BA_DEF_ SG_ "PacketOrder" INT 0 65535;
BA_DEF_ SG_ "SignalLongName" STRING;
BA_DEF_ SG_ "GenSigStartValue" INT 0 65535;
BA_DEF_ SG_ "VNSigAllNodes" ENUM "No","Yes";
BA_DEF_ SG_ "GenSigDeltaValue" INT 0 0;
BA_DEF_ SG_ "GenSigSendType" ENUM "not used","not used","not used","not used","not used","not used","not used","NoSigSendType","not used","not used","OnAnyChange","OnChangeIfActive","OnDelta";
BA_DEF_ SG_ "GenSigSendOnInit" ENUM "Not Initialized","Application","Handler";
BA_DEF_ BO_ "AppGenMsgCycleTime" INT 0 0;
BA_DEF_ BO_ "GenMsgILSupport" ENUM "No","Yes";
BA_DEF_ BO_ "TpApplType" STRING;
BA_DEF_ BO_ "Prio" INT 0 7;
BA_DEF_ BO_ "MessageSubnet" ENUM "LS","MS","HS","CE","PE","HV","FO";
BA_DEF_ BO_ "DiagState" ENUM "No","Yes";
BA_DEF_ BO_ "GenMsgDelayTime" INT 0 100000;
BA_DEF_ BO_ "GenMsgCycleTime" INT 0 100000;
BA_DEF_ BO_ "GenMsgSendType" ENUM "cyclicX","spontanX","cyclicIfActiveX","spontanWithDelay","cyclicAndSpontanX","cyclicAndSpontanWithDelay","spontanWithRepitition","cyclicIfActiveAndSpontanWD";
BA_DEF_ BO_ "DiagResponse" ENUM "No","Yes";
BA_DEF_ BO_ "DiagRequest" ENUM "No","Yes";
BA_DEF_ BO_ "NmMessage" ENUM "No","Yes";
BA_DEF_DEF_ "VNSigSLHS_VNReq" "No";
BA_DEF_DEF_ "VNSigSLHSSharedDiagnostic" "No";
BA_DEF_DEF_ "SignalType" "";
BA_DEF_DEF_ "PacketOrder" 0;
BA_DEF_DEF_ "SignalLongName" "";
BA_DEF_DEF_ "GenSigStartValue" 0;
BA_DEF_DEF_ "VNSigAllNodes" "No";
BA_DEF_DEF_ "GenSigDeltaValue" 0;
BA_DEF_DEF_ "GenSigSendType" "NoSigSendType";
BA_DEF_DEF_ "GenSigSendOnInit" "Not Initialized";
BA_DEF_DEF_ "AppGenMsgCycleTime" 0;
BA_DEF_DEF_ "GenMsgILSupport" "Yes";
BA_DEF_DEF_ "TpApplType" "";
BA_DEF_DEF_ "Prio" 4;
BA_DEF_DEF_ "MessageSubnet" "FO";
BA_DEF_DEF_ "DiagState" "No";
BA_DEF_DEF_ "GenMsgDelayTime" 0;
BA_DEF_DEF_ "GenMsgCycleTime" 0;
BA_DEF_DEF_ "GenMsgSendType" "spontanX";
BA_DEF_DEF_ "DiagResponse" "No";
BA_DEF_DEF_ "DiagRequest" "No";
BA_DEF_DEF_ "NmMessage" "No";
BA_ "Prio" BO_ 1219 0;
BA_ "GenMsgSendType" BO_ 1219 0;
BA_ "GenMsgCycleTime" BO_ 1219 1000;
BA_ "MessageSubnet" BO_ 1219 2;
BA_ "VNSigAllNodes" SG_ 1219 DslExhFldDiagWrnIdRq 1;
BA_ "SignalLongName" SG_ 1219 DslExhFldDiagWrnIdRq "Diesel Exhaust Fluid System Diagnostic Warning Indication Request";
BA_ "SignalType" SG_ 1219 DslExhFldDiagWrnIdRq "ENM";
BA_ "VNSigAllNodes" SG_ 1219 DslEmnsOBDMrkt 1;
BA_ "SignalLongName" SG_ 1219 DslEmnsOBDMrkt "Diesel Emissions OBD Market";
BA_ "SignalType" SG_ 1219 DslEmnsOBDMrkt "ENM";
BA_ "VNSigAllNodes" SG_ 1219 DslExNxEmWrngIndRq 1;
BA_ "SignalLongName" SG_ 1219 DslExNxEmWrngIndRq "Diesel Exhaust NOx Emissions Too High Warning Indication Request";
BA_ "SignalType" SG_ 1219 DslExNxEmWrngIndRq "ENM";
BA_ "VNSigAllNodes" SG_ 1219 DEFWVSL_S3SpdLmt 1;
BA_ "PacketOrder" SG_ 1219 DEFWVSL_S3SpdLmt 3;
BA_ "SignalLongName" SG_ 1219 DEFWVSL_S3SpdLmt "Diesel Exhaust Fluid Warning Vehicle Speed Limit : Stage 3 Vehicle Speed Limit";
BA_ "SignalType" SG_ 1219 DEFWVSL_S3SpdLmt "UNM";
BA_ "VNSigAllNodes" SG_ 1219 DEFWVSL_S2SpdLmt 1;
BA_ "PacketOrder" SG_ 1219 DEFWVSL_S2SpdLmt 2;
BA_ "SignalLongName" SG_ 1219 DEFWVSL_S2SpdLmt "Diesel Exhaust Fluid Warning Vehicle Speed Limit : Stage 2 Vehicle Speed Limit";
BA_ "SignalType" SG_ 1219 DEFWVSL_S2SpdLmt "UNM";
BA_ "VNSigAllNodes" SG_ 1219 DEFWVSL_S1SpdLmt 1;
BA_ "PacketOrder" SG_ 1219 DEFWVSL_S1SpdLmt 1;
BA_ "SignalLongName" SG_ 1219 DEFWVSL_S1SpdLmt "Diesel Exhaust Fluid Warning Vehicle Speed Limit : Stage 1 Vehicle Speed Limit";
BA_ "SignalType" SG_ 1219 DEFWVSL_S1SpdLmt "UNM";
BA_ "VNSigAllNodes" SG_ 1219 DslExFldTpWrngIndRq 1;
BA_ "SignalLongName" SG_ 1219 DslExFldTpWrngIndRq "Diesel Exhaust Fluid Tampering Warning Indication Request";
BA_ "SignalType" SG_ 1219 DslExFldTpWrngIndRq "ENM";
BA_ "VNSigAllNodes" SG_ 1219 DslExhFldQlyWrngIReq 1;
BA_ "SignalLongName" SG_ 1219 DslExhFldQlyWrngIReq "Diesel Exhaust Fluid Quality Warning Indication Request";
BA_ "SignalType" SG_ 1219 DslExhFldQlyWrngIReq "ENM";
BA_ "VNSigAllNodes" SG_ 1219 DslExhFldWrngIdRqER 1;
BA_ "SignalLongName" SG_ 1219 DslExhFldWrngIdRqER "Diesel Exhaust Fluid Level Warning Indication Request Extended Range";
BA_ "SignalType" SG_ 1219 DslExhFldWrngIdRqER "ENM";
BA_ "VNSigAllNodes" SG_ 1219 DslExFldCnWrngIndRq 1;
BA_ "SignalLongName" SG_ 1219 DslExFldCnWrngIndRq "Diesel Exhaust Fluid Consumption Monitoring Warning Indication Request";
BA_ "SignalType" SG_ 1219 DslExFldCnWrngIndRq "ENM";
BA_ "Prio" BO_ 372 0;
BA_ "GenMsgSendType" BO_ 372 0;
BA_ "GenMsgCycleTime" BO_ 372 100;
BA_ "MessageSubnet" BO_ 372 2;
BA_ "VNSigAllNodes" SG_ 372 ARSFlrIO 1;
BA_ "SignalLongName" SG_ 372 ARSFlrIO "Active Rear Steer Failure Indication On";
BA_ "SignalType" SG_ 372 ARSFlrIO "BLN";
BA_ "Prio" BO_ 528 0;
BA_ "GenMsgSendType" BO_ 528 0;
BA_ "GenMsgCycleTime" BO_ 528 50;
BA_ "MessageSubnet" BO_ 528 2;
BA_ "VNSigAllNodes" SG_ 528 BrkSysAutBrkReqRC 1;
BA_ "SignalLongName" SG_ 528 BrkSysAutBrkReqRC "Brake System Autonomous Braking Request Rolling Count";
BA_ "SignalType" SG_ 528 BrkSysAutBrkReqRC "UNM";
BA_ "VNSigAllNodes" SG_ 528 BrkSysAutBrkReqPVal 1;
BA_ "SignalLongName" SG_ 528 BrkSysAutBrkReqPVal "Brake System Autonomous Braking Request Protection Value";
BA_ "SignalType" SG_ 528 BrkSysAutBrkReqPVal "UNM";
BA_ "VNSigAllNodes" SG_ 528 BSABR_TrlBrkRq 1;
BA_ "PacketOrder" SG_ 528 BSABR_TrlBrkRq 2;
BA_ "SignalLongName" SG_ 528 BSABR_TrlBrkRq "Brake System Autonomous Braking Request : Trailer Brake Request";
BA_ "SignalType" SG_ 528 BSABR_TrlBrkRq "UNM";
BA_ "VNSigAllNodes" SG_ 528 BSABR_TrlBrkCntlIntRq 1;
BA_ "SignalLongName" SG_ 528 BSABR_TrlBrkCntlIntRq "Brake System Autonomous Braking Request : Trailer Brake Control Interactive Request";
BA_ "SignalType" SG_ 528 BSABR_TrlBrkCntlIntRq "BLN";
BA_ "Prio" BO_ 552 0;
BA_ "GenMsgSendType" BO_ 552 0;
BA_ "GenMsgCycleTime" BO_ 552 100;
BA_ "MessageSubnet" BO_ 552 2;
BA_ "VNSigAllNodes" SG_ 552 ThrmlRefCmpIGBTTmpV 1;
BA_ "SignalLongName" SG_ 552 ThrmlRefCmpIGBTTmpV "Thermal Refrigerant Compressor Insulated Gate Bipolar Transistor Temperature Validity";
BA_ "SignalType" SG_ 552 ThrmlRefCmpIGBTTmpV "ENM";
BA_ "VNSigAllNodes" SG_ 552 ThrmlRefCmpIGBTTmp 1;
BA_ "SignalLongName" SG_ 552 ThrmlRefCmpIGBTTmp "Thermal Refrigerant Compressor Insulated Gate Bipolar Transistor Temperature";
BA_ "SignalType" SG_ 552 ThrmlRefCmpIGBTTmp "UNM";
BA_ "VNSigAllNodes" SG_ 552 ThrmlRefCmpHiVltgInptV 1;
BA_ "SignalLongName" SG_ 552 ThrmlRefCmpHiVltgInptV "Thermal Refrigerant Compressor High Voltage Input Validity";
BA_ "SignalType" SG_ 552 ThrmlRefCmpHiVltgInptV "ENM";
BA_ "VNSigAllNodes" SG_ 552 ThrmlRefCmpHiVltgInpt 1;
BA_ "SignalLongName" SG_ 552 ThrmlRefCmpHiVltgInpt "Thermal Refrigerant Compressor High Voltage Input";
BA_ "SignalType" SG_ 552 ThrmlRefCmpHiVltgInpt "UNM";
BA_ "VNSigAllNodes" SG_ 552 ThrmlRefCmpCPUHtSkTmpV 1;
BA_ "SignalLongName" SG_ 552 ThrmlRefCmpCPUHtSkTmpV "Thermal Refrigerant Compressor Central Processing Unit Heat Sink Temperature Validity";
BA_ "SignalType" SG_ 552 ThrmlRefCmpCPUHtSkTmpV "ENM";
BA_ "VNSigAllNodes" SG_ 552 ThrmlRefCmpCPUHtSkTmp 1;
BA_ "SignalLongName" SG_ 552 ThrmlRefCmpCPUHtSkTmp "Thermal Refrigerant Compressor Central Processing Unit Heat Sink Temperature";
BA_ "SignalType" SG_ 552 ThrmlRefCmpCPUHtSkTmp "UNM";
BA_ "Prio" BO_ 442 0;
BA_ "GenMsgSendType" BO_ 442 0;
BA_ "GenMsgCycleTime" BO_ 442 25;
BA_ "MessageSubnet" BO_ 442 2;
BA_ "VNSigAllNodes" SG_ 442 CrksftTqMinImCapV 1;
BA_ "SignalLongName" SG_ 442 CrksftTqMinImCapV "Crankshaft Torque Minimum Immediate Capacity Validity";
BA_ "SignalType" SG_ 442 CrksftTqMinImCapV "ENM";
BA_ "VNSigAllNodes" SG_ 442 CrksftTqMinImCap 1;
BA_ "SignalLongName" SG_ 442 CrksftTqMinImCap "Crankshaft Torque Minimum Immediate Capacity";
BA_ "SignalType" SG_ 442 CrksftTqMinImCap "UNM";
BA_ "VNSigAllNodes" SG_ 442 DrvIntndCrksftTrqRw 1;
BA_ "SignalLongName" SG_ 442 DrvIntndCrksftTrqRw "Driver Intended Crankshaft Torque Raw";
BA_ "SignalType" SG_ 442 DrvIntndCrksftTrqRw "UNM";
BA_ "VNSigAllNodes" SG_ 442 DrvIntndCrksftTrqMin 1;
BA_ "SignalLongName" SG_ 442 DrvIntndCrksftTrqMin "Driver Intended Crankshaft Torque Minimum";
BA_ "SignalType" SG_ 442 DrvIntndCrksftTrqMin "UNM";
BA_ "VNSigAllNodes" SG_ 442 DrvIntndCrksftTrq 1;
BA_ "SignalLongName" SG_ 442 DrvIntndCrksftTrq "Driver Intended Crankshaft Torque";
BA_ "SignalType" SG_ 442 DrvIntndCrksftTrq "UNM";
BA_ "VNSigAllNodes" SG_ 442 CrksftMaxTrqLmtV 1;
BA_ "SignalLongName" SG_ 442 CrksftMaxTrqLmtV "Crankshaft Maximum Torque Limit Validity";
BA_ "SignalType" SG_ 442 CrksftMaxTrqLmtV "ENM";
BA_ "VNSigAllNodes" SG_ 442 CrksftMaxTrqLmt 1;
BA_ "SignalLongName" SG_ 442 CrksftMaxTrqLmt "Crankshaft Maximum Torque Limit";
BA_ "SignalType" SG_ 442 CrksftMaxTrqLmt "UNM";
BA_ "Prio" BO_ 753 0;
BA_ "GenMsgSendType" BO_ 753 0;
BA_ "GenMsgCycleTime" BO_ 753 100;
BA_ "MessageSubnet" BO_ 753 2;
BA_ "VNSigAllNodes" SG_ 753 EBCMDS5_DTCStatus 1;
BA_ "SignalLongName" SG_ 753 EBCMDS5_DTCStatus "Electronic Brake Control Module Diagnostic Status 5 : Diagnostic Trouble Code Status";
BA_ "SignalType" SG_ 753 EBCMDS5_DTCStatus "ENM";
BA_ "VNSigAllNodes" SG_ 753 EBCMDS5_DTCIndex 1;
BA_ "PacketOrder" SG_ 753 EBCMDS5_DTCIndex 2;
BA_ "SignalLongName" SG_ 753 EBCMDS5_DTCIndex "Electronic Brake Control Module Diagnostic Status 5 : Diagnostic Trouble Code Index";
BA_ "SignalType" SG_ 753 EBCMDS5_DTCIndex "UNM";
BA_ "VNSigAllNodes" SG_ 753 EBCMDS4_DTCStatus 1;
BA_ "PacketOrder" SG_ 753 EBCMDS4_DTCStatus 1;
BA_ "SignalLongName" SG_ 753 EBCMDS4_DTCStatus "Electronic Brake Control Module Diagnostic Status 4 : Diagnostic Trouble Code Status";
BA_ "SignalType" SG_ 753 EBCMDS4_DTCStatus "ENM";
BA_ "VNSigAllNodes" SG_ 753 EBCMDS4_DTCIndex 1;
BA_ "PacketOrder" SG_ 753 EBCMDS4_DTCIndex 2;
BA_ "SignalLongName" SG_ 753 EBCMDS4_DTCIndex "Electronic Brake Control Module Diagnostic Status 4 : Diagnostic Trouble Code Index";
BA_ "SignalType" SG_ 753 EBCMDS4_DTCIndex "UNM";
BA_ "VNSigAllNodes" SG_ 753 EBCMDS3_DTCStatus 1;
BA_ "PacketOrder" SG_ 753 EBCMDS3_DTCStatus 1;
BA_ "SignalLongName" SG_ 753 EBCMDS3_DTCStatus "Electronic Brake Control Module Diagnostic Status 3 : Diagnostic Trouble Code Status";
BA_ "SignalType" SG_ 753 EBCMDS3_DTCStatus "ENM";
BA_ "VNSigAllNodes" SG_ 753 EBCMDS3_DTCIndex 1;
BA_ "PacketOrder" SG_ 753 EBCMDS3_DTCIndex 2;
BA_ "SignalLongName" SG_ 753 EBCMDS3_DTCIndex "Electronic Brake Control Module Diagnostic Status 3 : Diagnostic Trouble Code Index";
BA_ "SignalType" SG_ 753 EBCMDS3_DTCIndex "UNM";
BA_ "VNSigAllNodes" SG_ 753 EBCMDS2_DTCStatus 1;
BA_ "PacketOrder" SG_ 753 EBCMDS2_DTCStatus 1;
BA_ "SignalLongName" SG_ 753 EBCMDS2_DTCStatus "Electronic Brake Control Module Diagnostic Status 2 : Diagnostic Trouble Code Status";
BA_ "SignalType" SG_ 753 EBCMDS2_DTCStatus "ENM";
BA_ "VNSigAllNodes" SG_ 753 EBCMDS2_DTCIndex 1;
BA_ "PacketOrder" SG_ 753 EBCMDS2_DTCIndex 2;
BA_ "SignalLongName" SG_ 753 EBCMDS2_DTCIndex "Electronic Brake Control Module Diagnostic Status 2 : Diagnostic Trouble Code Index";
BA_ "SignalType" SG_ 753 EBCMDS2_DTCIndex "UNM";
BA_ "VNSigAllNodes" SG_ 753 EBCMDS1_DTCStatus 1;
BA_ "PacketOrder" SG_ 753 EBCMDS1_DTCStatus 1;
BA_ "SignalLongName" SG_ 753 EBCMDS1_DTCStatus "Electronic Brake Control Module Diagnostic Status 1 : Diagnostic Trouble Code Status";
BA_ "SignalType" SG_ 753 EBCMDS1_DTCStatus "ENM";
BA_ "VNSigAllNodes" SG_ 753 EBCMDS1_DTCIndex 1;
BA_ "PacketOrder" SG_ 753 EBCMDS1_DTCIndex 2;
BA_ "SignalLongName" SG_ 753 EBCMDS1_DTCIndex "Electronic Brake Control Module Diagnostic Status 1 : Diagnostic Trouble Code Index";
BA_ "SignalType" SG_ 753 EBCMDS1_DTCIndex "UNM";
BA_ "Prio" BO_ 989 0;
BA_ "GenMsgSendType" BO_ 989 0;
BA_ "GenMsgCycleTime" BO_ 989 100;
BA_ "MessageSubnet" BO_ 989 2;
BA_ "VNSigAllNodes" SG_ 989 RdHVCntctrShdwnReq 1;
BA_ "SignalLongName" SG_ 989 RdHVCntctrShdwnReq "Redundant High Voltage Contactor Shutdown Request";
BA_ "SignalType" SG_ 989 RdHVCntctrShdwnReq "ENM";
BA_ "VNSigAllNodes" SG_ 989 AuxClntHtrVlvStat 1;
BA_ "SignalLongName" SG_ 989 AuxClntHtrVlvStat "Auxiliary Coolant Heater Valve Status";
BA_ "SignalType" SG_ 989 AuxClntHtrVlvStat "ENM";
BA_ "VNSigAllNodes" SG_ 989 EngCoolFanOpEnbl 1;
BA_ "SignalLongName" SG_ 989 EngCoolFanOpEnbl "Engine Cooling Fan Operation Enable";
BA_ "SignalType" SG_ 989 EngCoolFanOpEnbl "BLN";
BA_ "VNSigAllNodes" SG_ 989 DiagFreeRunCntrV 1;
BA_ "SignalLongName" SG_ 989 DiagFreeRunCntrV "Diagnostic Free Running Counter Validity";
BA_ "SignalType" SG_ 989 DiagFreeRunCntrV "ENM";
BA_ "VNSigAllNodes" SG_ 989 DiagFreeRunCntr 1;
BA_ "SignalLongName" SG_ 989 DiagFreeRunCntr "Diagnostic Free Running Counter";
BA_ "SignalType" SG_ 989 DiagFreeRunCntr "UNM";
BA_ "VNSigAllNodes" SG_ 989 HybFanSpdRq 1;
BA_ "SignalLongName" SG_ 989 HybFanSpdRq "Hybrid Fan Speed Percent Request";
BA_ "SignalType" SG_ 989 HybFanSpdRq "UNM";
BA_ "VNSigAllNodes" SG_ 989 MntnceMdStEngRq 1;
BA_ "SignalLongName" SG_ 989 MntnceMdStEngRq "Maintenance Mode Start Engine Request";
BA_ "SignalType" SG_ 989 MntnceMdStEngRq "BLN";
BA_ "VNSigAllNodes" SG_ 989 RdHVCntctrCmdStat 1;
BA_ "SignalLongName" SG_ 989 RdHVCntctrCmdStat "Redundant High Voltage Contactor Command Status";
BA_ "SignalType" SG_ 989 RdHVCntctrCmdStat "ENM";
BA_ "Prio" BO_ 550 0;
BA_ "GenMsgSendType" BO_ 550 0;
BA_ "GenMsgCycleTime" BO_ 550 500;
BA_ "MessageSubnet" BO_ 550 2;
BA_ "VNSigAllNodes" SG_ 550 ACCMCII_DtBtG 1;
BA_ "PacketOrder" SG_ 550 ACCMCII_DtBtG 10;
BA_ "SignalLongName" SG_ 550 ACCMCII_DtBtG "Air Compressor Control Module Calibration Identification : Data Byte G";
BA_ "SignalType" SG_ 550 ACCMCII_DtBtG "ASC";
BA_ "VNSigAllNodes" SG_ 550 ACCMCII_DtBtF 1;
BA_ "PacketOrder" SG_ 550 ACCMCII_DtBtF 9;
BA_ "SignalLongName" SG_ 550 ACCMCII_DtBtF "Air Compressor Control Module Calibration Identification : Data Byte F";
BA_ "SignalType" SG_ 550 ACCMCII_DtBtF "ASC";
BA_ "VNSigAllNodes" SG_ 550 ACCMCII_DtBtE 1;
BA_ "PacketOrder" SG_ 550 ACCMCII_DtBtE 8;
BA_ "SignalLongName" SG_ 550 ACCMCII_DtBtE "Air Compressor Control Module Calibration Identification : Data Byte E";
BA_ "SignalType" SG_ 550 ACCMCII_DtBtE "ASC";
BA_ "VNSigAllNodes" SG_ 550 ACCMCII_DtBtD 1;
BA_ "PacketOrder" SG_ 550 ACCMCII_DtBtD 7;
BA_ "SignalLongName" SG_ 550 ACCMCII_DtBtD "Air Compressor Control Module Calibration Identification : Data Byte D";
BA_ "SignalType" SG_ 550 ACCMCII_DtBtD "ASC";
BA_ "VNSigAllNodes" SG_ 550 ACCMCII_DtBtC 1;
BA_ "SignalLongName" SG_ 550 ACCMCII_DtBtC "Air Compressor Control Module Calibration Identification : Data Byte C";
BA_ "SignalType" SG_ 550 ACCMCII_DtBtC "ASC";
BA_ "VNSigAllNodes" SG_ 550 ACCMCII_DtBtB 1;
BA_ "PacketOrder" SG_ 550 ACCMCII_DtBtB 5;
BA_ "SignalLongName" SG_ 550 ACCMCII_DtBtB "Air Compressor Control Module Calibration Identification : Data Byte B";
BA_ "SignalType" SG_ 550 ACCMCII_DtBtB "ASC";
BA_ "VNSigAllNodes" SG_ 550 ACCMCII_DtBtA 1;
BA_ "PacketOrder" SG_ 550 ACCMCII_DtBtA 4;
BA_ "SignalLongName" SG_ 550 ACCMCII_DtBtA "Air Compressor Control Module Calibration Identification : Data Byte A";
BA_ "SignalType" SG_ 550 ACCMCII_DtBtA "ASC";
BA_ "VNSigAllNodes" SG_ 550 ACCMCII_SeqNum 1;
BA_ "PacketOrder" SG_ 550 ACCMCII_SeqNum 3;
BA_ "SignalLongName" SG_ 550 ACCMCII_SeqNum "Air Compressor Control Module Calibration Identification : Sequence Number";
BA_ "SignalType" SG_ 550 ACCMCII_SeqNum "UNM";
BA_ "VNSigAllNodes" SG_ 550 ACCMCII_Index 1;
BA_ "PacketOrder" SG_ 550 ACCMCII_Index 1;
BA_ "SignalLongName" SG_ 550 ACCMCII_Index "Air Compressor Control Module Calibration Identification : Index";
BA_ "SignalType" SG_ 550 ACCMCII_Index "UNM";
BA_ "VNSigAllNodes" SG_ 550 ACCMCII_DatStat 1;
BA_ "PacketOrder" SG_ 550 ACCMCII_DatStat 2;
BA_ "SignalLongName" SG_ 550 ACCMCII_DatStat "Air Compressor Control Module Calibration Identification : Data Status";
BA_ "SignalType" SG_ 550 ACCMCII_DatStat "ENM";
BA_ "Prio" BO_ 548 0;
BA_ "GenMsgSendType" BO_ 548 0;
BA_ "GenMsgCycleTime" BO_ 548 100;
BA_ "MessageSubnet" BO_ 548 2;
BA_ "VNSigAllNodes" SG_ 548 ACCMDSO_DTCStat 1;
BA_ "PacketOrder" SG_ 548 ACCMDSO_DTCStat 1;
BA_ "SignalLongName" SG_ 548 ACCMDSO_DTCStat "Air Compressor Control Module Diagnostic Status Outputs : Diagnostic Trouble Code Status";
BA_ "SignalType" SG_ 548 ACCMDSO_DTCStat "ENM";
BA_ "VNSigAllNodes" SG_ 548 ACCMDSO_DTCIndx 1;
BA_ "PacketOrder" SG_ 548 ACCMDSO_DTCIndx 2;
BA_ "SignalLongName" SG_ 548 ACCMDSO_DTCIndx "Air Compressor Control Module Diagnostic Status Outputs : Diagnostic Trouble Code Index";
BA_ "SignalType" SG_ 548 ACCMDSO_DTCIndx "UNM";
BA_ "VNSigAllNodes" SG_ 548 ACCMDSI_DTCStat 1;
BA_ "PacketOrder" SG_ 548 ACCMDSI_DTCStat 1;
BA_ "SignalLongName" SG_ 548 ACCMDSI_DTCStat "Air Compressor Control Module Diagnostic Status Inputs : Diagnostic Trouble Code Status";
BA_ "SignalType" SG_ 548 ACCMDSI_DTCStat "ENM";
BA_ "VNSigAllNodes" SG_ 548 ACCMDSI_DTCIndx 1;
BA_ "PacketOrder" SG_ 548 ACCMDSI_DTCIndx 2;
BA_ "SignalLongName" SG_ 548 ACCMDSI_DTCIndx "Air Compressor Control Module Diagnostic Status Inputs : Diagnostic Trouble Code Index";
BA_ "SignalType" SG_ 548 ACCMDSI_DTCIndx "UNM";
BA_ "VNSigAllNodes" SG_ 548 ACCMDSG_DTCStat 1;
BA_ "PacketOrder" SG_ 548 ACCMDSG_DTCStat 1;
BA_ "SignalLongName" SG_ 548 ACCMDSG_DTCStat "Air Compressor Control Module Diagnostic Status General : Diagnostic Trouble Code Status";
BA_ "SignalType" SG_ 548 ACCMDSG_DTCStat "ENM";
BA_ "VNSigAllNodes" SG_ 548 ACCMDSG_DTCIndx 1;
BA_ "PacketOrder" SG_ 548 ACCMDSG_DTCIndx 2;
BA_ "SignalLongName" SG_ 548 ACCMDSG_DTCIndx "Air Compressor Control Module Diagnostic Status General : Diagnostic Trouble Code Index";
BA_ "SignalType" SG_ 548 ACCMDSG_DTCIndx "UNM";
BA_ "Prio" BO_ 988 0;
BA_ "GenMsgSendType" BO_ 988 0;
BA_ "GenMsgCycleTime" BO_ 988 100;
BA_ "MessageSubnet" BO_ 988 2;
BA_ "VNSigAllNodes" SG_ 988 AccPwrModMinCoolRq 1;
BA_ "SignalLongName" SG_ 988 AccPwrModMinCoolRq "Accessory Power Module Minimum Cooling Request";
BA_ "SignalType" SG_ 988 AccPwrModMinCoolRq "ENM";
BA_ "VNSigAllNodes" SG_ 988 A6ERRAlrmTime 1;
BA_ "PacketOrder" SG_ 988 A6ERRAlrmTime 2;
BA_ "SignalLongName" SG_ 988 A6ERRAlrmTime "Alarm 6 Extended Range Request : Alarm Time";
BA_ "SignalType" SG_ 988 A6ERRAlrmTime "UNM";
BA_ "VNSigAllNodes" SG_ 988 A6ERRAlrmReq 1;
BA_ "PacketOrder" SG_ 988 A6ERRAlrmReq 1;
BA_ "SignalLongName" SG_ 988 A6ERRAlrmReq "Alarm 6 Extended Range Request : Alarm Request";
BA_ "SignalType" SG_ 988 A6ERRAlrmReq "ENM";
BA_ "VNSigAllNodes" SG_ 988 EngMntncePrcntCpl 1;
BA_ "SignalLongName" SG_ 988 EngMntncePrcntCpl "Engine Maintenance Percent Complete";
BA_ "SignalType" SG_ 988 EngMntncePrcntCpl "UNM";
BA_ "VNSigAllNodes" SG_ 988 MntnceMdDsplyRq 1;
BA_ "SignalLongName" SG_ 988 MntnceMdDsplyRq "Maintenance Mode Display Request";
BA_ "SignalType" SG_ 988 MntnceMdDsplyRq "ENM";
BA_ "VNSigAllNodes" SG_ 988 EngMntnceMdAct 1;
BA_ "SignalLongName" SG_ 988 EngMntnceMdAct "Engine Maintenance Mode Active";
BA_ "SignalType" SG_ 988 EngMntnceMdAct "BLN";
BA_ "VNSigAllNodes" SG_ 988 HVPropChgrUnbl 1;
BA_ "SignalLongName" SG_ 988 HVPropChgrUnbl "High Voltage Propulsion Charging Unavailable";
BA_ "SignalType" SG_ 988 HVPropChgrUnbl "BLN";
BA_ "VNSigAllNodes" SG_ 988 EngHtrValvBpasCmd 1;
BA_ "SignalLongName" SG_ 988 EngHtrValvBpasCmd "Engine Heater Valve Bypass Command";
BA_ "SignalType" SG_ 988 EngHtrValvBpasCmd "ENM";
BA_ "Prio" BO_ 1029 0;
BA_ "GenMsgSendType" BO_ 1029 0;
BA_ "GenMsgCycleTime" BO_ 1029 100;
BA_ "MessageSubnet" BO_ 1029 2;
BA_ "VNSigAllNodes" SG_ 1029 FCO6D_ObjVertVar 1;
BA_ "PacketOrder" SG_ 1029 FCO6D_ObjVertVar 8;
BA_ "SignalLongName" SG_ 1029 FCO6D_ObjVertVar "Forward Camera Object 6 Detected : Object Vertical Variance";
BA_ "SignalType" SG_ 1029 FCO6D_ObjVertVar "SNM";
BA_ "VNSigAllNodes" SG_ 1029 FCO6D_ObjVertPos 1;
BA_ "PacketOrder" SG_ 1029 FCO6D_ObjVertPos 7;
BA_ "SignalLongName" SG_ 1029 FCO6D_ObjVertPos "Forward Camera Object 6 Detected : Object Vertical Position";
BA_ "SignalType" SG_ 1029 FCO6D_ObjVertPos "SNM";
BA_ "VNSigAllNodes" SG_ 1029 FCO6D_ObjTyp 1;
BA_ "PacketOrder" SG_ 1029 FCO6D_ObjTyp 3;
BA_ "SignalLongName" SG_ 1029 FCO6D_ObjTyp "Forward Camera Object 6 Detected : Object Type";
BA_ "SignalType" SG_ 1029 FCO6D_ObjTyp "ENM";
BA_ "VNSigAllNodes" SG_ 1029 FCO6D_ObjQlty 1;
BA_ "PacketOrder" SG_ 1029 FCO6D_ObjQlty 1;
BA_ "SignalLongName" SG_ 1029 FCO6D_ObjQlty "Forward Camera Object 6 Detected : Object Quality";
BA_ "SignalType" SG_ 1029 FCO6D_ObjQlty "ENM";
BA_ "VNSigAllNodes" SG_ 1029 FCO6D_ObjId 1;
BA_ "PacketOrder" SG_ 1029 FCO6D_ObjId 2;
BA_ "SignalLongName" SG_ 1029 FCO6D_ObjId "Forward Camera Object 6 Detected : Object ID";
BA_ "SignalType" SG_ 1029 FCO6D_ObjId "UNM";
BA_ "VNSigAllNodes" SG_ 1029 FCO6D_ObjHorzPos 1;
BA_ "PacketOrder" SG_ 1029 FCO6D_ObjHorzPos 4;
BA_ "SignalLongName" SG_ 1029 FCO6D_ObjHorzPos "Forward Camera Object 6 Detected : Object Horizontal Position";
BA_ "SignalType" SG_ 1029 FCO6D_ObjHorzPos "SNM";
BA_ "VNSigAllNodes" SG_ 1029 FCO6D_ObjHorzDim 1;
BA_ "PacketOrder" SG_ 1029 FCO6D_ObjHorzDim 6;
BA_ "SignalLongName" SG_ 1029 FCO6D_ObjHorzDim "Forward Camera Object 6 Detected : Object Horizontal Dimension";
BA_ "SignalType" SG_ 1029 FCO6D_ObjHorzDim "UNM";
BA_ "VNSigAllNodes" SG_ 1029 FCO6D_ObjDist 1;
BA_ "PacketOrder" SG_ 1029 FCO6D_ObjDist 9;
BA_ "SignalLongName" SG_ 1029 FCO6D_ObjDist "Forward Camera Object 6 Detected : Object Distance";
BA_ "SignalType" SG_ 1029 FCO6D_ObjDist "UNM";
BA_ "VNSigAllNodes" SG_ 1029 FCO6D_DetMthd 1;
BA_ "PacketOrder" SG_ 1029 FCO6D_DetMthd 5;
BA_ "SignalLongName" SG_ 1029 FCO6D_DetMthd "Forward Camera Object 6 Detected : Detection Method";
BA_ "SignalType" SG_ 1029 FCO6D_DetMthd "ENM";
BA_ "Prio" BO_ 1028 0;
BA_ "GenMsgSendType" BO_ 1028 0;
BA_ "GenMsgCycleTime" BO_ 1028 100;
BA_ "MessageSubnet" BO_ 1028 2;
BA_ "VNSigAllNodes" SG_ 1028 FCO5D_ObjVertVar 1;
BA_ "PacketOrder" SG_ 1028 FCO5D_ObjVertVar 8;
BA_ "SignalLongName" SG_ 1028 FCO5D_ObjVertVar "Forward Camera Object 5 Detected : Object Vertical Variance";
BA_ "SignalType" SG_ 1028 FCO5D_ObjVertVar "SNM";
BA_ "VNSigAllNodes" SG_ 1028 FCO5D_ObjVertPos 1;
BA_ "PacketOrder" SG_ 1028 FCO5D_ObjVertPos 7;
BA_ "SignalLongName" SG_ 1028 FCO5D_ObjVertPos "Forward Camera Object 5 Detected : Object Vertical Position";
BA_ "SignalType" SG_ 1028 FCO5D_ObjVertPos "SNM";
BA_ "VNSigAllNodes" SG_ 1028 FCO5D_ObjTyp 1;
BA_ "PacketOrder" SG_ 1028 FCO5D_ObjTyp 3;
BA_ "SignalLongName" SG_ 1028 FCO5D_ObjTyp "Forward Camera Object 5 Detected : Object Type";
BA_ "SignalType" SG_ 1028 FCO5D_ObjTyp "ENM";
BA_ "VNSigAllNodes" SG_ 1028 FCO5D_ObjQlty 1;
BA_ "PacketOrder" SG_ 1028 FCO5D_ObjQlty 1;
BA_ "SignalLongName" SG_ 1028 FCO5D_ObjQlty "Forward Camera Object 5 Detected : Object Quality";
BA_ "SignalType" SG_ 1028 FCO5D_ObjQlty "ENM";
BA_ "VNSigAllNodes" SG_ 1028 FCO5D_ObjId 1;
BA_ "PacketOrder" SG_ 1028 FCO5D_ObjId 2;
BA_ "SignalLongName" SG_ 1028 FCO5D_ObjId "Forward Camera Object 5 Detected : Object ID";
BA_ "SignalType" SG_ 1028 FCO5D_ObjId "UNM";
BA_ "VNSigAllNodes" SG_ 1028 FCO5D_ObjHorzPos 1;
BA_ "PacketOrder" SG_ 1028 FCO5D_ObjHorzPos 4;
BA_ "SignalLongName" SG_ 1028 FCO5D_ObjHorzPos "Forward Camera Object 5 Detected : Object Horizontal Position";
BA_ "SignalType" SG_ 1028 FCO5D_ObjHorzPos "SNM";
BA_ "VNSigAllNodes" SG_ 1028 FCO5D_ObjHorzDim 1;
BA_ "PacketOrder" SG_ 1028 FCO5D_ObjHorzDim 6;
BA_ "SignalLongName" SG_ 1028 FCO5D_ObjHorzDim "Forward Camera Object 5 Detected : Object Horizontal Dimension";
BA_ "SignalType" SG_ 1028 FCO5D_ObjHorzDim "UNM";
BA_ "VNSigAllNodes" SG_ 1028 FCO5D_ObjDist 1;
BA_ "PacketOrder" SG_ 1028 FCO5D_ObjDist 9;
BA_ "SignalLongName" SG_ 1028 FCO5D_ObjDist "Forward Camera Object 5 Detected : Object Distance";
BA_ "SignalType" SG_ 1028 FCO5D_ObjDist "UNM";
BA_ "VNSigAllNodes" SG_ 1028 FCO5D_DetMthd 1;
BA_ "PacketOrder" SG_ 1028 FCO5D_DetMthd 5;
BA_ "SignalLongName" SG_ 1028 FCO5D_DetMthd "Forward Camera Object 5 Detected : Detection Method";
BA_ "SignalType" SG_ 1028 FCO5D_DetMthd "ENM";
BA_ "Prio" BO_ 500 0;
BA_ "GenMsgSendType" BO_ 500 0;
BA_ "GenMsgCycleTime" BO_ 500 25;
BA_ "MessageSubnet" BO_ 500 2;
BA_ "VNSigAllNodes" SG_ 500 EnhDrvMdSwChUseAct 1;
BA_ "SignalLongName" SG_ 500 EnhDrvMdSwChUseAct "Enhanced Driver Selected Mode Switch Chassis Use Active";
BA_ "SignalType" SG_ 500 EnhDrvMdSwChUseAct "BLN";
BA_ "VNSigAllNodes" SG_ 500 EnhDrvSelMdSwStat 1;
BA_ "SignalLongName" SG_ 500 EnhDrvSelMdSwStat "Enhanced Driver Selected Mode Switch Status";
BA_ "SignalType" SG_ 500 EnhDrvSelMdSwStat "ENM";
BA_ "VNSigAllNodes" SG_ 500 DrvSelMd8Stat 1;
BA_ "GenSigSendType" SG_ 500 DrvSelMd8Stat 10;
BA_ "SignalLongName" SG_ 500 DrvSelMd8Stat "Driver Selected Mode 8 Status";
BA_ "SignalType" SG_ 500 DrvSelMd8Stat "ENM";
BA_ "VNSigAllNodes" SG_ 500 DrvSelMd8ReqDnd 1;
BA_ "GenSigSendType" SG_ 500 DrvSelMd8ReqDnd 10;
BA_ "SignalLongName" SG_ 500 DrvSelMd8ReqDnd "Driver Selected Mode 8 Request Denied";
BA_ "SignalType" SG_ 500 DrvSelMd8ReqDnd "BLN";
BA_ "VNSigAllNodes" SG_ 500 DrvSelMd7Stat 1;
BA_ "GenSigSendType" SG_ 500 DrvSelMd7Stat 10;
BA_ "SignalLongName" SG_ 500 DrvSelMd7Stat "Driver Selected Mode 7 Status";
BA_ "SignalType" SG_ 500 DrvSelMd7Stat "ENM";
BA_ "VNSigAllNodes" SG_ 500 DrvSelMd7ReqDnd 1;
BA_ "GenSigSendType" SG_ 500 DrvSelMd7ReqDnd 10;
BA_ "SignalLongName" SG_ 500 DrvSelMd7ReqDnd "Driver Selected Mode 7 Request Denied";
BA_ "SignalType" SG_ 500 DrvSelMd7ReqDnd "BLN";
BA_ "VNSigAllNodes" SG_ 500 DrvSelMd6Stat 1;
BA_ "GenSigSendType" SG_ 500 DrvSelMd6Stat 10;
BA_ "SignalLongName" SG_ 500 DrvSelMd6Stat "Driver Selected Mode 6 Status";
BA_ "SignalType" SG_ 500 DrvSelMd6Stat "ENM";
BA_ "VNSigAllNodes" SG_ 500 DrvSelMd6ReqDnd 1;
BA_ "GenSigSendType" SG_ 500 DrvSelMd6ReqDnd 10;
BA_ "SignalLongName" SG_ 500 DrvSelMd6ReqDnd "Driver Selected Mode 6 Request Denied";
BA_ "SignalType" SG_ 500 DrvSelMd6ReqDnd "BLN";
BA_ "VNSigAllNodes" SG_ 500 DrvSelMd5Stat 1;
BA_ "GenSigSendType" SG_ 500 DrvSelMd5Stat 10;
BA_ "SignalLongName" SG_ 500 DrvSelMd5Stat "Driver Selected Mode 5 Status";
BA_ "SignalType" SG_ 500 DrvSelMd5Stat "ENM";
BA_ "VNSigAllNodes" SG_ 500 DrvSelMd5ReqDnd 1;
BA_ "GenSigSendType" SG_ 500 DrvSelMd5ReqDnd 10;
BA_ "SignalLongName" SG_ 500 DrvSelMd5ReqDnd "Driver Selected Mode 5 Request Denied";
BA_ "SignalType" SG_ 500 DrvSelMd5ReqDnd "BLN";
BA_ "VNSigAllNodes" SG_ 500 DrvSelMd4Stat 1;
BA_ "GenSigSendType" SG_ 500 DrvSelMd4Stat 10;
BA_ "SignalLongName" SG_ 500 DrvSelMd4Stat "Driver Selected Mode 4 Status";
BA_ "SignalType" SG_ 500 DrvSelMd4Stat "ENM";
BA_ "VNSigAllNodes" SG_ 500 DrvSelMd4ReqDnd 1;
BA_ "GenSigSendType" SG_ 500 DrvSelMd4ReqDnd 10;
BA_ "SignalLongName" SG_ 500 DrvSelMd4ReqDnd "Driver Selected Mode 4 Request Denied";
BA_ "SignalType" SG_ 500 DrvSelMd4ReqDnd "BLN";
BA_ "VNSigAllNodes" SG_ 500 DrvSelMd3Stat 1;
BA_ "GenSigSendType" SG_ 500 DrvSelMd3Stat 10;
BA_ "SignalLongName" SG_ 500 DrvSelMd3Stat "Driver Selected Mode 3 Status";
BA_ "SignalType" SG_ 500 DrvSelMd3Stat "ENM";
BA_ "VNSigAllNodes" SG_ 500 DrvSelMd3ReqDnd 1;
BA_ "GenSigSendType" SG_ 500 DrvSelMd3ReqDnd 10;
BA_ "SignalLongName" SG_ 500 DrvSelMd3ReqDnd "Driver Selected Mode 3 Request Denied";
BA_ "SignalType" SG_ 500 DrvSelMd3ReqDnd "BLN";
BA_ "VNSigAllNodes" SG_ 500 DrvSelMd2Stat 1;
BA_ "GenSigSendType" SG_ 500 DrvSelMd2Stat 10;
BA_ "SignalLongName" SG_ 500 DrvSelMd2Stat "Driver Selected Mode 2 Status";
BA_ "SignalType" SG_ 500 DrvSelMd2Stat "ENM";
BA_ "VNSigAllNodes" SG_ 500 DrvSelMd2ReqDnd 1;
BA_ "GenSigSendType" SG_ 500 DrvSelMd2ReqDnd 10;
BA_ "SignalLongName" SG_ 500 DrvSelMd2ReqDnd "Driver Selected Mode 2 Request Denied";
BA_ "SignalType" SG_ 500 DrvSelMd2ReqDnd "BLN";
BA_ "VNSigAllNodes" SG_ 500 DSMSS_DrvSelMd0Pn 1;
BA_ "PacketOrder" SG_ 500 DSMSS_DrvSelMd0Pn 17;
BA_ "GenSigSendType" SG_ 500 DSMSS_DrvSelMd0Pn 10;
BA_ "SignalLongName" SG_ 500 DSMSS_DrvSelMd0Pn "Driver Selected Mode Selection Status : Driver Selected Mode 0 Pending";
BA_ "SignalType" SG_ 500 DSMSS_DrvSelMd0Pn "BLN";
BA_ "VNSigAllNodes" SG_ 500 DSMSS_DrvSelMd8Pn 1;
BA_ "PacketOrder" SG_ 500 DSMSS_DrvSelMd8Pn 16;
BA_ "GenSigSendType" SG_ 500 DSMSS_DrvSelMd8Pn 10;
BA_ "SignalLongName" SG_ 500 DSMSS_DrvSelMd8Pn "Driver Selected Mode Selection Status : Driver Selected Mode 8 Pending";
BA_ "SignalType" SG_ 500 DSMSS_DrvSelMd8Pn "BLN";
BA_ "VNSigAllNodes" SG_ 500 DSMSS_DrvSelMd7Pn 1;
BA_ "PacketOrder" SG_ 500 DSMSS_DrvSelMd7Pn 15;
BA_ "GenSigSendType" SG_ 500 DSMSS_DrvSelMd7Pn 10;
BA_ "SignalLongName" SG_ 500 DSMSS_DrvSelMd7Pn "Driver Selected Mode Selection Status : Driver Selected Mode 7 Pending";
BA_ "SignalType" SG_ 500 DSMSS_DrvSelMd7Pn "BLN";
BA_ "VNSigAllNodes" SG_ 500 DSMSS_DrvSelMd6Pn 1;
BA_ "PacketOrder" SG_ 500 DSMSS_DrvSelMd6Pn 14;
BA_ "GenSigSendType" SG_ 500 DSMSS_DrvSelMd6Pn 10;
BA_ "SignalLongName" SG_ 500 DSMSS_DrvSelMd6Pn "Driver Selected Mode Selection Status : Driver Selected Mode 6 Pending";
BA_ "SignalType" SG_ 500 DSMSS_DrvSelMd6Pn "BLN";
BA_ "VNSigAllNodes" SG_ 500 DSMSS_DrvSelMd5Pn 1;
BA_ "PacketOrder" SG_ 500 DSMSS_DrvSelMd5Pn 13;
BA_ "GenSigSendType" SG_ 500 DSMSS_DrvSelMd5Pn 10;
BA_ "SignalLongName" SG_ 500 DSMSS_DrvSelMd5Pn "Driver Selected Mode Selection Status : Driver Selected Mode 5 Pending";
BA_ "SignalType" SG_ 500 DSMSS_DrvSelMd5Pn "BLN";
BA_ "VNSigAllNodes" SG_ 500 DSMSS_DrvSelMd4Pn 1;
BA_ "PacketOrder" SG_ 500 DSMSS_DrvSelMd4Pn 12;
BA_ "GenSigSendType" SG_ 500 DSMSS_DrvSelMd4Pn 10;
BA_ "SignalLongName" SG_ 500 DSMSS_DrvSelMd4Pn "Driver Selected Mode Selection Status : Driver Selected Mode 4 Pending";
BA_ "SignalType" SG_ 500 DSMSS_DrvSelMd4Pn "BLN";
BA_ "VNSigAllNodes" SG_ 500 DSMSS_DrvSelMd3Pn 1;
BA_ "PacketOrder" SG_ 500 DSMSS_DrvSelMd3Pn 11;
BA_ "GenSigSendType" SG_ 500 DSMSS_DrvSelMd3Pn 10;
BA_ "SignalLongName" SG_ 500 DSMSS_DrvSelMd3Pn "Driver Selected Mode Selection Status : Driver Selected Mode 3 Pending";
BA_ "SignalType" SG_ 500 DSMSS_DrvSelMd3Pn "BLN";
BA_ "VNSigAllNodes" SG_ 500 DSMSS_DrvSelMd2Pn 1;
BA_ "PacketOrder" SG_ 500 DSMSS_DrvSelMd2Pn 10;
BA_ "GenSigSendType" SG_ 500 DSMSS_DrvSelMd2Pn 10;
BA_ "SignalLongName" SG_ 500 DSMSS_DrvSelMd2Pn "Driver Selected Mode Selection Status : Driver Selected Mode 2 Pending";
BA_ "SignalType" SG_ 500 DSMSS_DrvSelMd2Pn "BLN";
BA_ "VNSigAllNodes" SG_ 500 DSMSS_DrvSelMd1Pn 1;
BA_ "PacketOrder" SG_ 500 DSMSS_DrvSelMd1Pn 9;
BA_ "GenSigSendType" SG_ 500 DSMSS_DrvSelMd1Pn 10;
BA_ "SignalLongName" SG_ 500 DSMSS_DrvSelMd1Pn "Driver Selected Mode Selection Status : Driver Selected Mode 1 Pending";
BA_ "SignalType" SG_ 500 DSMSS_DrvSelMd1Pn "BLN";
BA_ "VNSigAllNodes" SG_ 500 DSMSS_DrvSelMd8Un 1;
BA_ "PacketOrder" SG_ 500 DSMSS_DrvSelMd8Un 8;
BA_ "GenSigSendType" SG_ 500 DSMSS_DrvSelMd8Un 10;
BA_ "SignalLongName" SG_ 500 DSMSS_DrvSelMd8Un "Driver Selected Mode Selection Status : Driver Selected Mode 8 Unavailable";
BA_ "SignalType" SG_ 500 DSMSS_DrvSelMd8Un "BLN";
BA_ "VNSigAllNodes" SG_ 500 DSMSS_DrvSelMd7Un 1;
BA_ "PacketOrder" SG_ 500 DSMSS_DrvSelMd7Un 7;
BA_ "GenSigSendType" SG_ 500 DSMSS_DrvSelMd7Un 10;
BA_ "SignalLongName" SG_ 500 DSMSS_DrvSelMd7Un "Driver Selected Mode Selection Status : Driver Selected Mode 7 Unavailable";
BA_ "SignalType" SG_ 500 DSMSS_DrvSelMd7Un "BLN";
BA_ "VNSigAllNodes" SG_ 500 DSMSS_DrvSelMd6Un 1;
BA_ "PacketOrder" SG_ 500 DSMSS_DrvSelMd6Un 6;
BA_ "GenSigSendType" SG_ 500 DSMSS_DrvSelMd6Un 10;
BA_ "SignalLongName" SG_ 500 DSMSS_DrvSelMd6Un "Driver Selected Mode Selection Status : Driver Selected Mode 6 Unavailable";
BA_ "SignalType" SG_ 500 DSMSS_DrvSelMd6Un "BLN";
BA_ "VNSigAllNodes" SG_ 500 DSMSS_DrvSelMd5Un 1;
BA_ "PacketOrder" SG_ 500 DSMSS_DrvSelMd5Un 5;
BA_ "GenSigSendType" SG_ 500 DSMSS_DrvSelMd5Un 10;
BA_ "SignalLongName" SG_ 500 DSMSS_DrvSelMd5Un "Driver Selected Mode Selection Status : Driver Selected Mode 5 Unavailable";
BA_ "SignalType" SG_ 500 DSMSS_DrvSelMd5Un "BLN";
BA_ "VNSigAllNodes" SG_ 500 DSMSS_DrvSelMd4Un 1;
BA_ "PacketOrder" SG_ 500 DSMSS_DrvSelMd4Un 4;
BA_ "GenSigSendType" SG_ 500 DSMSS_DrvSelMd4Un 10;
BA_ "SignalLongName" SG_ 500 DSMSS_DrvSelMd4Un "Driver Selected Mode Selection Status : Driver Selected Mode 4 Unavailable";
BA_ "SignalType" SG_ 500 DSMSS_DrvSelMd4Un "BLN";
BA_ "VNSigAllNodes" SG_ 500 DSMSS_DrvSelMd3Un 1;
BA_ "PacketOrder" SG_ 500 DSMSS_DrvSelMd3Un 3;
BA_ "GenSigSendType" SG_ 500 DSMSS_DrvSelMd3Un 10;
BA_ "SignalLongName" SG_ 500 DSMSS_DrvSelMd3Un "Driver Selected Mode Selection Status : Driver Selected Mode 3 Unavailable";
BA_ "SignalType" SG_ 500 DSMSS_DrvSelMd3Un "BLN";
BA_ "VNSigAllNodes" SG_ 500 DSMSS_DrvSelMd2Un 1;
BA_ "PacketOrder" SG_ 500 DSMSS_DrvSelMd2Un 2;
BA_ "GenSigSendType" SG_ 500 DSMSS_DrvSelMd2Un 10;
BA_ "SignalLongName" SG_ 500 DSMSS_DrvSelMd2Un "Driver Selected Mode Selection Status : Driver Selected Mode 2 Unavailable";
BA_ "SignalType" SG_ 500 DSMSS_DrvSelMd2Un "BLN";
BA_ "VNSigAllNodes" SG_ 500 DSMSS_DrvSelMd1Un 1;
BA_ "PacketOrder" SG_ 500 DSMSS_DrvSelMd1Un 1;
BA_ "GenSigSendType" SG_ 500 DSMSS_DrvSelMd1Un 10;
BA_ "SignalLongName" SG_ 500 DSMSS_DrvSelMd1Un "Driver Selected Mode Selection Status : Driver Selected Mode 1 Unavailable";
BA_ "SignalType" SG_ 500 DSMSS_DrvSelMd1Un "BLN";
BA_ "VNSigAllNodes" SG_ 500 DrvSelMd1ReqDnd 1;
BA_ "GenSigSendType" SG_ 500 DrvSelMd1ReqDnd 10;
BA_ "SignalLongName" SG_ 500 DrvSelMd1ReqDnd "Driver Selected Mode 1 Request Denied";
BA_ "SignalType" SG_ 500 DrvSelMd1ReqDnd "BLN";
BA_ "VNSigAllNodes" SG_ 500 DrvSelMd1Stat 1;
BA_ "GenSigSendType" SG_ 500 DrvSelMd1Stat 10;
BA_ "SignalLongName" SG_ 500 DrvSelMd1Stat "Driver Selected Mode 1 Status";
BA_ "SignalType" SG_ 500 DrvSelMd1Stat "ENM";
BA_ "Prio" BO_ 1417 0;
BA_ "GenMsgSendType" BO_ 1417 0;
BA_ "GenMsgCycleTime" BO_ 1417 500;
BA_ "MessageSubnet" BO_ 1417 2;
BA_ "VNSigAllNodes" SG_ 1417 PrplsnTrqRelCap 1;
BA_ "SignalLongName" SG_ 1417 PrplsnTrqRelCap "Propulsion Torque Relative Capability";
BA_ "SignalType" SG_ 1417 PrplsnTrqRelCap "UNM";
BA_ "VNSigAllNodes" SG_ 1417 ETC_MinTorq 1;
BA_ "PacketOrder" SG_ 1417 ETC_MinTorq 7;
BA_ "SignalLongName" SG_ 1417 ETC_MinTorq "Engine Torque Capability : Minimum Torque";
BA_ "SignalType" SG_ 1417 ETC_MinTorq "UNM";
BA_ "VNSigAllNodes" SG_ 1417 ETC_MinRunTorq 1;
BA_ "PacketOrder" SG_ 1417 ETC_MinRunTorq 6;
BA_ "SignalLongName" SG_ 1417 ETC_MinRunTorq "Engine Torque Capability : Minimum Run Torque";
BA_ "SignalType" SG_ 1417 ETC_MinRunTorq "UNM";
BA_ "VNSigAllNodes" SG_ 1417 ETC_MaxTorq 1;
BA_ "PacketOrder" SG_ 1417 ETC_MaxTorq 5;
BA_ "SignalLongName" SG_ 1417 ETC_MaxTorq "Engine Torque Capability : Maximum Torque";
BA_ "SignalType" SG_ 1417 ETC_MaxTorq "UNM";
BA_ "VNSigAllNodes" SG_ 1417 ETC_RefEngSpd 1;
BA_ "PacketOrder" SG_ 1417 ETC_RefEngSpd 4;
BA_ "SignalLongName" SG_ 1417 ETC_RefEngSpd "Engine Torque Capability : Reference Engine Speed";
BA_ "SignalType" SG_ 1417 ETC_RefEngSpd "UNM";
BA_ "VNSigAllNodes" SG_ 1417 ETC_UnsdRsrvd 1;
BA_ "PacketOrder" SG_ 1417 ETC_UnsdRsrvd 3;
BA_ "SignalLongName" SG_ 1417 ETC_UnsdRsrvd "Engine Torque Capability : Unused and Reserved";
BA_ "SignalType" SG_ 1417 ETC_UnsdRsrvd "UNM";
BA_ "VNSigAllNodes" SG_ 1417 ETC_FrmCntr 1;
BA_ "PacketOrder" SG_ 1417 ETC_FrmCntr 2;
BA_ "SignalLongName" SG_ 1417 ETC_FrmCntr "Engine Torque Capability : Frame Counter";
BA_ "SignalType" SG_ 1417 ETC_FrmCntr "UNM";
BA_ "VNSigAllNodes" SG_ 1417 ETC_EngOpMd 1;
BA_ "PacketOrder" SG_ 1417 ETC_EngOpMd 1;
BA_ "SignalLongName" SG_ 1417 ETC_EngOpMd "Engine Torque Capability : Engine Operating Mode";
BA_ "SignalType" SG_ 1417 ETC_EngOpMd "ENM";
BA_ "Prio" BO_ 407 0;
BA_ "GenMsgSendType" BO_ 407 0;
BA_ "GenMsgCycleTime" BO_ 407 25;
BA_ "MessageSubnet" BO_ 407 2;
BA_ "VNSigAllNodes" SG_ 407 TrnsOvrallActTorqRatioV 1;
BA_ "SignalLongName" SG_ 407 TrnsOvrallActTorqRatioV "Transmission Overall Actual Torque Ratio Validity";
BA_ "SignalType" SG_ 407 TrnsOvrallActTorqRatioV "ENM";
BA_ "VNSigAllNodes" SG_ 407 TrnsOvrallActTorqRatio 1;
BA_ "SignalLongName" SG_ 407 TrnsOvrallActTorqRatio "Transmission Overall Actual Torque Ratio";
BA_ "SignalType" SG_ 407 TrnsOvrallActTorqRatio "SNM";
BA_ "Prio" BO_ 189 0;
BA_ "GenMsgSendType" BO_ 189 0;
BA_ "GenMsgCycleTime" BO_ 189 25;
BA_ "MessageSubnet" BO_ 189 2;
BA_ "VNSigAllNodes" SG_ 189 TransVehTopSpdLim 1;
BA_ "SignalLongName" SG_ 189 TransVehTopSpdLim "Transmission Vehicle Top Speed Limit Value";
BA_ "SignalType" SG_ 189 TransVehTopSpdLim "UNM";
BA_ "VNSigAllNodes" SG_ 189 TransMinVoltReq 1;
BA_ "SignalLongName" SG_ 189 TransMinVoltReq "Transmission Minimum Voltage Request";
BA_ "SignalType" SG_ 189 TransMinVoltReq "UNM";
BA_ "VNSigAllNodes" SG_ 189 TrnsRtoCntlSysFlt 1;
BA_ "SignalLongName" SG_ 189 TrnsRtoCntlSysFlt "Transmission Ratio Control System Fault";
BA_ "SignalType" SG_ 189 TrnsRtoCntlSysFlt "BLN";
BA_ "VNSigAllNodes" SG_ 189 TransMnPressEstmd 1;
BA_ "SignalLongName" SG_ 189 TransMnPressEstmd "Transmission Main Pressure Estimated";
BA_ "SignalType" SG_ 189 TransMnPressEstmd "UNM";
BA_ "VNSigAllNodes" SG_ 189 TrnsInpMinSpdRq 1;
BA_ "SignalLongName" SG_ 189 TrnsInpMinSpdRq "Transmission Input Minimum Speed Request";
BA_ "SignalType" SG_ 189 TrnsInpMinSpdRq "ENM";
BA_ "VNSigAllNodes" SG_ 189 TrnsHydPrsDsrd 1;
BA_ "SignalLongName" SG_ 189 TrnsHydPrsDsrd "Transmission Hydraulic Pressure Desired";
BA_ "SignalType" SG_ 189 TrnsHydPrsDsrd "UNM";
BA_ "VNSigAllNodes" SG_ 189 TransAuxPumpSpdDsrd 1;
BA_ "SignalLongName" SG_ 189 TransAuxPumpSpdDsrd "Transmission Auxiliary Pump Speed Desired";
BA_ "SignalType" SG_ 189 TransAuxPumpSpdDsrd "UNM";
BA_ "Prio" BO_ 187 0;
BA_ "GenMsgSendType" BO_ 187 0;
BA_ "GenMsgCycleTime" BO_ 187 25;
BA_ "MessageSubnet" BO_ 187 2;
BA_ "VNSigAllNodes" SG_ 187 TransClch5_TorqCmnd 1;
BA_ "SignalLongName" SG_ 187 TransClch5_TorqCmnd "Transmission Clutch 5 Torque Command";
BA_ "SignalType" SG_ 187 TransClch5_TorqCmnd "UNM";
BA_ "VNSigAllNodes" SG_ 187 TransCltch5MinPrsRq 1;
BA_ "SignalLongName" SG_ 187 TransCltch5MinPrsRq "Transmission Clutch 5 Minimum Pressure Required";
BA_ "SignalType" SG_ 187 TransCltch5MinPrsRq "UNM";
BA_ "VNSigAllNodes" SG_ 187 TransCltch5FillCmd 1;
BA_ "SignalLongName" SG_ 187 TransCltch5FillCmd "Transmission Clutch 5 Fill Commanded";
BA_ "SignalType" SG_ 187 TransCltch5FillCmd "ENM";
BA_ "VNSigAllNodes" SG_ 187 TransClch4_TorqCmnd 1;
BA_ "SignalLongName" SG_ 187 TransClch4_TorqCmnd "Transmission Clutch 4 Torque Command";
BA_ "SignalType" SG_ 187 TransClch4_TorqCmnd "UNM";
BA_ "VNSigAllNodes" SG_ 187 TransCltch4MinPrsRq 1;
BA_ "SignalLongName" SG_ 187 TransCltch4MinPrsRq "Transmission Clutch 4 Minimum Pressure Required";
BA_ "SignalType" SG_ 187 TransCltch4MinPrsRq "UNM";
BA_ "VNSigAllNodes" SG_ 187 TransCltch4FillCmd 1;
BA_ "SignalLongName" SG_ 187 TransCltch4FillCmd "Transmission Clutch 4 Fill Commanded";
BA_ "SignalType" SG_ 187 TransCltch4FillCmd "ENM";
BA_ "Prio" BO_ 185 0;
BA_ "GenMsgSendType" BO_ 185 0;
BA_ "GenMsgCycleTime" BO_ 185 25;
BA_ "MessageSubnet" BO_ 185 2;
BA_ "VNSigAllNodes" SG_ 185 TransCltch1FillCmd 1;
BA_ "SignalLongName" SG_ 185 TransCltch1FillCmd "Transmission Clutch 1 Fill Commanded";
BA_ "SignalType" SG_ 185 TransCltch1FillCmd "ENM";
BA_ "VNSigAllNodes" SG_ 185 TransCltch1CntlRqPVal 1;
BA_ "SignalLongName" SG_ 185 TransCltch1CntlRqPVal "Transmission Clutch 1 Control Requested Protection Value";
BA_ "SignalType" SG_ 185 TransCltch1CntlRqPVal "UNM";
BA_ "VNSigAllNodes" SG_ 185 TransCltch1CntlRq 1;
BA_ "SignalLongName" SG_ 185 TransCltch1CntlRq "Transmission Clutch 1 Control Requested";
BA_ "SignalType" SG_ 185 TransCltch1CntlRq "ENM";
BA_ "VNSigAllNodes" SG_ 185 MtrBCoolFlwCmd 1;
BA_ "SignalLongName" SG_ 185 MtrBCoolFlwCmd "Motor B Cooling Flow Command";
BA_ "SignalType" SG_ 185 MtrBCoolFlwCmd "UNM";
BA_ "VNSigAllNodes" SG_ 185 MtrACoolFlwCmd 1;
BA_ "SignalLongName" SG_ 185 MtrACoolFlwCmd "Motor A Cooling Flow Command";
BA_ "SignalType" SG_ 185 MtrACoolFlwCmd "UNM";
BA_ "VNSigAllNodes" SG_ 185 TransCltchCntlARC 1;
BA_ "SignalLongName" SG_ 185 TransCltchCntlARC "Transmission Clutch Control Alive Rolling Count";
BA_ "SignalType" SG_ 185 TransCltchCntlARC "UNM";
BA_ "VNSigAllNodes" SG_ 185 TransCltch5CntlRqPVal 1;
BA_ "SignalLongName" SG_ 185 TransCltch5CntlRqPVal "Transmission Clutch 5 Control Requested Protection Value";
BA_ "SignalType" SG_ 185 TransCltch5CntlRqPVal "UNM";
BA_ "VNSigAllNodes" SG_ 185 TransCltch5CntlRq 1;
BA_ "SignalLongName" SG_ 185 TransCltch5CntlRq "Transmission Clutch 5 Control Requested";
BA_ "SignalType" SG_ 185 TransCltch5CntlRq "ENM";
BA_ "VNSigAllNodes" SG_ 185 TransCltch4CntlRqPVal 1;
BA_ "SignalLongName" SG_ 185 TransCltch4CntlRqPVal "Transmission Clutch 4 Control Requested Protection Value";
BA_ "SignalType" SG_ 185 TransCltch4CntlRqPVal "UNM";
BA_ "VNSigAllNodes" SG_ 185 TransCltch4CntlRq 1;
BA_ "SignalLongName" SG_ 185 TransCltch4CntlRq "Transmission Clutch 4 Control Requested";
BA_ "SignalType" SG_ 185 TransCltch4CntlRq "ENM";
BA_ "VNSigAllNodes" SG_ 185 TransCltch3CntlRqPVal 1;
BA_ "SignalLongName" SG_ 185 TransCltch3CntlRqPVal "Transmission Clutch 3 Control Requested Protection Value";
BA_ "SignalType" SG_ 185 TransCltch3CntlRqPVal "UNM";
BA_ "VNSigAllNodes" SG_ 185 TransCltch3CntlRq 1;
BA_ "SignalLongName" SG_ 185 TransCltch3CntlRq "Transmission Clutch 3 Control Requested";
BA_ "SignalType" SG_ 185 TransCltch3CntlRq "ENM";
BA_ "VNSigAllNodes" SG_ 185 TransCltch2CntlRqPVal 1;
BA_ "SignalLongName" SG_ 185 TransCltch2CntlRqPVal "Transmission Clutch 2 Control Requested Protection Value";
BA_ "SignalType" SG_ 185 TransCltch2CntlRqPVal "UNM";
BA_ "VNSigAllNodes" SG_ 185 TransCltch2CntlRq 1;
BA_ "SignalLongName" SG_ 185 TransCltch2CntlRq "Transmission Clutch 2 Control Requested";
BA_ "SignalType" SG_ 185 TransCltch2CntlRq "ENM";
BA_ "VNSigAllNodes" SG_ 185 TransClch1_TorqCmnd 1;
BA_ "SignalLongName" SG_ 185 TransClch1_TorqCmnd "Transmission Clutch 1 Torque Command";
BA_ "SignalType" SG_ 185 TransClch1_TorqCmnd "UNM";
BA_ "VNSigAllNodes" SG_ 185 TransCltch1MinPrsRq 1;
BA_ "SignalLongName" SG_ 185 TransCltch1MinPrsRq "Transmission Clutch 1 Minimum Pressure Required";
BA_ "SignalType" SG_ 185 TransCltch1MinPrsRq "UNM";
BA_ "Prio" BO_ 186 0;
BA_ "GenMsgSendType" BO_ 186 0;
BA_ "GenMsgCycleTime" BO_ 186 25;
BA_ "MessageSubnet" BO_ 186 2;
BA_ "VNSigAllNodes" SG_ 186 TransClch3_TorqCmnd 1;
BA_ "SignalLongName" SG_ 186 TransClch3_TorqCmnd "Transmission Clutch 3 Torque Command";
BA_ "SignalType" SG_ 186 TransClch3_TorqCmnd "UNM";
BA_ "VNSigAllNodes" SG_ 186 TransCltch3MinPrsRq 1;
BA_ "SignalLongName" SG_ 186 TransCltch3MinPrsRq "Transmission Clutch 3 Minimum Pressure Required";
BA_ "SignalType" SG_ 186 TransCltch3MinPrsRq "UNM";
BA_ "VNSigAllNodes" SG_ 186 TransCltch3FillCmd 1;
BA_ "SignalLongName" SG_ 186 TransCltch3FillCmd "Transmission Clutch 3 Fill Commanded";
BA_ "SignalType" SG_ 186 TransCltch3FillCmd "ENM";
BA_ "VNSigAllNodes" SG_ 186 TransClch2_TorqCmnd 1;
BA_ "SignalLongName" SG_ 186 TransClch2_TorqCmnd "Transmission Clutch 2 Torque Command";
BA_ "SignalType" SG_ 186 TransClch2_TorqCmnd "UNM";
BA_ "VNSigAllNodes" SG_ 186 TransCltch2MinPrsRq 1;
BA_ "SignalLongName" SG_ 186 TransCltch2MinPrsRq "Transmission Clutch 2 Minimum Pressure Required";
BA_ "SignalType" SG_ 186 TransCltch2MinPrsRq "UNM";
BA_ "VNSigAllNodes" SG_ 186 TransCltch2FillCmd 1;
BA_ "SignalLongName" SG_ 186 TransCltch2FillCmd "Transmission Clutch 2 Fill Commanded";
BA_ "SignalType" SG_ 186 TransCltch2FillCmd "ENM";
BA_ "Prio" BO_ 152 0;
BA_ "GenMsgSendType" BO_ 152 0;
BA_ "GenMsgCycleTime" BO_ 152 12;
BA_ "MessageSubnet" BO_ 152 2;
BA_ "VNSigAllNodes" SG_ 152 TransClch5MaxEngy 1;
BA_ "SignalLongName" SG_ 152 TransClch5MaxEngy "Transmission Clutch 5 Maximum Energy";
BA_ "SignalType" SG_ 152 TransClch5MaxEngy "UNM";
BA_ "VNSigAllNodes" SG_ 152 TransClch5FlTm 1;
BA_ "SignalLongName" SG_ 152 TransClch5FlTm "Transmission Clutch 5 Fill Time";
BA_ "SignalType" SG_ 152 TransClch5FlTm "UNM";
BA_ "VNSigAllNodes" SG_ 152 TransClch5FlAch 1;
BA_ "SignalLongName" SG_ 152 TransClch5FlAch "Transmission Clutch 5 Fill Achieved";
BA_ "SignalType" SG_ 152 TransClch5FlAch "BLN";
BA_ "VNSigAllNodes" SG_ 152 TransCltch5EstTrq 1;
BA_ "SignalLongName" SG_ 152 TransCltch5EstTrq "Transmission Clutch 5 Estimated Torque";
BA_ "SignalType" SG_ 152 TransCltch5EstTrq "UNM";
BA_ "VNSigAllNodes" SG_ 152 TransClch5_Avail 1;
BA_ "SignalLongName" SG_ 152 TransClch5_Avail "Transmission Clutch 5 Available";
BA_ "SignalType" SG_ 152 TransClch5_Avail "BLN";
BA_ "VNSigAllNodes" SG_ 152 TransClch4FlTm 1;
BA_ "SignalLongName" SG_ 152 TransClch4FlTm "Transmission Clutch 4 Fill Time";
BA_ "SignalType" SG_ 152 TransClch4FlTm "UNM";
BA_ "VNSigAllNodes" SG_ 152 TransClch4EstTorq 1;
BA_ "SignalLongName" SG_ 152 TransClch4EstTorq "Transmission Clutch 4 Estimated Torque";
BA_ "SignalType" SG_ 152 TransClch4EstTorq "UNM";
BA_ "VNSigAllNodes" SG_ 152 TransClch4MaxEnrgy 1;
BA_ "SignalLongName" SG_ 152 TransClch4MaxEnrgy "Transmission Clutch 4 Maximum Energy";
BA_ "SignalType" SG_ 152 TransClch4MaxEnrgy "UNM";
BA_ "VNSigAllNodes" SG_ 152 TransClch4FlAch 1;
BA_ "SignalLongName" SG_ 152 TransClch4FlAch "Transmission Clutch 4 Fill Achieved";
BA_ "SignalType" SG_ 152 TransClch4FlAch "BLN";
BA_ "VNSigAllNodes" SG_ 152 TransClch4_Avail 1;
BA_ "SignalLongName" SG_ 152 TransClch4_Avail "Transmission Clutch 4 Available";
BA_ "SignalType" SG_ 152 TransClch4_Avail "BLN";
BA_ "Prio" BO_ 151 0;
BA_ "GenMsgSendType" BO_ 151 0;
BA_ "GenMsgCycleTime" BO_ 151 12;
BA_ "MessageSubnet" BO_ 151 2;
BA_ "VNSigAllNodes" SG_ 151 TransClch3FlTm 1;
BA_ "SignalLongName" SG_ 151 TransClch3FlTm "Transmission Clutch 3 Fill Time";
BA_ "SignalType" SG_ 151 TransClch3FlTm "UNM";
BA_ "VNSigAllNodes" SG_ 151 TransClch3EstTorq 1;
BA_ "SignalLongName" SG_ 151 TransClch3EstTorq "Transmission Clutch 3 Estimated Torque";
BA_ "SignalType" SG_ 151 TransClch3EstTorq "UNM";
BA_ "VNSigAllNodes" SG_ 151 TransClch3MaxEnrgy 1;
BA_ "SignalLongName" SG_ 151 TransClch3MaxEnrgy "Transmission Clutch 3 Maximum Energy";
BA_ "SignalType" SG_ 151 TransClch3MaxEnrgy "UNM";
BA_ "VNSigAllNodes" SG_ 151 TransClch3FlAch 1;
BA_ "SignalLongName" SG_ 151 TransClch3FlAch "Transmission Clutch 3 Fill Achieved";
BA_ "SignalType" SG_ 151 TransClch3FlAch "BLN";
BA_ "VNSigAllNodes" SG_ 151 TransClch3_Avail 1;
BA_ "SignalLongName" SG_ 151 TransClch3_Avail "Transmission Clutch 3 Available";
BA_ "SignalType" SG_ 151 TransClch3_Avail "BLN";
BA_ "VNSigAllNodes" SG_ 151 TransClch2FlTm 1;
BA_ "SignalLongName" SG_ 151 TransClch2FlTm "Transmission Clutch 2 Fill Time";
BA_ "SignalType" SG_ 151 TransClch2FlTm "UNM";
BA_ "VNSigAllNodes" SG_ 151 TransClch2EstTorq 1;
BA_ "SignalLongName" SG_ 151 TransClch2EstTorq "Transmission Clutch 2 Estimated Torque";
BA_ "SignalType" SG_ 151 TransClch2EstTorq "UNM";
BA_ "VNSigAllNodes" SG_ 151 TransClch2MaxEnrgy 1;
BA_ "SignalLongName" SG_ 151 TransClch2MaxEnrgy "Transmission Clutch 2 Maximum Energy";
BA_ "SignalType" SG_ 151 TransClch2MaxEnrgy "UNM";
BA_ "VNSigAllNodes" SG_ 151 TransClch2FlAch 1;
BA_ "SignalLongName" SG_ 151 TransClch2FlAch "Transmission Clutch 2 Fill Achieved";
BA_ "SignalType" SG_ 151 TransClch2FlAch "BLN";
BA_ "VNSigAllNodes" SG_ 151 TransClch2_Avail 1;
BA_ "SignalLongName" SG_ 151 TransClch2_Avail "Transmission Clutch 2 Available";
BA_ "SignalType" SG_ 151 TransClch2_Avail "BLN";
BA_ "Prio" BO_ 150 0;
BA_ "GenMsgSendType" BO_ 150 0;
BA_ "GenMsgCycleTime" BO_ 150 12;
BA_ "MessageSubnet" BO_ 150 2;
BA_ "VNSigAllNodes" SG_ 150 TrnsInpDvcStat 1;
BA_ "SignalLongName" SG_ 150 TrnsInpDvcStat "Transmission Input Device Status";
BA_ "SignalType" SG_ 150 TrnsInpDvcStat "ENM";
BA_ "VNSigAllNodes" SG_ 150 TransInhibitNeut 1;
BA_ "SignalLongName" SG_ 150 TransInhibitNeut "Transmission Default Action Inhibit Neutral";
BA_ "SignalType" SG_ 150 TransInhibitNeut "BLN";
BA_ "VNSigAllNodes" SG_ 150 TransInhibitMode2 1;
BA_ "SignalLongName" SG_ 150 TransInhibitMode2 "Transmission Default Action Inhibit Mode 2";
BA_ "SignalType" SG_ 150 TransInhibitMode2 "BLN";
BA_ "VNSigAllNodes" SG_ 150 TransInhibitMode1 1;
BA_ "SignalLongName" SG_ 150 TransInhibitMode1 "Transmission Default Action Inhibit Mode 1";
BA_ "SignalType" SG_ 150 TransInhibitMode1 "BLN";
BA_ "VNSigAllNodes" SG_ 150 TransInhibitGear4 1;
BA_ "SignalLongName" SG_ 150 TransInhibitGear4 "Transmission Default Action Inhibit Gear 4";
BA_ "SignalType" SG_ 150 TransInhibitGear4 "BLN";
BA_ "VNSigAllNodes" SG_ 150 TransInhibitGear3 1;
BA_ "SignalLongName" SG_ 150 TransInhibitGear3 "Transmission Default Action Inhibit Gear 3";
BA_ "SignalType" SG_ 150 TransInhibitGear3 "BLN";
BA_ "VNSigAllNodes" SG_ 150 TransInhibitGear2 1;
BA_ "SignalLongName" SG_ 150 TransInhibitGear2 "Transmission Default Action Inhibit Gear 2";
BA_ "SignalType" SG_ 150 TransInhibitGear2 "BLN";
BA_ "VNSigAllNodes" SG_ 150 TransInhibitGear1 1;
BA_ "SignalLongName" SG_ 150 TransInhibitGear1 "Transmission Default Action Inhibit Gear 1";
BA_ "SignalType" SG_ 150 TransInhibitGear1 "BLN";
BA_ "VNSigAllNodes" SG_ 150 TrnsPTSysShtdwnRq 1;
BA_ "SignalLongName" SG_ 150 TrnsPTSysShtdwnRq "Transmission Powertrain System Shutdown Requested";
BA_ "SignalType" SG_ 150 TrnsPTSysShtdwnRq "BLN";
BA_ "VNSigAllNodes" SG_ 150 TransClch1FlTm 1;
BA_ "SignalLongName" SG_ 150 TransClch1FlTm "Transmission Clutch 1 Fill Time";
BA_ "SignalType" SG_ 150 TransClch1FlTm "UNM";
BA_ "VNSigAllNodes" SG_ 150 TransClch1EstTorq 1;
BA_ "SignalLongName" SG_ 150 TransClch1EstTorq "Transmission Clutch 1 Estimated Torque";
BA_ "SignalType" SG_ 150 TransClch1EstTorq "UNM";
BA_ "VNSigAllNodes" SG_ 150 TransClch1MaxEnrgy 1;
BA_ "SignalLongName" SG_ 150 TransClch1MaxEnrgy "Transmission Clutch 1 Maximum Energy";
BA_ "SignalType" SG_ 150 TransClch1MaxEnrgy "UNM";
BA_ "VNSigAllNodes" SG_ 150 TransClch1FlAch 1;
BA_ "SignalLongName" SG_ 150 TransClch1FlAch "Transmission Clutch 1 Fill Achieved";
BA_ "SignalType" SG_ 150 TransClch1FlAch "BLN";
BA_ "VNSigAllNodes" SG_ 150 TransClch1_Avail 1;
BA_ "SignalLongName" SG_ 150 TransClch1_Avail "Transmission Clutch 1 Available";
BA_ "SignalType" SG_ 150 TransClch1_Avail "BLN";
BA_ "Prio" BO_ 188 0;
BA_ "GenMsgSendType" BO_ 188 0;
BA_ "GenMsgCycleTime" BO_ 188 12;
BA_ "MessageSubnet" BO_ 188 2;
BA_ "VNSigAllNodes" SG_ 188 HybTrnsLubeFlwRqd 1;
BA_ "SignalLongName" SG_ 188 HybTrnsLubeFlwRqd "Hybrid Transmission Lube Flow Requested";
BA_ "SignalType" SG_ 188 HybTrnsLubeFlwRqd "UNM";
BA_ "VNSigAllNodes" SG_ 188 MtrBSpd 1;
BA_ "SignalLongName" SG_ 188 MtrBSpd "Motor B Speed";
BA_ "SignalType" SG_ 188 MtrBSpd "SNM";
BA_ "VNSigAllNodes" SG_ 188 MtrASpd 1;
BA_ "SignalLongName" SG_ 188 MtrASpd "Motor A Speed";
BA_ "SignalType" SG_ 188 MtrASpd "SNM";
BA_ "VNSigAllNodes" SG_ 188 HybTransStCmmnd 1;
BA_ "SignalLongName" SG_ 188 HybTransStCmmnd "Hybrid Transmission State Commanded";
BA_ "SignalType" SG_ 188 HybTransStCmmnd "ENM";
BA_ "VNSigAllNodes" SG_ 188 HybTransStAchvd 1;
BA_ "SignalLongName" SG_ 188 HybTransStAchvd "Hybrid Transmission State Achieved";
BA_ "SignalType" SG_ 188 HybTransStAchvd "ENM";
BA_ "VNSigAllNodes" SG_ 188 TransFldPmpCmd 1;
BA_ "SignalLongName" SG_ 188 TransFldPmpCmd "Transmission Fluid Pump Command";
BA_ "SignalType" SG_ 188 TransFldPmpCmd "ENM";
BA_ "VNSigAllNodes" SG_ 188 TransDirctnStV 1;
BA_ "SignalLongName" SG_ 188 TransDirctnStV "Transmission Direction State Validity";
BA_ "SignalType" SG_ 188 TransDirctnStV "ENM";
BA_ "VNSigAllNodes" SG_ 188 TransDirctnSt 1;
BA_ "SignalLongName" SG_ 188 TransDirctnSt "Transmission Direction State";
BA_ "SignalType" SG_ 188 TransDirctnSt "ENM";
BA_ "VNSigAllNodes" SG_ 188 TnsClchFlLnePrsBstRq 1;
BA_ "SignalLongName" SG_ 188 TnsClchFlLnePrsBstRq "Transmission Clutch Fill Line Pressure Boost Requested";
BA_ "SignalType" SG_ 188 TnsClchFlLnePrsBstRq "BLN";
BA_ "VNSigAllNodes" SG_ 188 TransAuxPumpSpd 1;
BA_ "SignalLongName" SG_ 188 TransAuxPumpSpd "Transmission Auxiliary Pump Speed";
BA_ "SignalType" SG_ 188 TransAuxPumpSpd "UNM";
BA_ "VNSigAllNodes" SG_ 188 TransAuxPumpAvail 1;
BA_ "SignalLongName" SG_ 188 TransAuxPumpAvail "Transmission Auxiliary Pump Available";
BA_ "SignalType" SG_ 188 TransAuxPumpAvail "BLN";
BA_ "VNSigAllNodes" SG_ 188 MtrBSpdV 1;
BA_ "SignalLongName" SG_ 188 MtrBSpdV "Motor B Speed Validity";
BA_ "SignalType" SG_ 188 MtrBSpdV "ENM";
BA_ "VNSigAllNodes" SG_ 188 MtrASpdV 1;
BA_ "SignalLongName" SG_ 188 MtrASpdV "Motor A Speed Validity";
BA_ "SignalType" SG_ 188 MtrASpdV "ENM";
BA_ "Prio" BO_ 170 0;
BA_ "GenMsgSendType" BO_ 170 0;
BA_ "GenMsgCycleTime" BO_ 170 12;
BA_ "MessageSubnet" BO_ 170 2;
BA_ "VNSigAllNodes" SG_ 170 EngCommFlrRedPwrCm 1;
BA_ "SignalLongName" SG_ 170 EngCommFlrRedPwrCm "Engine Communication Failure Reduced Power Commanded";
BA_ "SignalType" SG_ 170 EngCommFlrRedPwrCm "BLN";
BA_ "VNSigAllNodes" SG_ 170 CmndAxlTrqARC 1;
BA_ "SignalLongName" SG_ 170 CmndAxlTrqARC "Commanded Axle Torque Alive Rolling Count";
BA_ "SignalType" SG_ 170 CmndAxlTrqARC "UNM";
BA_ "VNSigAllNodes" SG_ 170 CmndAxlTrqRespTyp 1;
BA_ "SignalLongName" SG_ 170 CmndAxlTrqRespTyp "Commanded Axle Torque Response Type";
BA_ "SignalType" SG_ 170 CmndAxlTrqRespTyp "ENM";
BA_ "VNSigAllNodes" SG_ 170 CmndAxlTrqImm 1;
BA_ "SignalLongName" SG_ 170 CmndAxlTrqImm "Commanded Axle Torque Immediate";
BA_ "SignalType" SG_ 170 CmndAxlTrqImm "UNM";
BA_ "VNSigAllNodes" SG_ 170 AccPos 1;
BA_ "SignalLongName" SG_ 170 AccPos "Accelerator Effective Position";
BA_ "SignalType" SG_ 170 AccPos "UNM";
BA_ "VNSigAllNodes" SG_ 170 CmndAxlTrqPredct 1;
BA_ "SignalLongName" SG_ 170 CmndAxlTrqPredct "Commanded Axle Torque Predicted";
BA_ "SignalType" SG_ 170 CmndAxlTrqPredct "UNM";
BA_ "VNSigAllNodes" SG_ 170 CmndAxlTrqPredctProtVal 1;
BA_ "SignalLongName" SG_ 170 CmndAxlTrqPredctProtVal "Commanded Axle Torque Predicted Protection Value";
BA_ "SignalType" SG_ 170 CmndAxlTrqPredctProtVal "UNM";
BA_ "Prio" BO_ 1221 0;
BA_ "GenMsgSendType" BO_ 1221 0;
BA_ "GenMsgCycleTime" BO_ 1221 500;
BA_ "MessageSubnet" BO_ 1221 2;
BA_ "VNSigAllNodes" SG_ 1221 SpdLmtVsnFsdSpdUnt 1;
BA_ "SignalLongName" SG_ 1221 SpdLmtVsnFsdSpdUnt "Speed Limit Vision Fused Speed Unit";
BA_ "SignalType" SG_ 1221 SpdLmtVsnFsdSpdUnt "ENM";
BA_ "VNSigAllNodes" SG_ 1221 SpdLmtVnFsSpdNwDet 1;
BA_ "SignalLongName" SG_ 1221 SpdLmtVnFsSpdNwDet "Speed Limit Vision Fused Speed New Detected";
BA_ "SignalType" SG_ 1221 SpdLmtVnFsSpdNwDet "BLN";
BA_ "VNSigAllNodes" SG_ 1221 SpdLmtVsnFsdSpdM 1;
BA_ "SignalLongName" SG_ 1221 SpdLmtVsnFsdSpdM "Speed Limit Vision Fused Speed Mask";
BA_ "SignalType" SG_ 1221 SpdLmtVsnFsdSpdM "ENM";
BA_ "VNSigAllNodes" SG_ 1221 SpdLmtVsnFsdSpd 1;
BA_ "SignalLongName" SG_ 1221 SpdLmtVsnFsdSpd "Speed Limit Vision Fused Speed";
BA_ "SignalType" SG_ 1221 SpdLmtVsnFsdSpd "UNM";
BA_ "VNSigAllNodes" SG_ 1221 CCClntCrcFlwRtReq 1;
BA_ "SignalLongName" SG_ 1221 CCClntCrcFlwRtReq "Climate Control Coolant Circulation Flow Rate Request";
BA_ "SignalType" SG_ 1221 CCClntCrcFlwRtReq "UNM";
BA_ "VNSigAllNodes" SG_ 1221 PFFanSpdPrcntRq 1;
BA_ "SignalLongName" SG_ 1221 PFFanSpdPrcntRq "Platform Fan Speed Percent Request";
BA_ "SignalType" SG_ 1221 PFFanSpdPrcntRq "UNM";
BA_ "Prio" BO_ 1243 0;
BA_ "GenMsgSendType" BO_ 1243 0;
BA_ "GenMsgCycleTime" BO_ 1243 500;
BA_ "MessageSubnet" BO_ 1243 2;
BA_ "VNSigAllNodes" SG_ 1243 CSERDTC_CdNum 1;
BA_ "SignalLongName" SG_ 1243 CSERDTC_CdNum "Chassis System Emissions Related DTC : Code Number";
BA_ "SignalType" SG_ 1243 CSERDTC_CdNum "UNM";
BA_ "VNSigAllNodes" SG_ 1243 CSERDTC_SysDes 1;
BA_ "PacketOrder" SG_ 1243 CSERDTC_SysDes 1;
BA_ "SignalLongName" SG_ 1243 CSERDTC_SysDes "Chassis System Emissions Related DTC : System Designator";
BA_ "SignalType" SG_ 1243 CSERDTC_SysDes "ENM";
BA_ "VNSigAllNodes" SG_ 1243 ChsSysEmmRelMalfAct 1;
BA_ "SignalLongName" SG_ 1243 ChsSysEmmRelMalfAct "Chassis System Emissions Related Malfunction Active";
BA_ "SignalType" SG_ 1243 ChsSysEmmRelMalfAct "BLN";
BA_ "Prio" BO_ 979 0;
BA_ "GenMsgSendType" BO_ 979 0;
BA_ "GenMsgCycleTime" BO_ 979 100;
BA_ "MessageSubnet" BO_ 979 2;
BA_ "VNSigAllNodes" SG_ 979 PTABR_AccReq 1;
BA_ "PacketOrder" SG_ 979 PTABR_AccReq 2;
BA_ "SignalLongName" SG_ 979 PTABR_AccReq "Powertrain Automatic Braking Request : Acceleration Request";
BA_ "SignalType" SG_ 979 PTABR_AccReq "SNM";
BA_ "VNSigAllNodes" SG_ 979 PTABR_PTBrkRqAct 1;
BA_ "PacketOrder" SG_ 979 PTABR_PTBrkRqAct 1;
BA_ "SignalLongName" SG_ 979 PTABR_PTBrkRqAct "Powertrain Automatic Braking Request : Powertrain Brake Request Active";
BA_ "SignalType" SG_ 979 PTABR_PTBrkRqAct "BLN";
BA_ "VNSigAllNodes" SG_ 979 PTAutoBrkReqPVal 1;
BA_ "SignalLongName" SG_ 979 PTAutoBrkReqPVal "Powertrain Automatic Braking Request Protection Value";
BA_ "SignalType" SG_ 979 PTAutoBrkReqPVal "UNM";
BA_ "VNSigAllNodes" SG_ 979 PTAutoBrkReqARC 1;
BA_ "SignalLongName" SG_ 979 PTAutoBrkReqARC "Powertrain Automatic Braking Request Alive Rolling Count";
BA_ "SignalType" SG_ 979 PTAutoBrkReqARC "UNM";
BA_ "VNSigAllNodes" SG_ 979 BrkBstVacV 1;
BA_ "SignalLongName" SG_ 979 BrkBstVacV "Brake Boost Vacuum Validity";
BA_ "SignalType" SG_ 979 BrkBstVacV "ENM";
BA_ "VNSigAllNodes" SG_ 979 BrkBstVac 1;
BA_ "SignalLongName" SG_ 979 BrkBstVac "Brake Boost Vacuum";
BA_ "SignalType" SG_ 979 BrkBstVac "UNM";
BA_ "VNSigAllNodes" SG_ 979 EngManfldAirTmpV 1;
BA_ "SignalLongName" SG_ 979 EngManfldAirTmpV "Engine Manifold Air Temperature Validity";
BA_ "SignalType" SG_ 979 EngManfldAirTmpV "ENM";
BA_ "VNSigAllNodes" SG_ 979 EngManfldAirTmp 1;
BA_ "SignalLongName" SG_ 979 EngManfldAirTmp "Engine Manifold Air Temperature";
BA_ "SignalType" SG_ 979 EngManfldAirTmp "UNM";
BA_ "Prio" BO_ 546 0;
BA_ "GenMsgSendType" BO_ 546 0;
BA_ "GenMsgCycleTime" BO_ 546 100;
BA_ "MessageSubnet" BO_ 546 2;
BA_ "VNSigAllNodes" SG_ 546 ThrmlRfCmprElctrCrntV 1;
BA_ "SignalLongName" SG_ 546 ThrmlRfCmprElctrCrntV "Thermal Refrigerant Compressor Electrical Current Validity";
BA_ "SignalType" SG_ 546 ThrmlRfCmprElctrCrntV "ENM";
BA_ "VNSigAllNodes" SG_ 546 ThrmlRfCmprElctrCrnt 1;
BA_ "SignalLongName" SG_ 546 ThrmlRfCmprElctrCrnt "Thermal Refrigerant Compressor Electrical Current";
BA_ "SignalType" SG_ 546 ThrmlRfCmprElctrCrnt "UNM";
BA_ "VNSigAllNodes" SG_ 546 ThrmlRefCompStat 1;
BA_ "SignalLongName" SG_ 546 ThrmlRefCompStat "Thermal Refrigerant Compressor Status";
BA_ "SignalType" SG_ 546 ThrmlRefCompStat "ENM";
BA_ "VNSigAllNodes" SG_ 546 ThrmlRefCompSpdV 1;
BA_ "SignalLongName" SG_ 546 ThrmlRefCompSpdV "Thermal Refrigerant Compressor Speed Validity";
BA_ "SignalType" SG_ 546 ThrmlRefCompSpdV "ENM";
BA_ "VNSigAllNodes" SG_ 546 ThrmlRefCompSpd 1;
BA_ "SignalLongName" SG_ 546 ThrmlRefCompSpd "Thermal Refrigerant Compressor Speed";
BA_ "SignalType" SG_ 546 ThrmlRefCompSpd "UNM";
BA_ "VNSigAllNodes" SG_ 546 ThrmlRfCmpOvTmpFltPr 1;
BA_ "SignalLongName" SG_ 546 ThrmlRfCmpOvTmpFltPr "Thermal Refrigerant Compressor Over Temperature Fault Present";
BA_ "SignalType" SG_ 546 ThrmlRfCmpOvTmpFltPr "BLN";
BA_ "VNSigAllNodes" SG_ 546 ThrmlRefCompElecPwrV 1;
BA_ "SignalLongName" SG_ 546 ThrmlRefCompElecPwrV "Thermal Refrigerant Compressor Electrical Power Validity";
BA_ "SignalType" SG_ 546 ThrmlRefCompElecPwrV "ENM";
BA_ "VNSigAllNodes" SG_ 546 ThrmlRefCompElecPwr 1;
BA_ "SignalLongName" SG_ 546 ThrmlRefCompElecPwr "Thermal Refrigerant Compressor Electrical Power";
BA_ "SignalType" SG_ 546 ThrmlRefCompElecPwr "UNM";
BA_ "Prio" BO_ 530 0;
BA_ "GenMsgSendType" BO_ 530 0;
BA_ "GenMsgCycleTime" BO_ 530 1000;
BA_ "MessageSubnet" BO_ 530 2;
BA_ "VNSigAllNodes" SG_ 530 RstVTDTmprDtctd 1;
BA_ "SignalLongName" SG_ 530 RstVTDTmprDtctd "Reset Vehicle Theft Deterrent Tamper Detected";
BA_ "SignalType" SG_ 530 RstVTDTmprDtctd "ENM";
BA_ "VNSigAllNodes" SG_ 530 RstIllDrIdDevDtctd 1;
BA_ "SignalLongName" SG_ 530 RstIllDrIdDevDtctd "Reset Illegitimate Driver Identification Device Detected";
BA_ "SignalType" SG_ 530 RstIllDrIdDevDtctd "ENM";
BA_ "VNSigAllNodes" SG_ 530 RstDrIdDevLrnd 1;
BA_ "SignalLongName" SG_ 530 RstDrIdDevLrnd "Reset Driver Identification Device Learned";
BA_ "SignalType" SG_ 530 RstDrIdDevLrnd "ENM";
BA_ "Prio" BO_ 1239 0;
BA_ "GenMsgSendType" BO_ 1239 0;
BA_ "GenMsgCycleTime" BO_ 1239 500;
BA_ "MessageSubnet" BO_ 1239 2;
BA_ "VNSigAllNodes" SG_ 1239 IntlgntBattSnsBattSOC 1;
BA_ "SignalLongName" SG_ 1239 IntlgntBattSnsBattSOC "Intelligent Battery Sensor Battery State of Charge";
BA_ "SignalType" SG_ 1239 IntlgntBattSnsBattSOC "UNM";
BA_ "VNSigAllNodes" SG_ 1239 BattTemp 1;
BA_ "SignalLongName" SG_ 1239 BattTemp "Battery Temperature";
BA_ "SignalType" SG_ 1239 BattTemp "UNM";
BA_ "VNSigAllNodes" SG_ 1239 BatSOH 1;
BA_ "SignalLongName" SG_ 1239 BatSOH "Battery State Of Health";
BA_ "SignalType" SG_ 1239 BatSOH "UNM";
BA_ "VNSigAllNodes" SG_ 1239 BatSOFVolt 1;
BA_ "SignalLongName" SG_ 1239 BatSOFVolt "Battery State Of Function Voltage";
BA_ "SignalType" SG_ 1239 BatSOFVolt "UNM";
BA_ "VNSigAllNodes" SG_ 1239 BattSOXStat 1;
BA_ "SignalLongName" SG_ 1239 BattSOXStat "Battery SOX Status";
BA_ "SignalType" SG_ 1239 BattSOXStat "ENM";
BA_ "VNSigAllNodes" SG_ 1239 BattTempV 1;
BA_ "SignalLongName" SG_ 1239 BattTempV "Battery Temperature Validity";
BA_ "SignalType" SG_ 1239 BattTempV "ENM";
BA_ "DiagResponse" BO_ 1610 1;
BA_ "Prio" BO_ 1610 0;
BA_ "MessageSubnet" BO_ 1610 2;
BA_ "VNSigAllNodes" SG_ 1610 DgnInf 1;
BA_ "VNSigSLHSSharedDiagnostic" SG_ 1610 DgnInf 1;
BA_ "SignalLongName" SG_ 1610 DgnInf "Diagnostic Information";
BA_ "SignalType" SG_ 1610 DgnInf "UNM";
BA_ "Prio" BO_ 1027 0;
BA_ "GenMsgSendType" BO_ 1027 0;
BA_ "GenMsgCycleTime" BO_ 1027 100;
BA_ "MessageSubnet" BO_ 1027 2;
BA_ "VNSigAllNodes" SG_ 1027 FCO4D_ObjVertVar 1;
BA_ "PacketOrder" SG_ 1027 FCO4D_ObjVertVar 8;
BA_ "SignalLongName" SG_ 1027 FCO4D_ObjVertVar "Forward Camera Object 4 Detected : Object Vertical Variance";
BA_ "SignalType" SG_ 1027 FCO4D_ObjVertVar "SNM";
BA_ "VNSigAllNodes" SG_ 1027 FCO4D_ObjVertPos 1;
BA_ "PacketOrder" SG_ 1027 FCO4D_ObjVertPos 7;
BA_ "SignalLongName" SG_ 1027 FCO4D_ObjVertPos "Forward Camera Object 4 Detected : Object Vertical Position";
BA_ "SignalType" SG_ 1027 FCO4D_ObjVertPos "SNM";
BA_ "VNSigAllNodes" SG_ 1027 FCO4D_ObjTyp 1;
BA_ "PacketOrder" SG_ 1027 FCO4D_ObjTyp 3;
BA_ "SignalLongName" SG_ 1027 FCO4D_ObjTyp "Forward Camera Object 4 Detected : Object Type";
BA_ "SignalType" SG_ 1027 FCO4D_ObjTyp "ENM";
BA_ "VNSigAllNodes" SG_ 1027 FCO4D_ObjQlty 1;
BA_ "PacketOrder" SG_ 1027 FCO4D_ObjQlty 1;
BA_ "SignalLongName" SG_ 1027 FCO4D_ObjQlty "Forward Camera Object 4 Detected : Object Quality";
BA_ "SignalType" SG_ 1027 FCO4D_ObjQlty "ENM";
BA_ "VNSigAllNodes" SG_ 1027 FCO4D_ObjId 1;
BA_ "PacketOrder" SG_ 1027 FCO4D_ObjId 2;
BA_ "SignalLongName" SG_ 1027 FCO4D_ObjId "Forward Camera Object 4 Detected : Object ID";
BA_ "SignalType" SG_ 1027 FCO4D_ObjId "UNM";
BA_ "VNSigAllNodes" SG_ 1027 FCO4D_ObjHorzPos 1;
BA_ "PacketOrder" SG_ 1027 FCO4D_ObjHorzPos 4;
BA_ "SignalLongName" SG_ 1027 FCO4D_ObjHorzPos "Forward Camera Object 4 Detected : Object Horizontal Position";
BA_ "SignalType" SG_ 1027 FCO4D_ObjHorzPos "SNM";
BA_ "VNSigAllNodes" SG_ 1027 FCO4D_ObjHorzDim 1;
BA_ "PacketOrder" SG_ 1027 FCO4D_ObjHorzDim 6;
BA_ "SignalLongName" SG_ 1027 FCO4D_ObjHorzDim "Forward Camera Object 4 Detected : Object Horizontal Dimension";
BA_ "SignalType" SG_ 1027 FCO4D_ObjHorzDim "UNM";
BA_ "VNSigAllNodes" SG_ 1027 FCO4D_ObjDist 1;
BA_ "PacketOrder" SG_ 1027 FCO4D_ObjDist 9;
BA_ "SignalLongName" SG_ 1027 FCO4D_ObjDist "Forward Camera Object 4 Detected : Object Distance";
BA_ "SignalType" SG_ 1027 FCO4D_ObjDist "UNM";
BA_ "VNSigAllNodes" SG_ 1027 FCO4D_DetMthd 1;
BA_ "PacketOrder" SG_ 1027 FCO4D_DetMthd 5;
BA_ "SignalLongName" SG_ 1027 FCO4D_DetMthd "Forward Camera Object 4 Detected : Detection Method";
BA_ "SignalType" SG_ 1027 FCO4D_DetMthd "ENM";
BA_ "Prio" BO_ 1026 0;
BA_ "GenMsgSendType" BO_ 1026 0;
BA_ "GenMsgCycleTime" BO_ 1026 100;
BA_ "MessageSubnet" BO_ 1026 2;
BA_ "VNSigAllNodes" SG_ 1026 FCO3D_ObjVertVar 1;
BA_ "PacketOrder" SG_ 1026 FCO3D_ObjVertVar 8;
BA_ "SignalLongName" SG_ 1026 FCO3D_ObjVertVar "Forward Camera Object 3 Detected : Object Vertical Variance";
BA_ "SignalType" SG_ 1026 FCO3D_ObjVertVar "SNM";
BA_ "VNSigAllNodes" SG_ 1026 FCO3D_ObjVertPos 1;
BA_ "PacketOrder" SG_ 1026 FCO3D_ObjVertPos 7;
BA_ "SignalLongName" SG_ 1026 FCO3D_ObjVertPos "Forward Camera Object 3 Detected : Object Vertical Position";
BA_ "SignalType" SG_ 1026 FCO3D_ObjVertPos "SNM";
BA_ "VNSigAllNodes" SG_ 1026 FCO3D_ObjQlty 1;
BA_ "PacketOrder" SG_ 1026 FCO3D_ObjQlty 1;
BA_ "SignalLongName" SG_ 1026 FCO3D_ObjQlty "Forward Camera Object 3 Detected : Object Quality";
BA_ "SignalType" SG_ 1026 FCO3D_ObjQlty "ENM";
BA_ "VNSigAllNodes" SG_ 1026 FCO3D_ObjDist 1;
BA_ "PacketOrder" SG_ 1026 FCO3D_ObjDist 9;
BA_ "SignalLongName" SG_ 1026 FCO3D_ObjDist "Forward Camera Object 3 Detected : Object Distance";
BA_ "SignalType" SG_ 1026 FCO3D_ObjDist "UNM";
BA_ "VNSigAllNodes" SG_ 1026 FCO3D_DetMthd 1;
BA_ "PacketOrder" SG_ 1026 FCO3D_DetMthd 5;
BA_ "SignalLongName" SG_ 1026 FCO3D_DetMthd "Forward Camera Object 3 Detected : Detection Method";
BA_ "SignalType" SG_ 1026 FCO3D_DetMthd "ENM";
BA_ "VNSigAllNodes" SG_ 1026 FCO3D_ObjHorzPos 1;
BA_ "PacketOrder" SG_ 1026 FCO3D_ObjHorzPos 4;
BA_ "SignalLongName" SG_ 1026 FCO3D_ObjHorzPos "Forward Camera Object 3 Detected : Object Horizontal Position";
BA_ "SignalType" SG_ 1026 FCO3D_ObjHorzPos "SNM";
BA_ "VNSigAllNodes" SG_ 1026 FCO3D_ObjHorzDim 1;
BA_ "PacketOrder" SG_ 1026 FCO3D_ObjHorzDim 6;
BA_ "SignalLongName" SG_ 1026 FCO3D_ObjHorzDim "Forward Camera Object 3 Detected : Object Horizontal Dimension";
BA_ "SignalType" SG_ 1026 FCO3D_ObjHorzDim "UNM";
BA_ "VNSigAllNodes" SG_ 1026 FCO3D_ObjTyp 1;
BA_ "PacketOrder" SG_ 1026 FCO3D_ObjTyp 3;
BA_ "SignalLongName" SG_ 1026 FCO3D_ObjTyp "Forward Camera Object 3 Detected : Object Type";
BA_ "SignalType" SG_ 1026 FCO3D_ObjTyp "ENM";
BA_ "VNSigAllNodes" SG_ 1026 FCO3D_ObjId 1;
BA_ "PacketOrder" SG_ 1026 FCO3D_ObjId 2;
BA_ "SignalLongName" SG_ 1026 FCO3D_ObjId "Forward Camera Object 3 Detected : Object ID";
BA_ "SignalType" SG_ 1026 FCO3D_ObjId "UNM";
BA_ "Prio" BO_ 1025 0;
BA_ "GenMsgSendType" BO_ 1025 0;
BA_ "GenMsgCycleTime" BO_ 1025 100;
BA_ "MessageSubnet" BO_ 1025 2;
BA_ "VNSigAllNodes" SG_ 1025 FCO2D_ObjQlty 1;
BA_ "PacketOrder" SG_ 1025 FCO2D_ObjQlty 2;
BA_ "SignalLongName" SG_ 1025 FCO2D_ObjQlty "Forward Camera Object 2 Detected : Object Quality";
BA_ "SignalType" SG_ 1025 FCO2D_ObjQlty "ENM";
BA_ "VNSigAllNodes" SG_ 1025 FCO2D_ObjDist 1;
BA_ "PacketOrder" SG_ 1025 FCO2D_ObjDist 9;
BA_ "SignalLongName" SG_ 1025 FCO2D_ObjDist "Forward Camera Object 2 Detected : Object Distance";
BA_ "SignalType" SG_ 1025 FCO2D_ObjDist "UNM";
BA_ "VNSigAllNodes" SG_ 1025 FCO2D_ObjVertVar 1;
BA_ "PacketOrder" SG_ 1025 FCO2D_ObjVertVar 8;
BA_ "SignalLongName" SG_ 1025 FCO2D_ObjVertVar "Forward Camera Object 2 Detected : Object Vertical Variance";
BA_ "SignalType" SG_ 1025 FCO2D_ObjVertVar "SNM";
BA_ "VNSigAllNodes" SG_ 1025 FCO2D_ObjVertPos 1;
BA_ "PacketOrder" SG_ 1025 FCO2D_ObjVertPos 7;
BA_ "SignalLongName" SG_ 1025 FCO2D_ObjVertPos "Forward Camera Object 2 Detected : Object Vertical Position";
BA_ "SignalType" SG_ 1025 FCO2D_ObjVertPos "SNM";
BA_ "VNSigAllNodes" SG_ 1025 FCO2D_ObjHorzDim 1;
BA_ "PacketOrder" SG_ 1025 FCO2D_ObjHorzDim 6;
BA_ "SignalLongName" SG_ 1025 FCO2D_ObjHorzDim "Forward Camera Object 2 Detected : Object Horizontal Dimension";
BA_ "SignalType" SG_ 1025 FCO2D_ObjHorzDim "UNM";
BA_ "VNSigAllNodes" SG_ 1025 FCO2D_DetMthd 1;
BA_ "PacketOrder" SG_ 1025 FCO2D_DetMthd 5;
BA_ "SignalLongName" SG_ 1025 FCO2D_DetMthd "Forward Camera Object 2 Detected : Detection Method";
BA_ "SignalType" SG_ 1025 FCO2D_DetMthd "ENM";
BA_ "VNSigAllNodes" SG_ 1025 FCO2D_ObjHorzPos 1;
BA_ "PacketOrder" SG_ 1025 FCO2D_ObjHorzPos 4;
BA_ "SignalLongName" SG_ 1025 FCO2D_ObjHorzPos "Forward Camera Object 2 Detected : Object Horizontal Position";
BA_ "SignalType" SG_ 1025 FCO2D_ObjHorzPos "SNM";
BA_ "VNSigAllNodes" SG_ 1025 FCO2D_ObjTyp 1;
BA_ "PacketOrder" SG_ 1025 FCO2D_ObjTyp 3;
BA_ "SignalLongName" SG_ 1025 FCO2D_ObjTyp "Forward Camera Object 2 Detected : Object Type";
BA_ "SignalType" SG_ 1025 FCO2D_ObjTyp "ENM";
BA_ "VNSigAllNodes" SG_ 1025 FCO2D_ObjId 1;
BA_ "PacketOrder" SG_ 1025 FCO2D_ObjId 2;
BA_ "SignalLongName" SG_ 1025 FCO2D_ObjId "Forward Camera Object 2 Detected : Object ID";
BA_ "SignalType" SG_ 1025 FCO2D_ObjId "UNM";
BA_ "Prio" BO_ 1024 0;
BA_ "GenMsgSendType" BO_ 1024 0;
BA_ "GenMsgCycleTime" BO_ 1024 100;
BA_ "MessageSubnet" BO_ 1024 2;
BA_ "VNSigAllNodes" SG_ 1024 FCO1D_ObjQlty 1;
BA_ "PacketOrder" SG_ 1024 FCO1D_ObjQlty 1;
BA_ "SignalLongName" SG_ 1024 FCO1D_ObjQlty "Forward Camera Object 1 Detected : Object Quality";
BA_ "SignalType" SG_ 1024 FCO1D_ObjQlty "ENM";
BA_ "VNSigAllNodes" SG_ 1024 FCO1D_ObjDist 1;
BA_ "PacketOrder" SG_ 1024 FCO1D_ObjDist 9;
BA_ "SignalLongName" SG_ 1024 FCO1D_ObjDist "Forward Camera Object 1 Detected : Object Distance";
BA_ "SignalType" SG_ 1024 FCO1D_ObjDist "UNM";
BA_ "VNSigAllNodes" SG_ 1024 FCO1D_ObjVertVar 1;
BA_ "PacketOrder" SG_ 1024 FCO1D_ObjVertVar 8;
BA_ "SignalLongName" SG_ 1024 FCO1D_ObjVertVar "Forward Camera Object 1 Detected : Object Vertical Variance";
BA_ "SignalType" SG_ 1024 FCO1D_ObjVertVar "SNM";
BA_ "VNSigAllNodes" SG_ 1024 FCO1D_ObjVertPos 1;
BA_ "PacketOrder" SG_ 1024 FCO1D_ObjVertPos 7;
BA_ "SignalLongName" SG_ 1024 FCO1D_ObjVertPos "Forward Camera Object 1 Detected : Object Vertical Position";
BA_ "SignalType" SG_ 1024 FCO1D_ObjVertPos "SNM";
BA_ "VNSigAllNodes" SG_ 1024 FCO1D_ObjHorzDim 1;
BA_ "PacketOrder" SG_ 1024 FCO1D_ObjHorzDim 4;
BA_ "SignalLongName" SG_ 1024 FCO1D_ObjHorzDim "Forward Camera Object 1 Detected : Object Horizontal Dimension";
BA_ "SignalType" SG_ 1024 FCO1D_ObjHorzDim "UNM";
BA_ "VNSigAllNodes" SG_ 1024 FCO1D_DetMthd 1;
BA_ "PacketOrder" SG_ 1024 FCO1D_DetMthd 6;
BA_ "SignalLongName" SG_ 1024 FCO1D_DetMthd "Forward Camera Object 1 Detected : Detection Method";
BA_ "SignalType" SG_ 1024 FCO1D_DetMthd "ENM";
BA_ "VNSigAllNodes" SG_ 1024 FCO1D_ObjHorzPos 1;
BA_ "PacketOrder" SG_ 1024 FCO1D_ObjHorzPos 1;
BA_ "SignalLongName" SG_ 1024 FCO1D_ObjHorzPos "Forward Camera Object 1 Detected : Object Horizontal Position";
BA_ "SignalType" SG_ 1024 FCO1D_ObjHorzPos "SNM";
BA_ "VNSigAllNodes" SG_ 1024 FCO1D_ObjTyp 1;
BA_ "PacketOrder" SG_ 1024 FCO1D_ObjTyp 5;
BA_ "SignalLongName" SG_ 1024 FCO1D_ObjTyp "Forward Camera Object 1 Detected : Object Type";
BA_ "SignalType" SG_ 1024 FCO1D_ObjTyp "ENM";
BA_ "VNSigAllNodes" SG_ 1024 FCO1D_ObjId 1;
BA_ "PacketOrder" SG_ 1024 FCO1D_ObjId 2;
BA_ "SignalLongName" SG_ 1024 FCO1D_ObjId "Forward Camera Object 1 Detected : Object ID";
BA_ "SignalType" SG_ 1024 FCO1D_ObjId "UNM";
BA_ "Prio" BO_ 508 0;
BA_ "GenMsgSendType" BO_ 508 0;
BA_ "GenMsgCycleTime" BO_ 508 50;
BA_ "MessageSubnet" BO_ 508 2;
BA_ "VNSigAllNodes" SG_ 508 LonLatAccSnsChk 1;
BA_ "SignalLongName" SG_ 508 LonLatAccSnsChk "Longitudinal/Lateral Acceleration Sensor Checksum";
BA_ "SignalType" SG_ 508 LonLatAccSnsChk "UNM";
BA_ "VNSigAllNodes" SG_ 508 LonLatAccSnsValARC 1;
BA_ "SignalLongName" SG_ 508 LonLatAccSnsValARC "Longitudinal/Lateral Acceleration Sensor Value Alive Rolling Count";
BA_ "SignalType" SG_ 508 LonLatAccSnsValARC "UNM";
BA_ "VNSigAllNodes" SG_ 508 LatAccSnsVal 1;
BA_ "SignalLongName" SG_ 508 LatAccSnsVal "Lateral Acceleration Sensor Value";
BA_ "SignalType" SG_ 508 LatAccSnsVal "SNM";
BA_ "VNSigAllNodes" SG_ 508 LonAccSnsVal 1;
BA_ "SignalLongName" SG_ 508 LonAccSnsVal "Longitudinal Acceleration Sensor Value";
BA_ "SignalType" SG_ 508 LonAccSnsVal "SNM";
BA_ "VNSigAllNodes" SG_ 508 CSTBATS_TrqVl 1;
BA_ "PacketOrder" SG_ 508 CSTBATS_TrqVl 2;
BA_ "SignalLongName" SG_ 508 CSTBATS_TrqVl "Chassis System Total Brake Axle Torque Status : Torque Value";
BA_ "SignalType" SG_ 508 CSTBATS_TrqVl "UNM";
BA_ "VNSigAllNodes" SG_ 508 CSTBATS_TrqVlV 1;
BA_ "PacketOrder" SG_ 508 CSTBATS_TrqVlV 1;
BA_ "SignalLongName" SG_ 508 CSTBATS_TrqVlV "Chassis System Total Brake Axle Torque Status : Torque Value Validity";
BA_ "SignalType" SG_ 508 CSTBATS_TrqVlV "ENM";
BA_ "Prio" BO_ 422 0;
BA_ "GenMsgSendType" BO_ 422 0;
BA_ "GenMsgCycleTime" BO_ 422 25;
BA_ "MessageSubnet" BO_ 422 2;
BA_ "VNSigAllNodes" SG_ 422 TrStPTGrdBrkDsMdOvr 1;
BA_ "SignalLongName" SG_ 422 TrStPTGrdBrkDsMdOvr "Transmission State Powertrain Grade Braking  Disable Mode Override";
BA_ "SignalType" SG_ 422 TrStPTGrdBrkDsMdOvr "ENM";
BA_ "VNSigAllNodes" SG_ 422 TrnsHybEngSrtStpOvrd 1;
BA_ "SignalLongName" SG_ 422 TrnsHybEngSrtStpOvrd "Transmission Hybrid Engine Start Stop Override";
BA_ "SignalType" SG_ 422 TrnsHybEngSrtStpOvrd "ENM";
BA_ "Prio" BO_ 647 0;
BA_ "GenMsgSendType" BO_ 647 0;
BA_ "GenMsgCycleTime" BO_ 647 25;
BA_ "MessageSubnet" BO_ 647 2;
BA_ "VNSigAllNodes" SG_ 647 DrvMntnMdCmnd 1;
BA_ "SignalLongName" SG_ 647 DrvMntnMdCmnd "Driver Mountain Mode Commanded";
BA_ "SignalType" SG_ 647 DrvMntnMdCmnd "BLN";
BA_ "VNSigAllNodes" SG_ 647 DrvHldMdCmnd 1;
BA_ "SignalLongName" SG_ 647 DrvHldMdCmnd "Driver Hold Mode Commanded";
BA_ "SignalType" SG_ 647 DrvHldMdCmnd "BLN";
BA_ "VNSigAllNodes" SG_ 647 DrPTGrdBrkDsbMdCmd 1;
BA_ "SignalLongName" SG_ 647 DrPTGrdBrkDsbMdCmd "Driver Powertrain Grade Braking Disable Mode Commanded";
BA_ "SignalType" SG_ 647 DrPTGrdBrkDsbMdCmd "BLN";
BA_ "VNSigAllNodes" SG_ 647 DrvWntrMdCmd 1;
BA_ "SignalLongName" SG_ 647 DrvWntrMdCmd "Driver Winter Mode Commanded";
BA_ "SignalType" SG_ 647 DrvWntrMdCmd "BLN";
BA_ "VNSigAllNodes" SG_ 647 DrvTwHaulMdCmd 1;
BA_ "SignalLongName" SG_ 647 DrvTwHaulMdCmd "Driver Tow Haul Mode Commanded";
BA_ "SignalType" SG_ 647 DrvTwHaulMdCmd "BLN";
BA_ "VNSigAllNodes" SG_ 647 DrvSprtMdCmd 1;
BA_ "SignalLongName" SG_ 647 DrvSprtMdCmd "Driver Sport Mode Commanded";
BA_ "SignalType" SG_ 647 DrvSprtMdCmd "BLN";
BA_ "VNSigAllNodes" SG_ 647 DrvEconMdCmd 1;
BA_ "SignalLongName" SG_ 647 DrvEconMdCmd "Driver Economy Mode Commanded";
BA_ "SignalType" SG_ 647 DrvEconMdCmd "BLN";
BA_ "VNSigAllNodes" SG_ 647 EngCntrlDtrmdTrfCRngV 1;
BA_ "SignalLongName" SG_ 647 EngCntrlDtrmdTrfCRngV "Engine Controller Determined Transfer Case Range Validity";
BA_ "SignalType" SG_ 647 EngCntrlDtrmdTrfCRngV "ENM";
BA_ "VNSigAllNodes" SG_ 647 EngCntrlDtrmdTrfCRng 1;
BA_ "SignalLongName" SG_ 647 EngCntrlDtrmdTrfCRng "Engine Controller Determined Transfer Case Range";
BA_ "SignalType" SG_ 647 EngCntrlDtrmdTrfCRng "ENM";
BA_ "VNSigAllNodes" SG_ 647 EngCtrlUtldTrnCRgPVal 1;
BA_ "SignalLongName" SG_ 647 EngCtrlUtldTrnCRgPVal "Engine Controller Utilized Transfer Case Range Protection Value";
BA_ "SignalType" SG_ 647 EngCtrlUtldTrnCRgPVal "UNM";
BA_ "VNSigAllNodes" SG_ 647 EngCntrlUtldTrnCsRng 1;
BA_ "SignalLongName" SG_ 647 EngCntrlUtldTrnCsRng "Engine Controller Utilized Transfer Case Range";
BA_ "SignalType" SG_ 647 EngCntrlUtldTrnCsRng "ENM";
BA_ "VNSigAllNodes" SG_ 647 EngCntrlUtldTrnCsRgIn 1;
BA_ "SignalLongName" SG_ 647 EngCntrlUtldTrnCsRgIn "Engine Controller Utilized Transfer Case Range Inconsistent";
BA_ "SignalType" SG_ 647 EngCntrlUtldTrnCsRgIn "BLN";
BA_ "VNSigAllNodes" SG_ 647 EngCtrlUtldTrnCRgARC 1;
BA_ "SignalLongName" SG_ 647 EngCtrlUtldTrnCRgARC "Engine Controller Utilized Transfer Case Range Alive Rolling Count";
BA_ "SignalType" SG_ 647 EngCtrlUtldTrnCRgARC "UNM";
BA_ "Prio" BO_ 368 0;
BA_ "GenMsgSendType" BO_ 368 0;
BA_ "GenMsgCycleTime" BO_ 368 100;
BA_ "MessageSubnet" BO_ 368 2;
BA_ "VNSigAllNodes" SG_ 368 EnvIdRspSt5 1;
BA_ "SignalLongName" SG_ 368 EnvIdRspSt5 "Environment Identification Response Status 5";
BA_ "SignalType" SG_ 368 EnvIdRspSt5 "ENM";
BA_ "VNSigAllNodes" SG_ 368 EnvIdRsp5 1;
BA_ "SignalLongName" SG_ 368 EnvIdRsp5 "Environment Identification Response 5";
BA_ "SignalType" SG_ 368 EnvIdRsp5 "UNM";
BA_ "Prio" BO_ 995 0;
BA_ "GenMsgSendType" BO_ 995 0;
BA_ "GenMsgCycleTime" BO_ 995 100;
BA_ "MessageSubnet" BO_ 995 2;
BA_ "VNSigAllNodes" SG_ 995 RdHVltBatMaxSnsTmpV 1;
BA_ "SignalLongName" SG_ 995 RdHVltBatMaxSnsTmpV "Redundant High Voltage Battery Maximum Sensor Temperature Validity";
BA_ "SignalType" SG_ 995 RdHVltBatMaxSnsTmpV "ENM";
BA_ "VNSigAllNodes" SG_ 995 RdHVltBatMaxSnsTmpM 1;
BA_ "SignalLongName" SG_ 995 RdHVltBatMaxSnsTmpM "Redundant High Voltage Battery Maximum Sensor Temperature Mask";
BA_ "SignalType" SG_ 995 RdHVltBatMaxSnsTmpM "ENM";
BA_ "VNSigAllNodes" SG_ 995 RdHVltBatMinClVltV 1;
BA_ "SignalLongName" SG_ 995 RdHVltBatMinClVltV "Redundant High Voltage Battery Minimum Cell Voltage Validity";
BA_ "SignalType" SG_ 995 RdHVltBatMinClVltV "ENM";
BA_ "VNSigAllNodes" SG_ 995 RdHVltBatMinClVltM 1;
BA_ "SignalLongName" SG_ 995 RdHVltBatMinClVltM "Redundant High Voltage Battery Minimum Cell Voltage Mask";
BA_ "SignalType" SG_ 995 RdHVltBatMinClVltM "ENM";
BA_ "VNSigAllNodes" SG_ 995 RdHVBatMinSnsTmpV 1;
BA_ "SignalLongName" SG_ 995 RdHVBatMinSnsTmpV "Redundant High Voltage Battery Minimum Sensor Temperature Validity";
BA_ "SignalType" SG_ 995 RdHVBatMinSnsTmpV "ENM";
BA_ "VNSigAllNodes" SG_ 995 RdHVBatMinSnsTmpM 1;
BA_ "SignalLongName" SG_ 995 RdHVBatMinSnsTmpM "Redundant High Voltage Battery Minimum Sensor Temperature Mask";
BA_ "SignalType" SG_ 995 RdHVBatMinSnsTmpM "ENM";
BA_ "VNSigAllNodes" SG_ 995 RdHVBatMinSnsTmp 1;
BA_ "SignalLongName" SG_ 995 RdHVBatMinSnsTmp "Redundant High Voltage Battery Minimum Sensor Temperature";
BA_ "SignalType" SG_ 995 RdHVBatMinSnsTmp "UNM";
BA_ "VNSigAllNodes" SG_ 995 RdHVltBatMaxClVltV 1;
BA_ "SignalLongName" SG_ 995 RdHVltBatMaxClVltV "Redundant High Voltage Battery Maximum Cell Voltage Validity";
BA_ "SignalType" SG_ 995 RdHVltBatMaxClVltV "ENM";
BA_ "VNSigAllNodes" SG_ 995 RdHVltBatMaxClVltM 1;
BA_ "SignalLongName" SG_ 995 RdHVltBatMaxClVltM "Redundant High Voltage Battery Maximum Cell Voltage Mask";
BA_ "SignalType" SG_ 995 RdHVltBatMaxClVltM "ENM";
BA_ "VNSigAllNodes" SG_ 995 RdHVltBatMinClVlt 1;
BA_ "SignalLongName" SG_ 995 RdHVltBatMinClVlt "Redundant High Voltage Battery Minimum Cell Voltage";
BA_ "SignalType" SG_ 995 RdHVltBatMinClVlt "UNM";
BA_ "VNSigAllNodes" SG_ 995 RdHVltBatMaxSnsTmp 1;
BA_ "SignalLongName" SG_ 995 RdHVltBatMaxSnsTmp "Redundant High Voltage Battery Maximum Sensor Temperature";
BA_ "SignalType" SG_ 995 RdHVltBatMaxSnsTmp "UNM";
BA_ "VNSigAllNodes" SG_ 995 RdHVltBatMaxClVlt 1;
BA_ "SignalLongName" SG_ 995 RdHVltBatMaxClVlt "Redundant High Voltage Battery Maximum Cell Voltage";
BA_ "SignalType" SG_ 995 RdHVltBatMaxClVlt "UNM";
BA_ "VNSigAllNodes" SG_ 995 RdHVltBatAvgClVltV 1;
BA_ "SignalLongName" SG_ 995 RdHVltBatAvgClVltV "Redundant High Voltage Battery Average Cell Voltage Validity";
BA_ "SignalType" SG_ 995 RdHVltBatAvgClVltV "ENM";
BA_ "VNSigAllNodes" SG_ 995 RdHVltBatAvgClVltM 1;
BA_ "SignalLongName" SG_ 995 RdHVltBatAvgClVltM "Redundant High Voltage Battery Average Cell Voltage Mask";
BA_ "SignalType" SG_ 995 RdHVltBatAvgClVltM "ENM";
BA_ "VNSigAllNodes" SG_ 995 RdHVltBatAvgClVlt 1;
BA_ "SignalLongName" SG_ 995 RdHVltBatAvgClVlt "Redundant High Voltage Battery Average Cell Voltage";
BA_ "SignalType" SG_ 995 RdHVltBatAvgClVlt "UNM";
BA_ "Prio" BO_ 971 0;
BA_ "GenMsgSendType" BO_ 971 0;
BA_ "GenMsgCycleTime" BO_ 971 100;
BA_ "MessageSubnet" BO_ 971 2;
BA_ "VNSigAllNodes" SG_ 971 BatVltHiResV 1;
BA_ "SignalLongName" SG_ 971 BatVltHiResV "Battery Voltage High Resolution Validity";
BA_ "SignalType" SG_ 971 BatVltHiResV "ENM";
BA_ "VNSigAllNodes" SG_ 971 BatVltHiRes 1;
BA_ "SignalLongName" SG_ 971 BatVltHiRes "Battery Voltage High Resolution";
BA_ "SignalType" SG_ 971 BatVltHiRes "UNM";
BA_ "VNSigAllNodes" SG_ 971 BCHR_BattCrntRwVal 1;
BA_ "PacketOrder" SG_ 971 BCHR_BattCrntRwVal 3;
BA_ "SignalLongName" SG_ 971 BCHR_BattCrntRwVal "Battery Current High Resolution : Battery Current Raw Value";
BA_ "SignalType" SG_ 971 BCHR_BattCrntRwVal "UNM";
BA_ "VNSigAllNodes" SG_ 971 BCHR_BattCrntRwVlMu 1;
BA_ "PacketOrder" SG_ 971 BCHR_BattCrntRwVlMu 2;
BA_ "SignalLongName" SG_ 971 BCHR_BattCrntRwVlMu "Battery Current High Resolution : Battery Current Raw Value Multiplier";
BA_ "SignalType" SG_ 971 BCHR_BattCrntRwVlMu "ENM";
BA_ "VNSigAllNodes" SG_ 971 BCHR_BattCrntRwValV 1;
BA_ "PacketOrder" SG_ 971 BCHR_BattCrntRwValV 1;
BA_ "SignalLongName" SG_ 971 BCHR_BattCrntRwValV "Battery Current High Resolution : Battery Current Raw Value Validity";
BA_ "SignalType" SG_ 971 BCHR_BattCrntRwValV "ENM";
BA_ "Prio" BO_ 209 0;
BA_ "GenMsgSendType" BO_ 209 0;
BA_ "GenMsgCycleTime" BO_ 209 10;
BA_ "MessageSubnet" BO_ 209 2;
BA_ "VNSigAllNodes" SG_ 209 ChsBrkPdlPsERltdV 1;
BA_ "SignalLongName" SG_ 209 ChsBrkPdlPsERltdV "Chassis Brake Pedal Position Emissions Related Validity";
BA_ "SignalType" SG_ 209 ChsBrkPdlPsERltdV "ENM";
BA_ "VNSigAllNodes" SG_ 209 ChsBrkPdlPsERltdPVal 1;
BA_ "SignalLongName" SG_ 209 ChsBrkPdlPsERltdPVal "Chassis Brake Pedal Position Emissions Related Protection Value";
BA_ "SignalType" SG_ 209 ChsBrkPdlPsERltdPVal "UNM";
BA_ "VNSigAllNodes" SG_ 209 ChsBrkPdlPsERltdARC 1;
BA_ "SignalLongName" SG_ 209 ChsBrkPdlPsERltdARC "Chassis Brake Pedal Position Emissions Related Alive Rolling Count";
BA_ "SignalType" SG_ 209 ChsBrkPdlPsERltdARC "UNM";
BA_ "VNSigAllNodes" SG_ 209 ChsBrkPdlPsERltd 1;
BA_ "SignalLongName" SG_ 209 ChsBrkPdlPsERltd "Chassis Brake Pedal Position Emissions Related";
BA_ "SignalType" SG_ 209 ChsBrkPdlPsERltd "UNM";
BA_ "VNSigAllNodes" SG_ 209 DrvIntndTtlBrkTrqPVal 1;
BA_ "SignalLongName" SG_ 209 DrvIntndTtlBrkTrqPVal "Driver Intended Total Brake Torque Protection Value";
BA_ "SignalType" SG_ 209 DrvIntndTtlBrkTrqPVal "UNM";
BA_ "VNSigAllNodes" SG_ 209 DrvIntndTtlBrkTrqARC 1;
BA_ "SignalLongName" SG_ 209 DrvIntndTtlBrkTrqARC "Driver Intended Total Brake Torque Alive Rolling Count";
BA_ "SignalType" SG_ 209 DrvIntndTtlBrkTrqARC "UNM";
BA_ "VNSigAllNodes" SG_ 209 DrvIntndTtlBrkTrq 1;
BA_ "SignalLongName" SG_ 209 DrvIntndTtlBrkTrq "Driver Intended Total Brake Torque";
BA_ "SignalType" SG_ 209 DrvIntndTtlBrkTrq "UNM";
BA_ "Prio" BO_ 454 0;
BA_ "GenMsgSendType" BO_ 454 0;
BA_ "GenMsgCycleTime" BO_ 454 25;
BA_ "MessageSubnet" BO_ 454 2;
BA_ "VNSigAllNodes" SG_ 454 ChsSysPrdAxlTqRqPV 1;
BA_ "SignalLongName" SG_ 454 ChsSysPrdAxlTqRqPV "Chassis System Predicted Axle Torque Request Protection Value";
BA_ "SignalType" SG_ 454 ChsSysPrdAxlTqRqPV "UNM";
BA_ "VNSigAllNodes" SG_ 454 CSPATR_TrqIntrvnTyp 1;
BA_ "PacketOrder" SG_ 454 CSPATR_TrqIntrvnTyp 3;
BA_ "SignalLongName" SG_ 454 CSPATR_TrqIntrvnTyp "Chassis System Predicted Axle Torque Request : Torque Intervention Type";
BA_ "SignalType" SG_ 454 CSPATR_TrqIntrvnTyp "ENM";
BA_ "VNSigAllNodes" SG_ 454 CSPATR_PrdTrqRqVal 1;
BA_ "PacketOrder" SG_ 454 CSPATR_PrdTrqRqVal 2;
BA_ "SignalLongName" SG_ 454 CSPATR_PrdTrqRqVal "Chassis System Predicted Axle Torque Request : Predicted Torque Request Value";
BA_ "SignalType" SG_ 454 CSPATR_PrdTrqRqVal "UNM";
BA_ "VNSigAllNodes" SG_ 454 CSPATR_TrqRqTyp 1;
BA_ "PacketOrder" SG_ 454 CSPATR_TrqRqTyp 1;
BA_ "SignalLongName" SG_ 454 CSPATR_TrqRqTyp "Chassis System Predicted Axle Torque Request : Torque Request Type";
BA_ "SignalType" SG_ 454 CSPATR_TrqRqTyp "ENM";
BA_ "VNSigAllNodes" SG_ 454 ChsSysImmAxlTqRqVal 1;
BA_ "SignalLongName" SG_ 454 ChsSysImmAxlTqRqVal "Chassis System Immediate Axle Torque Request Value";
BA_ "SignalType" SG_ 454 ChsSysImmAxlTqRqVal "UNM";
BA_ "VNSigAllNodes" SG_ 454 ChsSysAxlTqRqRspTyp 1;
BA_ "SignalLongName" SG_ 454 ChsSysAxlTqRqRspTyp "Chassis System Axle Torque Request Response Type";
BA_ "SignalType" SG_ 454 ChsSysAxlTqRqRspTyp "ENM";
BA_ "VNSigAllNodes" SG_ 454 ChsSysPrdAxlTqRqARC 1;
BA_ "SignalLongName" SG_ 454 ChsSysPrdAxlTqRqARC "Chassis System Predicted Axle Torque Request Alive Rolling Count";
BA_ "SignalType" SG_ 454 ChsSysPrdAxlTqRqARC "UNM";
BA_ "Prio" BO_ 554 0;
BA_ "GenMsgSendType" BO_ 554 0;
BA_ "GenMsgCycleTime" BO_ 554 100;
BA_ "MessageSubnet" BO_ 554 2;
BA_ "VNSigAllNodes" SG_ 554 ElecPrkBrkApplStatPV 1;
BA_ "SignalLongName" SG_ 554 ElecPrkBrkApplStatPV "Electric Park Brake Application Status Protection Value";
BA_ "SignalType" SG_ 554 ElecPrkBrkApplStatPV "UNM";
BA_ "VNSigAllNodes" SG_ 554 ElecPrkBrkAvailStatPV 1;
BA_ "SignalLongName" SG_ 554 ElecPrkBrkAvailStatPV "Electric Park Brake Availability Status Protection Value";
BA_ "SignalType" SG_ 554 ElecPrkBrkAvailStatPV "UNM";
BA_ "VNSigAllNodes" SG_ 554 ElecPrkBrkAvailStat 1;
BA_ "SignalLongName" SG_ 554 ElecPrkBrkAvailStat "Electric Park Brake Availability Status";
BA_ "SignalType" SG_ 554 ElecPrkBrkAvailStat "ENM";
BA_ "VNSigAllNodes" SG_ 554 ElecPrkBrkStatRC 1;
BA_ "SignalLongName" SG_ 554 ElecPrkBrkStatRC "Electric Park Brake Status Rolling Count";
BA_ "SignalType" SG_ 554 ElecPrkBrkStatRC "UNM";
BA_ "VNSigAllNodes" SG_ 554 ElecPrkBrkApplStat 1;
BA_ "SignalLongName" SG_ 554 ElecPrkBrkApplStat "Electric Park Brake Application Status";
BA_ "SignalType" SG_ 554 ElecPrkBrkApplStat "ENM";
BA_ "Prio" BO_ 487 0;
BA_ "GenMsgSendType" BO_ 487 0;
BA_ "GenMsgCycleTime" BO_ 487 12;
BA_ "MessageSubnet" BO_ 487 2;
BA_ "VNSigAllNodes" SG_ 487 CmmndAirFuelRatio 1;
BA_ "SignalLongName" SG_ 487 CmmndAirFuelRatio "Commanded Air Fuel Ratio";
BA_ "SignalType" SG_ 487 CmmndAirFuelRatio "UNM";
BA_ "VNSigAllNodes" SG_ 487 InstFuelFlowEst 1;
BA_ "SignalLongName" SG_ 487 InstFuelFlowEst "Instantaneous Fuel Flow Estimate";
BA_ "SignalType" SG_ 487 InstFuelFlowEst "UNM";
BA_ "VNSigAllNodes" SG_ 487 FuelDelPressRqd 1;
BA_ "SignalLongName" SG_ 487 FuelDelPressRqd "Fuel Delivery Pressure Requested";
BA_ "SignalType" SG_ 487 FuelDelPressRqd "UNM";
BA_ "VNSigAllNodes" SG_ 487 EngRunng 1;
BA_ "SignalLongName" SG_ 487 EngRunng "Engine Running";
BA_ "SignalType" SG_ 487 EngRunng "BLN";
BA_ "VNSigAllNodes" SG_ 487 FlPmpEDscOtptCmdSta 1;
BA_ "SignalLongName" SG_ 487 FlPmpEDscOtptCmdSta "Fuel Pump Enabled Discrete Output Commanded Status";
BA_ "SignalType" SG_ 487 FlPmpEDscOtptCmdSta "ENM";
BA_ "VNSigAllNodes" SG_ 487 FuelCntlSysFltPrsnt 1;
BA_ "SignalLongName" SG_ 487 FuelCntlSysFltPrsnt "Fuel Control System Fault Present";
BA_ "SignalType" SG_ 487 FuelCntlSysFltPrsnt "BLN";
BA_ "VNSigAllNodes" SG_ 487 HiPresFuelPmpDelDur 1;
BA_ "SignalLongName" SG_ 487 HiPresFuelPmpDelDur "High Pressure Fuel Pump Delivery Duration";
BA_ "SignalType" SG_ 487 HiPresFuelPmpDelDur "UNM";
BA_ "VNSigAllNodes" SG_ 487 HiPresFuelPmpCntMd 1;
BA_ "SignalLongName" SG_ 487 HiPresFuelPmpCntMd "High Pressure Fuel Pump Control Mode";
BA_ "SignalType" SG_ 487 HiPresFuelPmpCntMd "ENM";
BA_ "Prio" BO_ 566 0;
BA_ "GenMsgSendType" BO_ 566 0;
BA_ "GenMsgCycleTime" BO_ 566 100;
BA_ "MessageSubnet" BO_ 566 2;
BA_ "VNSigAllNodes" SG_ 566 RdHVBatLwParMdReq 1;
BA_ "SignalLongName" SG_ 566 RdHVBatLwParMdReq "Redundant High Voltage Battery Low Parasitic Mode Requested";
BA_ "SignalType" SG_ 566 RdHVBatLwParMdReq "BLN";
BA_ "VNSigAllNodes" SG_ 566 RdHVBtClOVFFTstRq 1;
BA_ "SignalLongName" SG_ 566 RdHVBtClOVFFTstRq "Redundant High Voltage Battery Cell Over Voltage Fault Flag Test Req";
BA_ "SignalType" SG_ 566 RdHVBtClOVFFTstRq "BLN";
BA_ "VNSigAllNodes" SG_ 566 RdHVBtClOVFFTstIdx 1;
BA_ "SignalLongName" SG_ 566 RdHVBtClOVFFTstIdx "Redundant High Voltage Battery Cell Over Voltage Fault Flag Test Index";
BA_ "SignalType" SG_ 566 RdHVBtClOVFFTstIdx "UNM";
BA_ "VNSigAllNodes" SG_ 566 ClimCtrlHVDvcShtdwnCmd 1;
BA_ "SignalLongName" SG_ 566 ClimCtrlHVDvcShtdwnCmd "Climate Control High Voltage Device Shutdown Commanded";
BA_ "SignalType" SG_ 566 ClimCtrlHVDvcShtdwnCmd "BLN";
BA_ "VNSigAllNodes" SG_ 566 VICntlModRunCrkTrmSt 1;
BA_ "SignalLongName" SG_ 566 VICntlModRunCrkTrmSt "Vehicle Integration Control Module Run Crank Terminal Status";
BA_ "SignalType" SG_ 566 VICntlModRunCrkTrmSt "ENM";
BA_ "VNSigAllNodes" SG_ 566 VICMHVEnMgCmEnTrS 1;
BA_ "SignalLongName" SG_ 566 VICMHVEnMgCmEnTrS "VICM High Voltage Energy Management Comm Enable Terminal Status";
BA_ "SignalType" SG_ 566 VICMHVEnMgCmEnTrS "ENM";
BA_ "VNSigAllNodes" SG_ 566 ChrgSysPrkBrkAnmsBrkReqPVal 1;
BA_ "SignalLongName" SG_ 566 ChrgSysPrkBrkAnmsBrkReqPVal "Charging System Park Brake Autonomous Apply Request Protection Value";
BA_ "SignalType" SG_ 566 ChrgSysPrkBrkAnmsBrkReqPVal "UNM";
BA_ "VNSigAllNodes" SG_ 566 ChrgSysPrkBrkAnmsBrkReqARC 1;
BA_ "SignalLongName" SG_ 566 ChrgSysPrkBrkAnmsBrkReqARC "Charging System Park Brake Autonomous Apply Request Alive Rolling Count";
BA_ "SignalType" SG_ 566 ChrgSysPrkBrkAnmsBrkReqARC "UNM";
BA_ "VNSigAllNodes" SG_ 566 ChrgSysPrkBrkAnmsBrkReq 1;
BA_ "SignalLongName" SG_ 566 ChrgSysPrkBrkAnmsBrkReq "Charging System Park Brake Autonomous Apply Request";
BA_ "SignalType" SG_ 566 ChrgSysPrkBrkAnmsBrkReq "BLN";
BA_ "VNSigAllNodes" SG_ 566 VICMClrLgsDgInfo 1;
BA_ "SignalLongName" SG_ 566 VICMClrLgsDgInfo "Vehicle Integration Controller Module Clear Legislative Diagnostic Info";
BA_ "SignalType" SG_ 566 VICMClrLgsDgInfo "BLN";
BA_ "VNSigAllNodes" SG_ 566 HybVehHiVltSysDisbld_236 1;
BA_ "SignalLongName" SG_ 566 HybVehHiVltSysDisbld_236 "Hybrid Vehicle High Voltage System Disabled";
BA_ "SignalType" SG_ 566 HybVehHiVltSysDisbld_236 "BLN";
BA_ "VNSigAllNodes" SG_ 566 ThrmlRefCompSpdReq 1;
BA_ "SignalLongName" SG_ 566 ThrmlRefCompSpdReq "Thermal Refrigerant Compressor Speed Request";
BA_ "SignalType" SG_ 566 ThrmlRefCompSpdReq "UNM";
BA_ "Prio" BO_ 421 0;
BA_ "GenMsgSendType" BO_ 421 0;
BA_ "GenMsgCycleTime" BO_ 421 25;
BA_ "MessageSubnet" BO_ 421 2;
BA_ "VNSigAllNodes" SG_ 421 AccPwrMdlHiVltInpCrnt 1;
BA_ "SignalLongName" SG_ 421 AccPwrMdlHiVltInpCrnt "Accessory Power Module High Voltage Input Current";
BA_ "GenSigStartValue" SG_ 421 AccPwrMdlHiVltInpCrnt 40;
BA_ "SignalType" SG_ 421 AccPwrMdlHiVltInpCrnt "UNM";
BA_ "VNSigAllNodes" SG_ 421 AccPwrMdlHiVltInpCrntV 1;
BA_ "SignalLongName" SG_ 421 AccPwrMdlHiVltInpCrntV "Accessory Power Module High Voltage Input Current Validity";
BA_ "SignalType" SG_ 421 AccPwrMdlHiVltInpCrntV "ENM";
BA_ "VNSigAllNodes" SG_ 421 HTGR_ReqVal 1;
BA_ "SignalLongName" SG_ 421 HTGR_ReqVal "Hybrid Transmission Gear Request : Request Value";
BA_ "SignalType" SG_ 421 HTGR_ReqVal "ENM";
BA_ "VNSigAllNodes" SG_ 421 HTGR_ReqTyp 1;
BA_ "SignalLongName" SG_ 421 HTGR_ReqTyp "Hybrid Transmission Gear Request : Request Type";
BA_ "SignalType" SG_ 421 HTGR_ReqTyp "ENM";
BA_ "VNSigAllNodes" SG_ 421 HTGR_ReqPrty 1;
BA_ "SignalLongName" SG_ 421 HTGR_ReqPrty "Hybrid Transmission Gear Request : Request Priority";
BA_ "SignalType" SG_ 421 HTGR_ReqPrty "ENM";
BA_ "VNSigAllNodes" SG_ 421 HTCCR_ReqVal 1;
BA_ "SignalLongName" SG_ 421 HTCCR_ReqVal "Hybrid Torque Converter Clutch Request : Request Value";
BA_ "SignalType" SG_ 421 HTCCR_ReqVal "ENM";
BA_ "VNSigAllNodes" SG_ 421 HTCCR_ReqPrty 1;
BA_ "SignalLongName" SG_ 421 HTCCR_ReqPrty "Hybrid Torque Converter Clutch Request : Request Priority";
BA_ "SignalType" SG_ 421 HTCCR_ReqPrty "ENM";
BA_ "VNSigAllNodes" SG_ 421 TrnsAuxPmpAct 1;
BA_ "SignalLongName" SG_ 421 TrnsAuxPmpAct "Transmission Auxiliary Pump Active";
BA_ "SignalType" SG_ 421 TrnsAuxPmpAct "BLN";
BA_ "VNSigAllNodes" SG_ 421 HybSnsBrkPdlPosV 1;
BA_ "SignalLongName" SG_ 421 HybSnsBrkPdlPosV "Hybrid Sensed Brake Pedal Position Validity";
BA_ "SignalType" SG_ 421 HybSnsBrkPdlPosV "ENM";
BA_ "VNSigAllNodes" SG_ 421 HybSnsBrkPdlPosPVal 1;
BA_ "SignalLongName" SG_ 421 HybSnsBrkPdlPosPVal "Hybrid Sensed Brake Pedal Position Protection Value";
BA_ "SignalType" SG_ 421 HybSnsBrkPdlPosPVal "UNM";
BA_ "VNSigAllNodes" SG_ 421 HybSnsBrkPdlPosARC 1;
BA_ "SignalLongName" SG_ 421 HybSnsBrkPdlPosARC "Hybrid Sensed Brake Pedal Position Alive Rolling Count";
BA_ "SignalType" SG_ 421 HybSnsBrkPdlPosARC "UNM";
BA_ "VNSigAllNodes" SG_ 421 HybSnsBrkPdlPos 1;
BA_ "SignalLongName" SG_ 421 HybSnsBrkPdlPos "Hybrid Sensed Brake Pedal Position";
BA_ "SignalType" SG_ 421 HybSnsBrkPdlPos "UNM";
BA_ "Prio" BO_ 456 0;
BA_ "GenMsgSendType" BO_ 456 0;
BA_ "GenMsgCycleTime" BO_ 456 12;
BA_ "MessageSubnet" BO_ 456 2;
BA_ "VNSigAllNodes" SG_ 456 PerfTrcEngSpdReqProt 1;
BA_ "SignalLongName" SG_ 456 PerfTrcEngSpdReqProt "Performance Traction Engine Speed Request Protection";
BA_ "SignalType" SG_ 456 PerfTrcEngSpdReqProt "UNM";
BA_ "VNSigAllNodes" SG_ 456 PTESR_EngSpdRqVal 1;
BA_ "PacketOrder" SG_ 456 PTESR_EngSpdRqVal 3;
BA_ "SignalLongName" SG_ 456 PTESR_EngSpdRqVal "Performance Traction Engine Speed Request : Engine Speed Request Value";
BA_ "SignalType" SG_ 456 PTESR_EngSpdRqVal "UNM";
BA_ "VNSigAllNodes" SG_ 456 PTESR_EngSpdCntlRs 1;
BA_ "PacketOrder" SG_ 456 PTESR_EngSpdCntlRs 2;
BA_ "SignalLongName" SG_ 456 PTESR_EngSpdCntlRs "Performance Traction Engine Speed Request : Engine Speed Control Response";
BA_ "SignalType" SG_ 456 PTESR_EngSpdCntlRs "ENM";
BA_ "VNSigAllNodes" SG_ 456 PTESR_EngSpdIntTyp 1;
BA_ "PacketOrder" SG_ 456 PTESR_EngSpdIntTyp 1;
BA_ "SignalLongName" SG_ 456 PTESR_EngSpdIntTyp "Performance Traction Engine Speed Request : Engine Speed Intervention Type";
BA_ "SignalType" SG_ 456 PTESR_EngSpdIntTyp "ENM";
BA_ "VNSigAllNodes" SG_ 456 PerfTrcTrqRqProt 1;
BA_ "SignalLongName" SG_ 456 PerfTrcTrqRqProt "Performance Traction Torque Request Protection";
BA_ "SignalType" SG_ 456 PerfTrcTrqRqProt "UNM";
BA_ "VNSigAllNodes" SG_ 456 PTTR_TrqReqVal 1;
BA_ "PacketOrder" SG_ 456 PTTR_TrqReqVal 3;
BA_ "SignalLongName" SG_ 456 PTTR_TrqReqVal "Performance Traction Torque Request : Torque Request Value";
BA_ "SignalType" SG_ 456 PTTR_TrqReqVal "UNM";
BA_ "VNSigAllNodes" SG_ 456 PTTR_TrqRedRlzSugg 1;
BA_ "PacketOrder" SG_ 456 PTTR_TrqRedRlzSugg 2;
BA_ "SignalLongName" SG_ 456 PTTR_TrqRedRlzSugg "Performance Traction Torque Request : Torque Reduction Realization Suggestion";
BA_ "SignalType" SG_ 456 PTTR_TrqRedRlzSugg "ENM";
BA_ "VNSigAllNodes" SG_ 456 PTTR_TrqInvTyp 1;
BA_ "PacketOrder" SG_ 456 PTTR_TrqInvTyp 1;
BA_ "SignalLongName" SG_ 456 PTTR_TrqInvTyp "Performance Traction Torque Request : Torque Intervention Type";
BA_ "SignalType" SG_ 456 PTTR_TrqInvTyp "ENM";
BA_ "VNSigAllNodes" SG_ 456 PerfTrcARC 1;
BA_ "SignalLongName" SG_ 456 PerfTrcARC "Performance Traction Alive Rolling Count";
BA_ "SignalType" SG_ 456 PerfTrcARC "UNM";
BA_ "Prio" BO_ 884 0;
BA_ "GenMsgSendType" BO_ 884 0;
BA_ "GenMsgCycleTime" BO_ 884 40;
BA_ "MessageSubnet" BO_ 884 2;
BA_ "VNSigAllNodes" SG_ 884 AdvWthrStat 1;
BA_ "SignalLongName" SG_ 884 AdvWthrStat "Adverse Weather Status";
BA_ "SignalType" SG_ 884 AdvWthrStat "ENM";
BA_ "VNSigAllNodes" SG_ 884 RgDtLgtSrcHrtAngVcty 1;
BA_ "SignalLongName" SG_ 884 RgDtLgtSrcHrtAngVcty "Right Detected Light Source Horizontal Angular Velocity";
BA_ "SignalType" SG_ 884 RgDtLgtSrcHrtAngVcty "SNM";
BA_ "VNSigAllNodes" SG_ 884 RgDtLgtSrcHrtAngl 1;
BA_ "SignalLongName" SG_ 884 RgDtLgtSrcHrtAngl "Right Detected Light Source Horizontal Angle";
BA_ "SignalType" SG_ 884 RgDtLgtSrcHrtAngl "SNM";
BA_ "VNSigAllNodes" SG_ 884 LfDtLgtSrcHrtAnVcty 1;
BA_ "SignalLongName" SG_ 884 LfDtLgtSrcHrtAnVcty "Left Detected Light Source Horizontal Angular Velocity";
BA_ "SignalType" SG_ 884 LfDtLgtSrcHrtAnVcty "SNM";
BA_ "VNSigAllNodes" SG_ 884 LfDtLgtSrcHrtAngl 1;
BA_ "SignalLongName" SG_ 884 LfDtLgtSrcHrtAngl "Left Detected Light Source Horizontal Angle";
BA_ "SignalType" SG_ 884 LfDtLgtSrcHrtAngl "SNM";
BA_ "VNSigAllNodes" SG_ 884 DtctdLghtSrcDstnc 1;
BA_ "SignalLongName" SG_ 884 DtctdLghtSrcDstnc "Detected Light Source Distance";
BA_ "SignalType" SG_ 884 DtctdLghtSrcDstnc "UNM";
BA_ "VNSigAllNodes" SG_ 884 DtctdLghtSrcVrtclAngl 1;
BA_ "SignalLongName" SG_ 884 DtctdLghtSrcVrtclAngl "Detected Light Source Vertical Angle";
BA_ "SignalType" SG_ 884 DtctdLghtSrcVrtclAngl "SNM";
BA_ "VNSigAllNodes" SG_ 884 DtctdLghtSrcDrvngDrctn 1;
BA_ "SignalLongName" SG_ 884 DtctdLghtSrcDrvngDrctn "Detected Light Source Driving Direction";
BA_ "SignalType" SG_ 884 DtctdLghtSrcDrvngDrctn "ENM";
BA_ "VNSigAllNodes" SG_ 884 TwnDtctnSts 1;
BA_ "SignalLongName" SG_ 884 TwnDtctnSts "Town Detection Status";
BA_ "SignalType" SG_ 884 TwnDtctnSts "ENM";
BA_ "VNSigAllNodes" SG_ 884 DtctdLghtSrcDstncV 1;
BA_ "SignalLongName" SG_ 884 DtctdLghtSrcDstncV "Detected Light Source Distance Validity";
BA_ "SignalType" SG_ 884 DtctdLghtSrcDstncV "ENM";
BA_ "VNSigAllNodes" SG_ 884 IntLghtRngAct 1;
BA_ "SignalLongName" SG_ 884 IntLghtRngAct "Intelligent Light Ranging Active";
BA_ "SignalType" SG_ 884 IntLghtRngAct "BLN";
BA_ "Prio" BO_ 882 0;
BA_ "GenMsgSendType" BO_ 882 0;
BA_ "GenMsgCycleTime" BO_ 882 40;
BA_ "MessageSubnet" BO_ 882 2;
BA_ "VNSigAllNodes" SG_ 882 AdvFrntLghtSysHiBmIO 1;
BA_ "SignalLongName" SG_ 882 AdvFrntLghtSysHiBmIO "Advanced Front Lighting System High Beam Indication On";
BA_ "SignalType" SG_ 882 AdvFrntLghtSysHiBmIO "BLN";
BA_ "VNSigAllNodes" SG_ 882 RghtHndLftHndTrffc 1;
BA_ "SignalLongName" SG_ 882 RghtHndLftHndTrffc "Righthand Lefthand Traffic";
BA_ "SignalType" SG_ 882 RghtHndLftHndTrffc "ENM";
BA_ "VNSigAllNodes" SG_ 882 RghtHdlmpXnPwr 1;
BA_ "SignalLongName" SG_ 882 RghtHdlmpXnPwr "Right Headlamp Xenon Power";
BA_ "SignalType" SG_ 882 RghtHdlmpXnPwr "UNM";
BA_ "VNSigAllNodes" SG_ 882 RghtHdlmpSwvlAngl 1;
BA_ "SignalLongName" SG_ 882 RghtHdlmpSwvlAngl "Right Headlamp Swivel Angle";
BA_ "SignalType" SG_ 882 RghtHdlmpSwvlAngl "SNM";
BA_ "VNSigAllNodes" SG_ 882 RghtHdlmpStcBnd 1;
BA_ "SignalLongName" SG_ 882 RghtHdlmpStcBnd "Right Headlamp Static Bend";
BA_ "SignalType" SG_ 882 RghtHdlmpStcBnd "UNM";
BA_ "VNSigAllNodes" SG_ 882 RghtHdlmpLvllngPstn 1;
BA_ "SignalLongName" SG_ 882 RghtHdlmpLvllngPstn "Right Headlamp Levelling Position";
BA_ "SignalType" SG_ 882 RghtHdlmpLvllngPstn "SNM";
BA_ "VNSigAllNodes" SG_ 882 RghtHdlmpDrmPstn 1;
BA_ "SignalLongName" SG_ 882 RghtHdlmpDrmPstn "Right Headlamp Drum Position";
BA_ "SignalType" SG_ 882 RghtHdlmpDrmPstn "UNM";
BA_ "VNSigAllNodes" SG_ 882 LftHdlmpXnPwr 1;
BA_ "SignalLongName" SG_ 882 LftHdlmpXnPwr "Left Headlamp Xenon Power";
BA_ "SignalType" SG_ 882 LftHdlmpXnPwr "UNM";
BA_ "VNSigAllNodes" SG_ 882 LftHdlmpSwvlAngl 1;
BA_ "SignalLongName" SG_ 882 LftHdlmpSwvlAngl "Left Headlamp Swivel Angle";
BA_ "SignalType" SG_ 882 LftHdlmpSwvlAngl "SNM";
BA_ "VNSigAllNodes" SG_ 882 LftHdlmpStcBnd 1;
BA_ "SignalLongName" SG_ 882 LftHdlmpStcBnd "Left Headlamp Static Bend";
BA_ "SignalType" SG_ 882 LftHdlmpStcBnd "UNM";
BA_ "VNSigAllNodes" SG_ 882 LftHdlmpLvllngPstn 1;
BA_ "SignalLongName" SG_ 882 LftHdlmpLvllngPstn "Left Headlamp Levelling Position";
BA_ "SignalType" SG_ 882 LftHdlmpLvllngPstn "SNM";
BA_ "VNSigAllNodes" SG_ 882 LftHdlmpDrmPstn 1;
BA_ "SignalLongName" SG_ 882 LftHdlmpDrmPstn "Left Headlamp Drum Position";
BA_ "SignalType" SG_ 882 LftHdlmpDrmPstn "UNM";
BA_ "VNSigAllNodes" SG_ 882 HdlmpLvllngRrSnsrPstn 1;
BA_ "SignalLongName" SG_ 882 HdlmpLvllngRrSnsrPstn "Headlamp Levelling Rear Sensor Position";
BA_ "SignalType" SG_ 882 HdlmpLvllngRrSnsrPstn "SNM";
BA_ "VNSigAllNodes" SG_ 882 HdlmpLvllngFrntSnsrPstn 1;
BA_ "SignalLongName" SG_ 882 HdlmpLvllngFrntSnsrPstn "Headlamp Levelling Front Sensor Position";
BA_ "SignalType" SG_ 882 HdlmpLvllngFrntSnsrPstn "SNM";
BA_ "Prio" BO_ 393 0;
BA_ "GenMsgSendType" BO_ 393 0;
BA_ "GenMsgCycleTime" BO_ 393 25;
BA_ "MessageSubnet" BO_ 393 2;
BA_ "VNSigAllNodes" SG_ 393 TrnsTrqCap 1;
BA_ "SignalLongName" SG_ 393 TrnsTrqCap "Transmission Torque Capacity";
BA_ "SignalType" SG_ 393 TrnsTrqCap "UNM";
BA_ "VNSigAllNodes" SG_ 393 TrnsPdCrkshftTqRqPVa 1;
BA_ "SignalLongName" SG_ 393 TrnsPdCrkshftTqRqPVa "Transmission Predicted Crankshaft Torque Request Protection Value";
BA_ "SignalType" SG_ 393 TrnsPdCrkshftTqRqPVa "UNM";
BA_ "VNSigAllNodes" SG_ 393 TPCTR_TorqReqVal 1;
BA_ "PacketOrder" SG_ 393 TPCTR_TorqReqVal 2;
BA_ "SignalLongName" SG_ 393 TPCTR_TorqReqVal "Transmission Predicted Crankshaft Torque Request : Torque Request Value";
BA_ "SignalType" SG_ 393 TPCTR_TorqReqVal "UNM";
BA_ "VNSigAllNodes" SG_ 393 TPCTR_TrqIntrvnTyp 1;
BA_ "PacketOrder" SG_ 393 TPCTR_TrqIntrvnTyp 1;
BA_ "SignalLongName" SG_ 393 TPCTR_TrqIntrvnTyp "Transmission Predicted Crankshaft Torque Request : Torque Intervention Type";
BA_ "SignalType" SG_ 393 TPCTR_TrqIntrvnTyp "ENM";
BA_ "VNSigAllNodes" SG_ 393 TICTR_TorqRqVal 1;
BA_ "PacketOrder" SG_ 393 TICTR_TorqRqVal 2;
BA_ "SignalLongName" SG_ 393 TICTR_TorqRqVal "Transmission Immediate Crankshaft Torque Request : Torque Request Value";
BA_ "SignalType" SG_ 393 TICTR_TorqRqVal "UNM";
BA_ "VNSigAllNodes" SG_ 393 TICTR_TorqRespTyp 1;
BA_ "PacketOrder" SG_ 393 TICTR_TorqRespTyp 1;
BA_ "SignalLongName" SG_ 393 TICTR_TorqRespTyp "Transmission Immediate Crankshaft Torque Request : Torque Response Type";
BA_ "SignalType" SG_ 393 TICTR_TorqRespTyp "ENM";
BA_ "VNSigAllNodes" SG_ 393 TrnsTrqRqALC 1;
BA_ "SignalLongName" SG_ 393 TrnsTrqRqALC "Transmission Torque Request Alive Rolling Count";
BA_ "SignalType" SG_ 393 TrnsTrqRqALC "UNM";
BA_ "Prio" BO_ 199 0;
BA_ "GenMsgSendType" BO_ 199 0;
BA_ "GenMsgCycleTime" BO_ 199 12;
BA_ "MessageSubnet" BO_ 199 2;
BA_ "VNSigAllNodes" SG_ 199 TORSTimestamp 1;
BA_ "PacketOrder" SG_ 199 TORSTimestamp 6;
BA_ "SignalLongName" SG_ 199 TORSTimestamp "Transmission Output Rotational Status : Transmission Output Rotational Status Timestamp";
BA_ "SignalType" SG_ 199 TORSTimestamp "UNM";
BA_ "VNSigAllNodes" SG_ 199 TORSPulsCntr 1;
BA_ "PacketOrder" SG_ 199 TORSPulsCntr 5;
BA_ "SignalLongName" SG_ 199 TORSPulsCntr "Transmission Output Rotational Status : Transmission Output Rotational Status Pulse Counter";
BA_ "SignalType" SG_ 199 TORSPulsCntr "UNM";
BA_ "VNSigAllNodes" SG_ 199 TORSValidity 1;
BA_ "PacketOrder" SG_ 199 TORSValidity 4;
BA_ "SignalLongName" SG_ 199 TORSValidity "Transmission Output Rotational Status : Transmission Output Rotational Status Validity";
BA_ "SignalType" SG_ 199 TORSValidity "ENM";
BA_ "VNSigAllNodes" SG_ 199 TORSRstOcrd 1;
BA_ "PacketOrder" SG_ 199 TORSRstOcrd 3;
BA_ "SignalLongName" SG_ 199 TORSRstOcrd "Transmission Output Rotational Status : Transmission Output Rotational Status Reset Occurred";
BA_ "SignalType" SG_ 199 TORSRstOcrd "BLN";
BA_ "VNSigAllNodes" SG_ 199 TORSLstTransType 1;
BA_ "PacketOrder" SG_ 199 TORSLstTransType 2;
BA_ "SignalLongName" SG_ 199 TORSLstTransType "Transmission Output Rotational Status : Transmission Output Rotational Status Last Transition Type";
BA_ "SignalType" SG_ 199 TORSLstTransType "ENM";
BA_ "VNSigAllNodes" SG_ 199 TORSRotDir 1;
BA_ "PacketOrder" SG_ 199 TORSRotDir 1;
BA_ "SignalLongName" SG_ 199 TORSRotDir "Transmission Output Rotational Status : Transmission Output Rotational Status Rotation Direction";
BA_ "SignalType" SG_ 199 TORSRotDir "ENM";
BA_ "Prio" BO_ 398 0;
BA_ "GenMsgSendType" BO_ 398 0;
BA_ "GenMsgCycleTime" BO_ 398 12;
BA_ "MessageSubnet" BO_ 398 2;
BA_ "VNSigAllNodes" SG_ 398 EngNTrnsRegStdyStTqV 1;
BA_ "SignalLongName" SG_ 398 EngNTrnsRegStdyStTqV "Engine Non-Transmission Regulated Steady State Torque Validity";
BA_ "SignalType" SG_ 398 EngNTrnsRegStdyStTqV "ENM";
BA_ "VNSigAllNodes" SG_ 398 EngNTrnsRegStdyStTq 1;
BA_ "SignalLongName" SG_ 398 EngNTrnsRegStdyStTq "Engine Non-Transmission Regulated Steady State Torque";
BA_ "SignalType" SG_ 398 EngNTrnsRegStdyStTq "UNM";
BA_ "VNSigAllNodes" SG_ 398 EngActStdyStTorq 1;
BA_ "SignalLongName" SG_ 398 EngActStdyStTorq "Engine Actual Steady State Torque";
BA_ "SignalType" SG_ 398 EngActStdyStTorq "UNM";
BA_ "VNSigAllNodes" SG_ 398 AccKdwnAtv 1;
BA_ "SignalLongName" SG_ 398 AccKdwnAtv "Accelerator Kick Down Detected";
BA_ "SignalType" SG_ 398 AccKdwnAtv "BLN";
BA_ "VNSigAllNodes" SG_ 398 EngActStdyStTorqV 1;
BA_ "SignalLongName" SG_ 398 EngActStdyStTorqV "Engine Actual Steady State Torque Validity";
BA_ "SignalType" SG_ 398 EngActStdyStTorqV "ENM";
BA_ "VNSigAllNodes" SG_ 398 TrnsEngSpdReqFld 1;
BA_ "SignalLongName" SG_ 398 TrnsEngSpdReqFld "Transmission Engine Speed Request Failed";
BA_ "SignalType" SG_ 398 TrnsEngSpdReqFld "BLN";
BA_ "VNSigAllNodes" SG_ 398 PTACCAct 1;
BA_ "SignalLongName" SG_ 398 PTACCAct "Powertrain Adaptive Cruise Control Active";
BA_ "SignalType" SG_ 398 PTACCAct "BLN";
BA_ "VNSigAllNodes" SG_ 398 CTSS_StbltyLvl 1;
BA_ "PacketOrder" SG_ 398 CTSS_StbltyLvl 2;
BA_ "SignalLongName" SG_ 398 CTSS_StbltyLvl "Crankshaft Torque Stability Status : Stability Level";
BA_ "SignalType" SG_ 398 CTSS_StbltyLvl "ENM";
BA_ "VNSigAllNodes" SG_ 398 CTSS_StbltyTyp 1;
BA_ "PacketOrder" SG_ 398 CTSS_StbltyTyp 1;
BA_ "SignalLongName" SG_ 398 CTSS_StbltyTyp "Crankshaft Torque Stability Status : Stability Type";
BA_ "SignalType" SG_ 398 CTSS_StbltyTyp "ENM";
BA_ "VNSigAllNodes" SG_ 398 CrksftNTrnsRegCmdTq 1;
BA_ "SignalLongName" SG_ 398 CrksftNTrnsRegCmdTq "Crankshaft Non-Transmission Regulated Commanded Torque";
BA_ "SignalType" SG_ 398 CrksftNTrnsRegCmdTq "UNM";
BA_ "VNSigAllNodes" SG_ 398 EngImmTrqTnsRqStat 1;
BA_ "SignalLongName" SG_ 398 EngImmTrqTnsRqStat "Engine Immediate Torque Transmission Request Status";
BA_ "SignalType" SG_ 398 EngImmTrqTnsRqStat "ENM";
BA_ "VNSigAllNodes" SG_ 398 EngImmTrqTnsRqLmSt 1;
BA_ "SignalLongName" SG_ 398 EngImmTrqTnsRqLmSt "Engine Immediate Torque Transmission Request Limiting Status";
BA_ "SignalType" SG_ 398 EngImmTrqTnsRqLmSt "ENM";
BA_ "VNSigAllNodes" SG_ 398 EngPrdctTrqTnsRqStat 1;
BA_ "SignalLongName" SG_ 398 EngPrdctTrqTnsRqStat "Engine Predicted Torque Transmission Request Status";
BA_ "SignalType" SG_ 398 EngPrdctTrqTnsRqStat "ENM";
BA_ "VNSigAllNodes" SG_ 398 EngPrdctTrqTnsRqLmS 1;
BA_ "SignalLongName" SG_ 398 EngPrdctTrqTnsRqLmS "Engine Predicted Torque Transmission Request Limiting Status";
BA_ "SignalType" SG_ 398 EngPrdctTrqTnsRqLmS "ENM";
BA_ "Prio" BO_ 464 0;
BA_ "GenMsgSendType" BO_ 464 0;
BA_ "GenMsgCycleTime" BO_ 464 20;
BA_ "MessageSubnet" BO_ 464 2;
BA_ "VNSigAllNodes" SG_ 464 FrtAxlOpeMod 1;
BA_ "SignalLongName" SG_ 464 FrtAxlOpeMod "Front Axle Operational Mode";
BA_ "SignalType" SG_ 464 FrtAxlOpeMod "ENM";
BA_ "Prio" BO_ 390 0;
BA_ "GenMsgSendType" BO_ 390 0;
BA_ "GenMsgCycleTime" BO_ 390 12;
BA_ "MessageSubnet" BO_ 390 2;
BA_ "VNSigAllNodes" SG_ 390 RdHVInvRatVltV 1;
BA_ "SignalLongName" SG_ 390 RdHVInvRatVltV "Redundant High Voltage Inverter Rationalized Voltage Validity";
BA_ "SignalType" SG_ 390 RdHVInvRatVltV "ENM";
BA_ "VNSigAllNodes" SG_ 390 RdHVInvRatVlt 1;
BA_ "SignalLongName" SG_ 390 RdHVInvRatVlt "Redundant High Voltage Inverter Rationalized Voltage";
BA_ "SignalType" SG_ 390 RdHVInvRatVlt "UNM";
BA_ "VNSigAllNodes" SG_ 390 EngActDmpgDsblReq 1;
BA_ "SignalLongName" SG_ 390 EngActDmpgDsblReq "Engine Active Damping Disable Requested";
BA_ "SignalType" SG_ 390 EngActDmpgDsblReq "BLN";
BA_ "VNSigAllNodes" SG_ 390 HybExtndDcFuelCORq 1;
BA_ "SignalLongName" SG_ 390 HybExtndDcFuelCORq "Hybrid Extended Deceleration Fuel Cut Off Requested";
BA_ "SignalType" SG_ 390 HybExtndDcFuelCORq "BLN";
BA_ "VNSigAllNodes" SG_ 390 EstMtrPwrLossV 1;
BA_ "SignalLongName" SG_ 390 EstMtrPwrLossV "Estimated Motor Power Loss Validity";
BA_ "SignalType" SG_ 390 EstMtrPwrLossV "ENM";
BA_ "VNSigAllNodes" SG_ 390 EstMtrPwrLoss 1;
BA_ "SignalLongName" SG_ 390 EstMtrPwrLoss "Estimated Motor Power Loss";
BA_ "SignalType" SG_ 390 EstMtrPwrLoss "UNM";
BA_ "VNSigAllNodes" SG_ 390 HybCmmFailRdPwrCmd 1;
BA_ "SignalLongName" SG_ 390 HybCmmFailRdPwrCmd "Hybrid Communication Failure Reduced Power Commanded";
BA_ "SignalType" SG_ 390 HybCmmFailRdPwrCmd "BLN";
BA_ "VNSigAllNodes" SG_ 390 HybCmmdEngTrqLmtd 1;
BA_ "SignalLongName" SG_ 390 HybCmmdEngTrqLmtd "Hybrid Commanded Engine Torque Limited";
BA_ "SignalType" SG_ 390 HybCmmdEngTrqLmtd "UNM";
BA_ "VNSigAllNodes" SG_ 390 HybACCompRq 1;
BA_ "SignalLongName" SG_ 390 HybACCompRq "Hybrid Air Conditioning Compressor Request";
BA_ "SignalType" SG_ 390 HybACCompRq "ENM";
BA_ "VNSigAllNodes" SG_ 390 HESSI_EngStrtTyp 1;
BA_ "PacketOrder" SG_ 390 HESSI_EngStrtTyp 2;
BA_ "SignalLongName" SG_ 390 HESSI_EngStrtTyp "Hybrid Engine Start Stop Information : Engine Start Type";
BA_ "SignalType" SG_ 390 HESSI_EngStrtTyp "ENM";
BA_ "VNSigAllNodes" SG_ 390 HESSI_EngStrtStpMd 1;
BA_ "PacketOrder" SG_ 390 HESSI_EngStrtStpMd 1;
BA_ "SignalLongName" SG_ 390 HESSI_EngStrtStpMd "Hybrid Engine Start Stop Information : Engine Start Stop Mode";
BA_ "SignalType" SG_ 390 HESSI_EngStrtStpMd "ENM";
BA_ "VNSigAllNodes" SG_ 390 HybCrnkAbrtd 1;
BA_ "SignalLongName" SG_ 390 HybCrnkAbrtd "Hybrid Crank Aborted";
BA_ "SignalType" SG_ 390 HybCrnkAbrtd "BLN";
BA_ "VNSigAllNodes" SG_ 390 CnvntlEngStrtEnbld 1;
BA_ "SignalLongName" SG_ 390 CnvntlEngStrtEnbld "Conventional Engine Start Enabled";
BA_ "SignalType" SG_ 390 CnvntlEngStrtEnbld "BLN";
BA_ "VNSigAllNodes" SG_ 390 HybEngCylDeactReq 1;
BA_ "SignalLongName" SG_ 390 HybEngCylDeactReq "Hybrid Engine Cylinder Deactivation Requested";
BA_ "SignalType" SG_ 390 HybEngCylDeactReq "BLN";
BA_ "VNSigAllNodes" SG_ 390 HybDFCOReq 1;
BA_ "SignalLongName" SG_ 390 HybDFCOReq "Hybrid Deceleration Fuel Cut Off Request";
BA_ "SignalType" SG_ 390 HybDFCOReq "ENM";
BA_ "VNSigAllNodes" SG_ 390 RdPTHVCntrReq 1;
BA_ "SignalLongName" SG_ 390 RdPTHVCntrReq "Redundant Powertrain High Voltage Contactor Request";
BA_ "SignalType" SG_ 390 RdPTHVCntrReq "ENM";
BA_ "Prio" BO_ 817 0;
BA_ "GenMsgSendType" BO_ 817 0;
BA_ "GenMsgCycleTime" BO_ 817 100;
BA_ "MessageSubnet" BO_ 817 2;
BA_ "VNSigAllNodes" SG_ 817 RrDrvlnSysVehTpSpdLmVal 1;
BA_ "SignalLongName" SG_ 817 RrDrvlnSysVehTpSpdLmVal "Rear Driveline System Vehicle Top Speed Limit Value";
BA_ "SignalType" SG_ 817 RrDrvlnSysVehTpSpdLmVal "UNM";
BA_ "VNSigAllNodes" SG_ 817 RrAxlTmpInhIO 1;
BA_ "SignalLongName" SG_ 817 RrAxlTmpInhIO "Rear Axle Temporary Inhibit Indication On";
BA_ "SignalType" SG_ 817 RrAxlTmpInhIO "BLN";
BA_ "VNSigAllNodes" SG_ 817 RrAxlMalfIO 1;
BA_ "SignalLongName" SG_ 817 RrAxlMalfIO "Rear Axle Malfunction Indication On";
BA_ "SignalType" SG_ 817 RrAxlMalfIO "BLN";
BA_ "Prio" BO_ 465 0;
BA_ "GenMsgSendType" BO_ 465 0;
BA_ "GenMsgCycleTime" BO_ 465 20;
BA_ "MessageSubnet" BO_ 465 2;
BA_ "VNSigAllNodes" SG_ 465 RrAxlOpeMod 1;
BA_ "SignalLongName" SG_ 465 RrAxlOpeMod "Rear Axle Operational Mode";
BA_ "SignalType" SG_ 465 RrAxlOpeMod "ENM";
BA_ "VNSigAllNodes" SG_ 465 RrAxlEstTrqV 1;
BA_ "SignalLongName" SG_ 465 RrAxlEstTrqV "Rear Axle Estimated Torque Validity";
BA_ "SignalType" SG_ 465 RrAxlEstTrqV "ENM";
BA_ "VNSigAllNodes" SG_ 465 RrAxlEstTrq 1;
BA_ "SignalLongName" SG_ 465 RrAxlEstTrq "Rear Axle Estimated Torque";
BA_ "SignalType" SG_ 465 RrAxlEstTrq "SNM";
BA_ "VNSigAllNodes" SG_ 465 RrAxlStat 1;
BA_ "SignalLongName" SG_ 465 RrAxlStat "Rear Axle Status";
BA_ "SignalType" SG_ 465 RrAxlStat "ENM";
BA_ "VNSigAllNodes" SG_ 465 RrAxlCtrlMod 1;
BA_ "SignalLongName" SG_ 465 RrAxlCtrlMod "Rear Axle Control Mode";
BA_ "SignalType" SG_ 465 RrAxlCtrlMod "ENM";
BA_ "VNSigAllNodes" SG_ 465 RAMDVLReqVal 1;
BA_ "SignalLongName" SG_ 465 RAMDVLReqVal "Rear Axle Maximum Differential Velocity Limit : Request Value";
BA_ "SignalType" SG_ 465 RAMDVLReqVal "UNM";
BA_ "VNSigAllNodes" SG_ 465 RAMDVLAtv 1;
BA_ "SignalLongName" SG_ 465 RAMDVLAtv "Rear Axle Maximum Differential Velocity Limit : Active";
BA_ "SignalType" SG_ 465 RAMDVLAtv "BLN";
BA_ "Prio" BO_ 460 0;
BA_ "GenMsgSendType" BO_ 460 0;
BA_ "GenMsgCycleTime" BO_ 460 20;
BA_ "MessageSubnet" BO_ 460 2;
BA_ "VNSigAllNodes" SG_ 460 SecAxlStat 1;
BA_ "SignalLongName" SG_ 460 SecAxlStat "Secondary Axle Status";
BA_ "SignalType" SG_ 460 SecAxlStat "ENM";
BA_ "VNSigAllNodes" SG_ 460 SecAxlEstTrqV 1;
BA_ "SignalLongName" SG_ 460 SecAxlEstTrqV "Secondary Axle Estimated Torque Validity";
BA_ "SignalType" SG_ 460 SecAxlEstTrqV "ENM";
BA_ "VNSigAllNodes" SG_ 460 SecAxlEstTrq 1;
BA_ "SignalLongName" SG_ 460 SecAxlEstTrq "Secondary Axle Estimated Torque";
BA_ "SignalType" SG_ 460 SecAxlEstTrq "UNM";
BA_ "VNSigAllNodes" SG_ 460 SAMDVLReqVal 1;
BA_ "SignalLongName" SG_ 460 SAMDVLReqVal "Secondary Axle Maximum Differential Velocity Limit : Request Value";
BA_ "SignalType" SG_ 460 SAMDVLReqVal "UNM";
BA_ "VNSigAllNodes" SG_ 460 SAMDVLAtv 1;
BA_ "SignalLongName" SG_ 460 SAMDVLAtv "Secondary Axle Maximum Differential Velocity Limit : Active";
BA_ "SignalType" SG_ 460 SAMDVLAtv "BLN";
BA_ "VNSigAllNodes" SG_ 460 PTTrnsfrCseMd 1;
BA_ "SignalLongName" SG_ 460 PTTrnsfrCseMd "Powertrain Transfer Case Mode";
BA_ "SignalType" SG_ 460 PTTrnsfrCseMd "ENM";
BA_ "VNSigAllNodes" SG_ 460 SecAxlCtrlMod 1;
BA_ "SignalLongName" SG_ 460 SecAxlCtrlMod "Secondary Axle Control Mode";
BA_ "SignalType" SG_ 460 SecAxlCtrlMod "ENM";
BA_ "Prio" BO_ 462 0;
BA_ "GenMsgSendType" BO_ 462 0;
BA_ "GenMsgCycleTime" BO_ 462 20;
BA_ "MessageSubnet" BO_ 462 2;
BA_ "VNSigAllNodes" SG_ 462 SecAxlTrqReqProtVal 1;
BA_ "SignalLongName" SG_ 462 SecAxlTrqReqProtVal "Secondary Axle Torque Request Protection Value";
BA_ "SignalType" SG_ 462 SecAxlTrqReqProtVal "UNM";
BA_ "VNSigAllNodes" SG_ 462 SecAxlTrqReqARollCnt 1;
BA_ "SignalLongName" SG_ 462 SecAxlTrqReqARollCnt "Secondary Axle Torque Request Alive Rolling Count";
BA_ "SignalType" SG_ 462 SecAxlTrqReqARollCnt "UNM";
BA_ "VNSigAllNodes" SG_ 462 SATRCplReqVal 1;
BA_ "PacketOrder" SG_ 462 SATRCplReqVal 1;
BA_ "SignalLongName" SG_ 462 SATRCplReqVal "Secondary Axle Torque Request : Coupling Request Value";
BA_ "SignalType" SG_ 462 SATRCplReqVal "UNM";
BA_ "VNSigAllNodes" SG_ 462 SATRCplReqAtv 1;
BA_ "SignalLongName" SG_ 462 SATRCplReqAtv "Secondary Axle Torque Request : Coupling Request Active";
BA_ "SignalType" SG_ 462 SATRCplReqAtv "BLN";
BA_ "Prio" BO_ 463 0;
BA_ "GenMsgSendType" BO_ 463 0;
BA_ "GenMsgCycleTime" BO_ 463 100;
BA_ "MessageSubnet" BO_ 463 2;
BA_ "VNSigAllNodes" SG_ 463 FourWhlDrvIndReq 1;
BA_ "SignalLongName" SG_ 463 FourWhlDrvIndReq "Four Wheel Drive Indication Request";
BA_ "SignalType" SG_ 463 FourWhlDrvIndReq "ENM";
BA_ "VNSigAllNodes" SG_ 463 TrnsfrCsRngShfSpdLmt 1;
BA_ "SignalLongName" SG_ 463 TrnsfrCsRngShfSpdLmt "Transfer Case Range Shift Speed Limit";
BA_ "SignalType" SG_ 463 TrnsfrCsRngShfSpdLmt "UNM";
BA_ "VNSigAllNodes" SG_ 463 SecAxlNonEmMalfIO 1;
BA_ "SignalLongName" SG_ 463 SecAxlNonEmMalfIO "Secondary Axle Non-emissions Malf Ind On";
BA_ "SignalType" SG_ 463 SecAxlNonEmMalfIO "BLN";
BA_ "VNSigAllNodes" SG_ 463 SecAxlOperMod 1;
BA_ "SignalLongName" SG_ 463 SecAxlOperMod "Secondary Axle Operational Mode";
BA_ "SignalType" SG_ 463 SecAxlOperMod "ENM";
BA_ "VNSigAllNodes" SG_ 463 SecAxlTmpInhIO 1;
BA_ "SignalLongName" SG_ 463 SecAxlTmpInhIO "Secondary Axle Temporary Inhibit Indication On";
BA_ "SignalType" SG_ 463 SecAxlTmpInhIO "BLN";
BA_ "AppGenMsgCycleTime" BO_ 719 40;
BA_ "Prio" BO_ 719 0;
BA_ "MessageSubnet" BO_ 719 2;
BA_ "VNSigAllNodes" SG_ 719 RrVrtlBmpAxlTrqCmdRC 1;
BA_ "SignalLongName" SG_ 719 RrVrtlBmpAxlTrqCmdRC "Rear Virtual Bumper Axle Torque Command Rolling Count";
BA_ "SignalType" SG_ 719 RrVrtlBmpAxlTrqCmdRC "UNM";
BA_ "VNSigAllNodes" SG_ 719 RrVrtlBmpAxlTrqCmdProtVal 1;
BA_ "SignalLongName" SG_ 719 RrVrtlBmpAxlTrqCmdProtVal "Rear Virtual Bumper Axle Torque Command Protection Value";
BA_ "SignalType" SG_ 719 RrVrtlBmpAxlTrqCmdProtVal "UNM";
BA_ "VNSigAllNodes" SG_ 719 RVBATC_AxlTrqRqstAct 1;
BA_ "PacketOrder" SG_ 719 RVBATC_AxlTrqRqstAct 1;
BA_ "SignalLongName" SG_ 719 RVBATC_AxlTrqRqstAct "Rear Virtual Bumper Axle Torque Command : Axle Torque Request Active";
BA_ "SignalType" SG_ 719 RVBATC_AxlTrqRqstAct "BLN";
BA_ "VNSigAllNodes" SG_ 719 RVBATC_AxlTrqRqst 1;
BA_ "PacketOrder" SG_ 719 RVBATC_AxlTrqRqst 2;
BA_ "SignalLongName" SG_ 719 RVBATC_AxlTrqRqst "Rear Virtual Bumper Axle Torque Command : Axle Torque Request";
BA_ "GenSigStartValue" SG_ 719 RVBATC_AxlTrqRqst 32767;
BA_ "SignalType" SG_ 719 RVBATC_AxlTrqRqst "UNM";
